VERSION "j1939-2025-03-v2.4-light"

NS_ :

BS_:

BU_:

BO_ 2566799614 LD: 8 Vector__XXX
 SG_ AlternateBeamHeadLightData : 2|2@1+ (1,0) [0|3] "" Vector__XXX
 SG_ BackUpLightAndAlarmHorn : 16|2@1+ (1,0) [0|3] "" Vector__XXX
 SG_ CenterStopLight : 18|2@1+ (1,0) [0|3] "" Vector__XXX
 SG_ HighBeamHeadLightData : 6|2@1+ (1,0) [0|3] "" Vector__XXX
 SG_ ImplementClearanceLight : 24|2@1+ (1,0) [0|3] "" Vector__XXX
 SG_ ImplementLeftFacingWorkLight : 60|2@1+ (1,0) [0|3] "" Vector__XXX
 SG_ ImplementLeftForwardWorkLight : 54|2@1+ (1,0) [0|3] "" Vector__XXX
 SG_ ImplementMarkerLight : 28|2@1+ (1,0) [0|3] "" Vector__XXX
 SG_ ImplementOemOption1Light : 50|2@1+ (1,0) [0|3] "" Vector__XXX
 SG_ ImplementOemOption2Light : 48|2@1+ (1,0) [0|3] "" Vector__XXX
 SG_ ImplementRearWorkLight : 62|2@1+ (1,0) [0|3] "" Vector__XXX
 SG_ ImplementRightFacingWorkLight : 52|2@1+ (1,0) [0|3] "" Vector__XXX
 SG_ ImplementRightForwardWorkLight : 58|2@1+ (1,0) [0|3] "" Vector__XXX
 SG_ LeftStopLight : 22|2@1+ (1,0) [0|3] "" Vector__XXX
 SG_ LeftTurnSignalLights : 14|2@1+ (1,0) [0|3] "" Vector__XXX
 SG_ LowBeamHeadLightData : 4|2@1+ (1,0) [0|3] "" Vector__XXX
 SG_ RearFogLights : 32|2@1+ (1,0) [0|3] "" Vector__XXX
 SG_ RightStopLight : 20|2@1+ (1,0) [0|3] "" Vector__XXX
 SG_ RightTurnSignalLights : 12|2@1+ (1,0) [0|3] "" Vector__XXX
 SG_ RotatingBeaconLight : 10|2@1+ (1,0) [0|3] "" Vector__XXX
 SG_ RunningLight : 0|2@1+ (1,0) [0|3] "" Vector__XXX
 SG_ TractorClearanceLight : 26|2@1+ (1,0) [0|3] "" Vector__XXX
 SG_ TractorFrontFogLights : 8|2@1+ (1,0) [0|3] "" Vector__XXX
 SG_ TractorMarkerLight : 30|2@1+ (1,0) [0|3] "" Vector__XXX
 SG_ TractorRearLowMountedWorkLights : 36|2@1+ (1,0) [0|3] "" Vector__XXX
 SG_ TractorSideLowMountedWorkLights : 40|2@1+ (1,0) [0|3] "" Vector__XXX
 SG_ TrtrFrntHghMntdWrkLghts : 46|2@1+ (1,0) [0|3] "" Vector__XXX
 SG_ TrtrFrntLwMntdWrkLghts : 44|2@1+ (1,0) [0|3] "" Vector__XXX
 SG_ TrtrRrHghMntdWrkLghts : 38|2@1+ (1,0) [0|3] "" Vector__XXX
 SG_ TrtrSdHghMntdWrkLghts : 42|2@1+ (1,0) [0|3] "" Vector__XXX
 SG_ TrtrUndrsdMntdWrkLghts : 34|2@1+ (1,0) [0|3] "" Vector__XXX

BO_ 2566802174 ETC7: 8 Vector__XXX
 SG_ ActiveShiftConsoleIndicator : 10|2@1+ (1,0) [0|3] "" Vector__XXX
 SG_ TransmissionEngineCrankEnable : 12|2@1+ (1,0) [0|3] "" Vector__XXX
 SG_ TransmissionManualModeIndicator : 54|2@1+ (1,0) [0|3] "" Vector__XXX
 SG_ TransmissionMode10Indicator : 46|2@1+ (1,0) [0|3] "" Vector__XXX
 SG_ TransmissionMode1Indicator : 22|2@1+ (1,0) [0|3] "" Vector__XXX
 SG_ TransmissionMode2Indicator : 20|2@1+ (1,0) [0|3] "" Vector__XXX
 SG_ TransmissionMode3Indicator : 18|2@1+ (1,0) [0|3] "" Vector__XXX
 SG_ TransmissionMode4Indicator : 16|2@1+ (1,0) [0|3] "" Vector__XXX
 SG_ TransmissionMode5Indicator : 32|2@1+ (1,0) [0|3] "" Vector__XXX
 SG_ TransmissionMode6Indicator : 34|2@1+ (1,0) [0|3] "" Vector__XXX
 SG_ TransmissionMode7Indicator : 36|2@1+ (1,0) [0|3] "" Vector__XXX
 SG_ TransmissionMode8Indicator : 38|2@1+ (1,0) [0|3] "" Vector__XXX
 SG_ TransmissionMode9Indicator : 44|2@1+ (1,0) [0|3] "" Vector__XXX
 SG_ TransmissionServiceIndicator : 2|2@1+ (1,0) [0|3] "" Vector__XXX
 SG_ TransmissionWarningIndicator : 42|2@1+ (1,0) [0|3] "" Vector__XXX
 SG_ TrnsmssnArSpplPrssrIndtr : 48|3@1+ (1,0) [0|7] "" Vector__XXX
 SG_ TrnsmssnAtNtrlMnlRtrnStt : 51|3@1+ (1,0) [0|7] "" Vector__XXX
 SG_ TrnsmssnCrrntRngDsplBlnkStt : 0|2@1+ (1,0) [0|3] "" Vector__XXX
 SG_ TrnsmssnRdFrBrkRls : 8|2@1+ (1,0) [0|3] "" Vector__XXX
 SG_ TrnsmssnRqstdGrFdk : 24|8@1+ (1,-125) [-125|125] "gear value" Vector__XXX
 SG_ TrnsmssnRqstdRngDsplBlnkStt : 4|2@1+ (1,0) [0|3] "" Vector__XXX
 SG_ TrnsmssnRqstdRngDsplFlshStt : 6|2@1+ (1,0) [0|3] "" Vector__XXX
 SG_ TrnsmssnRvrsGrShftInhtStts : 40|2@1+ (1,0) [0|3] "" Vector__XXX
 SG_ TrnsmssnShftInhtIndtr : 14|2@1+ (1,0) [0|3] "" Vector__XXX
 SG_ TrnsmssnLdRdtnIndtr : 56|2@1+ (1,0) [0|3] "" Vector__XXX
 SG_ TrnsmssnPrDfndRngLmtIndtr : 58|2@1+ (1,0) [0|3] "" Vector__XXX
 SG_ TransmissionCoastModeIndicator : 60|2@1+ (1,0) [0|3] "" Vector__XXX
 SG_ TrnsmssnOtptShftBrkIndtr : 62|2@1+ (1,0) [0|3] "" Vector__XXX

BO_ 2566802430 TCFG2: 8 Vector__XXX
 SG_ TransmissionReferenceTorque : 16|16@1+ (1,0) [0|64255] "Nm" Vector__XXX
 SG_ TransmissionTorqueLimit : 0|16@1+ (1,0) [0|64255] "Nm" Vector__XXX
 SG_ TrnsmssnCmmntnsFlrIdlTrqLmt : 32|8@1+ (1,-125) [0|125] "%" Vector__XXX
 SG_ TransmissionShiftSelectorType : 40|3@1+ (1,0) [0|7] "" Vector__XXX
 SG_ TransmissionSpeedLimit : 48|16@1+ (0.125,0) [0|8031.875] "rpm" Vector__XXX

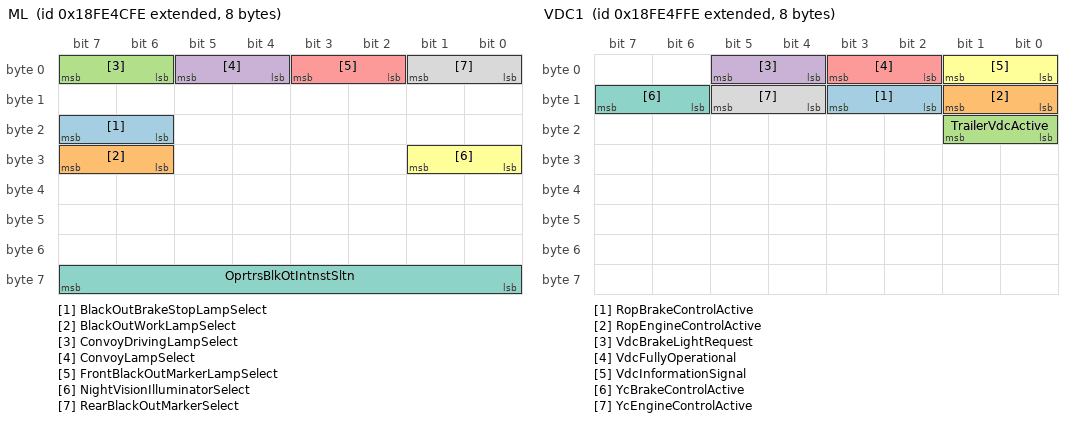
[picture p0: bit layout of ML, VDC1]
BO_ 2566802686 ML: 8 Vector__XXX
 SG_ BlackOutBrakeStopLampSelect : 22|2@1+ (1,0) [0|3] "" Vector__XXX
 SG_ BlackOutWorkLampSelect : 30|2@1+ (1,0) [0|3] "" Vector__XXX
 SG_ ConvoyDrivingLampSelect : 6|2@1+ (1,0) [0|3] "" Vector__XXX
 SG_ ConvoyLampSelect : 4|2@1+ (1,0) [0|3] "" Vector__XXX
 SG_ FrontBlackOutMarkerLampSelect : 2|2@1+ (1,0) [0|3] "" Vector__XXX
 SG_ NightVisionIlluminatorSelect : 24|2@1+ (1,0) [0|3] "" Vector__XXX
 SG_ OprtrsBlkOtIntnstSltn : 56|8@1+ (0.4,0) [0|100] "%" Vector__XXX
 SG_ RearBlackOutMarkerSelect : 0|2@1+ (1,0) [0|3] "" Vector__XXX

BO_ 2566803198 DC1: 8 Vector__XXX
 SG_ PositionOfDoors : 0|4@1+ (1,0) [0|15] "" Vector__XXX
 SG_ RampWheelChairLiftPosition : 4|2@1+ (1,0) [0|3] "" Vector__XXX
 SG_ Status2OfDoors : 6|2@1+ (1,0) [0|3] "" Vector__XXX

BO_ 2566803454 VDC1: 8 Vector__XXX
 SG_ RopBrakeControlActive : 10|2@1+ (1,0) [0|3] "" Vector__XXX
 SG_ RopEngineControlActive : 8|2@1+ (1,0) [0|3] "" Vector__XXX
 SG_ TrailerVdcActive : 16|2@1+ (1,0) [0|3] "" Vector__XXX
 SG_ VdcBrakeLightRequest : 4|2@1+ (1,0) [0|3] "" Vector__XXX
 SG_ VdcFullyOperational : 2|2@1+ (1,0) [0|3] "" Vector__XXX
 SG_ VdcInformationSignal : 0|2@1+ (1,0) [0|3] "" Vector__XXX
 SG_ YcBrakeControlActive : 14|2@1+ (1,0) [0|3] "" Vector__XXX
 SG_ YcEngineControlActive : 12|2@1+ (1,0) [0|3] "" Vector__XXX

BO_ 2566803710 BT1: 8 Vector__XXX
 SG_ SliBattery1Temperature : 0|8@1+ (1,-40) [-40|210] "degC" Vector__XXX
 SG_ SliBattery2Temperature : 8|8@1+ (1,-40) [-40|210] "degC" Vector__XXX
 SG_ SliBattery3Temperature : 16|8@1+ (1,-40) [-40|210] "degC" Vector__XXX
 SG_ SliBattery4Temperature : 24|8@1+ (1,-40) [-40|210] "degC" Vector__XXX

BO_ 2566803966 ACC2: 8 Vector__XXX
 SG_ AccUsageDemand : 0|2@1+ (1,0) [0|3] "" Vector__XXX
 SG_ RequestedAccDistanceMode : 5|3@1+ (1,0) [0|7] "" Vector__XXX

BO_ 2566804222 VEP3: 8 Vector__XXX
 SG_ AltrntrCrrntHghRngRsltn : 0|16@1+ (0.05,-1600) [-1600|1612.75] "A" Vector__XXX
 SG_ SliBattery2NetCurrent : 32|16@1+ (0.05,-1600) [-1600|1612.75] "A" Vector__XXX
 SG_ SlBttr1NtCrrntHghRngRsltn : 16|16@1+ (0.05,-1600) [-1600|1612.75] "A" Vector__XXX
 SG_ EcuKeySwitchState : 48|2@1+ (1,0) [0|3] "" Vector__XXX

BO_ 2566804478 RTC1: 8 Vector__XXX
 SG_ LwLmtThrshldFrMxmmRpmFrmRtrdr : 0|8@1+ (32,0) [0|8000] "rpm" Vector__XXX
 SG_ LwLmtThrshldFrMxmmTrqFrmRtrdr : 16|8@1+ (1,-125) [-125|125] "%" Vector__XXX
 SG_ MaximumContinuousRetarderSpeed : 32|8@1+ (32,0) [0|8000] "rpm" Vector__XXX
 SG_ MaximumContinuousRetarderTorque : 48|8@1+ (1,-125) [-125|125] "%" Vector__XXX
 SG_ MinimumContinuousRetarderSpeed : 40|8@1+ (32,0) [0|8000] "rpm" Vector__XXX
 SG_ MinimumContinuousRetarderTorque : 56|8@1+ (1,-125) [-125|125] "%" Vector__XXX
 SG_ HLtTsdFMCtsRpFRtd : 8|8@1+ (32,0) [0|8000] "rpm" Vector__XXX
 SG_ HLtTsdFMCtsTqFRtd : 24|8@1+ (1,-125) [-125|125] "%" Vector__XXX

BO_ 2566804734 ECT1: 8 Vector__XXX
 SG_ EngineMaximumContinuousRpm : 32|8@1+ (32,0) [0|8000] "rpm" Vector__XXX
 SG_ EngineMaximumContinuousTorque : 48|8@1+ (1,-125) [-125|125] "%" Vector__XXX
 SG_ EngineMinimumContinuousRpm : 40|8@1+ (32,0) [0|8000] "rpm" Vector__XXX
 SG_ EngineMinimumContinuousTorque : 56|8@1+ (1,-125) [-125|125] "%" Vector__XXX
 SG_ ELwLtTsdFMxRpFE : 0|8@1+ (32,0) [0|8000] "rpm" Vector__XXX
 SG_ EHLtTsdFMCtsERp : 8|8@1+ (32,0) [0|8000] "rpm" Vector__XXX
 SG_ ELwLtTsdFMxTqFE : 16|8@1+ (1,-125) [-125|125] "%" Vector__XXX
 SG_ EHLtTsdFMCtsTqFE : 24|8@1+ (1,-125) [-125|125] "%" Vector__XXX

BO_ 2566804990 GFD: 8 Vector__XXX
 SG_ FuelEnergyContent : 32|16@1+ (0.00390625,0) [0|250.99609375] "MJ/(Nm*Nm*Nm)" Vector__XXX
 SG_ ReferenceEngineGasMassFlowRate : 16|16@1+ (0.05,0) [0|3212.75] "kg/h" Vector__XXX
 SG_ SpecificHeatRatio : 0|16@1+ (0.001,0) [0|2] "" Vector__XXX

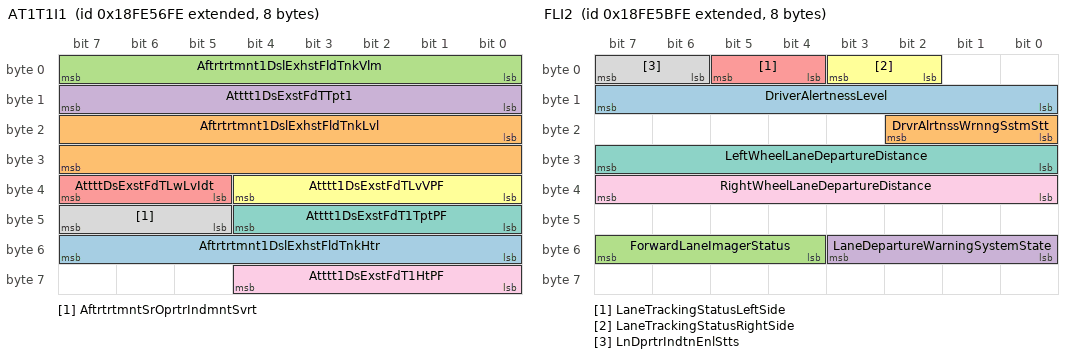
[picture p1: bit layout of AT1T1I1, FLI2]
BO_ 2566805246 AT1T1I1: 8 Vector__XXX
 SG_ Aftrtrtmnt1DslExhstFldTnkHtr : 48|8@1+ (0.4,0) [0|100] "%" Vector__XXX
 SG_ Aftrtrtmnt1DslExhstFldTnkLvl : 16|16@1+ (0.1,0) [0|6425.5] "mm" Vector__XXX
 SG_ Aftrtrtmnt1DslExhstFldTnkVlm : 0|8@1+ (0.4,0) [0|100] "%" Vector__XXX
 SG_ Atttt1DsExstFdTTpt1 : 8|8@1+ (1,-40) [-40|210] "degC" Vector__XXX
 SG_ AttttDsExstFdTLwLvIdt : 37|3@1+ (1,0) [0|7] "" Vector__XXX
 SG_ Atttt1DsExstFdTLvVPF : 32|5@1+ (1,0) [0|31] "" Vector__XXX
 SG_ Atttt1DsExstFdT1TptPF : 40|5@1+ (1,0) [0|31] "" Vector__XXX
 SG_ AftrtrtmntSrOprtrIndmntSvrt : 45|3@1+ (1,0) [0|7] "" Vector__XXX
 SG_ Atttt1DsExstFdT1HtPF : 56|5@1+ (1,0) [0|31] "" Vector__XXX

BO_ 2566805758 ASC4: 8 Vector__XXX
 SG_ BellowPressureFrontAxleLeft : 0|16@1+ (0.1,0) [0|6425.5] "kPa" Vector__XXX
 SG_ BellowPressureFrontAxleRight : 16|16@1+ (0.1,0) [0|6425.5] "kPa" Vector__XXX
 SG_ BellowPressureRearAxleLeft : 32|16@1+ (0.1,0) [0|6425.5] "kPa" Vector__XXX
 SG_ BellowPressureRearAxleRight : 48|16@1+ (0.1,0) [0|6425.5] "kPa" Vector__XXX

BO_ 2566806014 ASC3: 8 Vector__XXX
 SG_ RelativeLevelFrontAxleLeft : 0|16@1+ (0.1,-3200) [-3200|3225.5] "mm" Vector__XXX
 SG_ RelativeLevelFrontAxleRight : 16|16@1+ (0.1,-3200) [-3200|3225.5] "mm" Vector__XXX
 SG_ RelativeLevelRearAxleLeft : 32|16@1+ (0.1,-3200) [-3200|3225.5] "mm" Vector__XXX
 SG_ RelativeLevelRearAxleRight : 48|16@1+ (0.1,-3200) [-3200|3225.5] "mm" Vector__XXX

BO_ 2566806526 FLI2: 8 Vector__XXX
 SG_ DriverAlertnessLevel : 8|8@1+ (0.4,0) [0|100] "%" Vector__XXX
 SG_ DrvrAlrtnssWrnngSstmStt : 16|3@1+ (1,0) [0|7] "" Vector__XXX
 SG_ ForwardLaneImagerStatus : 52|4@1+ (1,0) [0|15] "" Vector__XXX
 SG_ LaneDepartureWarningSystemState : 48|4@1+ (1,0) [0|15] "" Vector__XXX
 SG_ LaneTrackingStatusLeftSide : 4|2@1+ (1,0) [0|3] "" Vector__XXX
 SG_ LaneTrackingStatusRightSide : 2|2@1+ (1,0) [0|3] "" Vector__XXX
 SG_ LeftWheelLaneDepartureDistance : 24|8@1+ (1,-125) [-125|125] "cm" Vector__XXX
 SG_ LnDprtrIndtnEnlStts : 6|2@1+ (1,0) [0|3] "" Vector__XXX
 SG_ RightWheelLaneDepartureDistance : 32|8@1+ (1,-125) [-125|125] "cm" Vector__XXX

BO_ 2566809342 BM: 8 Vector__XXX
 SG_ BatteryMainSwitchHoldState : 0|2@1+ (1,0) [0|3] "" Vector__XXX

BO_ 2566809598 CCC: 8 Vector__XXX
 SG_ AxlrHtrMxmmOtptPwr : 0|16@1+ (2,0) [0|128510] "W" Vector__XXX

BO_ 2566809854 VF: 8 Vector__XXX
 SG_ HdrlOlFltrRstrtnSwth : 8|2@1+ (1,0) [0|3] "" Vector__XXX
 SG_ HydraulicOilLevel : 16|8@1+ (0.4,0) [0|100] "%" Vector__XXX
 SG_ HydraulicTemperature : 0|8@1+ (1,-40) [-40|210] "degC" Vector__XXX
 SG_ WinchOilPressureSwitch : 10|2@1+ (1,0) [0|3] "" Vector__XXX

BO_ 2566810110 ET3: 8 Vector__XXX
 SG_ EngnChrgArClr1OtltTmprtr : 48|16@1+ (0.03125,-273) [-273|1734.96875] "degC" Vector__XXX
 SG_ EngnClntTmprtrHghRsltn : 16|16@1+ (0.03125,-273) [-273|1734.96875] "degC" Vector__XXX
 SG_ EngnIntkMnfld1TmprtrHghRsltn : 0|16@1+ (0.03125,-273) [-273|1734.96875] "degC" Vector__XXX
 SG_ EngnIntkVlvAttnSstmOlTmprtr : 32|16@1+ (0.03125,-273) [-273|1734.96875] "degC" Vector__XXX

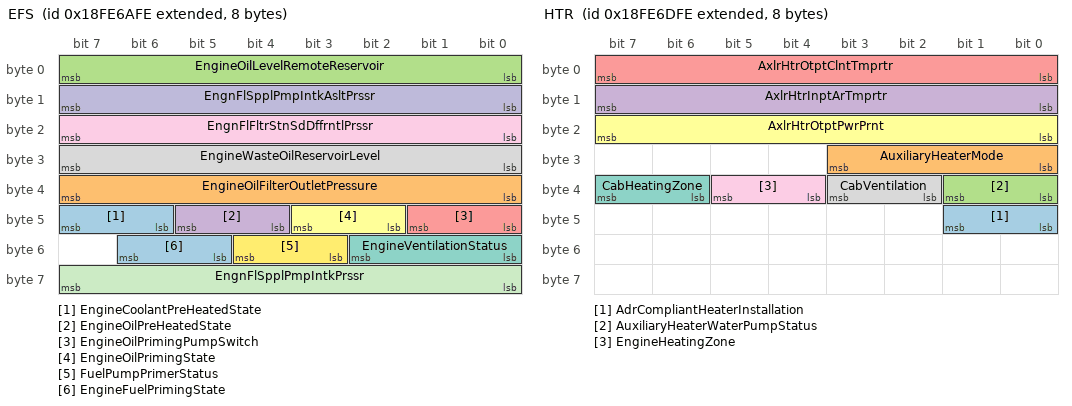
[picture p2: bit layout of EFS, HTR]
BO_ 2566810366 EFS: 8 Vector__XXX
 SG_ EngineCoolantPreHeatedState : 46|2@1+ (1,0) [0|3] "" Vector__XXX
 SG_ EngineOilFilterOutletPressure : 32|8@1+ (4,0) [0|1000] "kPa" Vector__XXX
 SG_ EngineOilLevelRemoteReservoir : 0|8@1+ (0.4,0) [0|100] "%" Vector__XXX
 SG_ EngineOilPreHeatedState : 44|2@1+ (1,0) [0|3] "" Vector__XXX
 SG_ EngineOilPrimingPumpSwitch : 40|2@1+ (1,0) [0|3] "" Vector__XXX
 SG_ EngineOilPrimingState : 42|2@1+ (1,0) [0|3] "" Vector__XXX
 SG_ EngineVentilationStatus : 48|3@1+ (1,0) [0|7] "" Vector__XXX
 SG_ EngineWasteOilReservoirLevel : 24|8@1+ (0.4,0) [0|100] "%" Vector__XXX
 SG_ EngnFlFltrStnSdDffrntlPrssr : 16|8@1+ (2,0) [0|500] "kPa" Vector__XXX
 SG_ EngnFlSpplPmpIntkAsltPrssr : 8|8@1+ (2,0) [0|500] "kPa" Vector__XXX
 SG_ EngnFlSpplPmpIntkPrssr : 56|8@1+ (2,0) [0|500] "kPa" Vector__XXX
 SG_ FuelPumpPrimerStatus : 51|2@1+ (1,0) [0|3] "" Vector__XXX
 SG_ EngineFuelPrimingState : 53|2@1+ (1,0) [0|3] "" Vector__XXX

BO_ 2566811134 HTR: 8 Vector__XXX
 SG_ AdrCompliantHeaterInstallation : 40|2@1+ (1,0) [0|3] "" Vector__XXX
 SG_ AuxiliaryHeaterMode : 24|4@1+ (1,0) [0|15] "" Vector__XXX
 SG_ AuxiliaryHeaterWaterPumpStatus : 32|2@1+ (1,0) [0|3] "" Vector__XXX
 SG_ AxlrHtrInptArTmprtr : 8|8@1+ (1,-40) [-40|210] "degC" Vector__XXX
 SG_ AxlrHtrOtptClntTmprtr : 0|8@1+ (1,-40) [-40|210] "degC" Vector__XXX
 SG_ AxlrHtrOtptPwrPrnt : 16|8@1+ (0.4,0) [0|100] "%" Vector__XXX
 SG_ CabHeatingZone : 38|2@1+ (1,0) [0|3] "" Vector__XXX
 SG_ CabVentilation : 34|2@1+ (1,0) [0|3] "" Vector__XXX
 SG_ EngineHeatingZone : 36|2@1+ (1,0) [0|3] "" Vector__XXX

BO_ 2566811902 CVW: 8 Vector__XXX
 SG_ GrossCombinationVehicleWeight : 16|16@1+ (10,0) [0|642550] "kg" Vector__XXX
 SG_ PoweredVehicleWeight : 0|16@1+ (10,0) [0|642550] "kg" Vector__XXX
 SG_ GrssCmntnVhlWghtCnfdn : 32|8@1+ (0.5,0) [0|100] "%" Vector__XXX

BO_ 2566819326 VEP2: 8 Vector__XXX
 SG_ BatteryPotentialPowerInput2 : 0|16@1+ (0.05,0) [0|3212.75] "V" Vector__XXX
 SG_ EcuPowerOutputSupplyVoltage1 : 16|16@1+ (0.05,0) [0|3212.75] "V" Vector__XXX
 SG_ EcuPowerOutputSupplyVoltage2 : 32|16@1+ (0.05,0) [0|3212.75] "V" Vector__XXX
 SG_ EcuPowerOutputSupplyVoltage3 : 48|16@1+ (0.05,0) [0|3212.75] "V" Vector__XXX

BO_ 2566819838 SP2: 8 Vector__XXX
 SG_ EngnExtrnlShtdwnArSpplPrssr : 0|16@1+ (0.5,0) [0|32127.5] "kPa" Vector__XXX

BO_ 2566820094 ETH: 33 Vector__XXX
 SG_ CalibrationRecordDurationTime : 80|32@1+ (0.05,0) [0|210554060.75] "h" Vector__XXX
 SG_ CalibrationRecordStartDay : 64|8@1+ (0.25,0) [0.25|31.75] "days" Vector__XXX
 SG_ CalibrationRecordStartMonth : 56|8@1+ (1,0) [1|12] "month" Vector__XXX
 SG_ CalibrationRecordStartYear : 72|8@1+ (1,1985) [1985|2235] "year" Vector__XXX
 SG_ EnginePeakTorque1 : 24|16@1+ (1,0) [0|64255] "Nm" Vector__XXX
 SG_ EnginePeakTorque2 : 40|16@1+ (1,0) [0|64255] "Nm" Vector__XXX
 SG_ EnginePower : 8|16@1+ (0.5,0) [0|32127.5] "kW" Vector__XXX
 SG_ EngineTorqueLimit1Transmission : 136|16@1+ (1,0) [0|64255] "Nm" Vector__XXX
 SG_ EngineTorqueLimit2Transmission : 168|16@1+ (1,0) [0|64255] "Nm" Vector__XXX
 SG_ EngineTorqueLimit3Transmission : 200|16@1+ (1,0) [0|64255] "Nm" Vector__XXX
 SG_ EngineTorqueLimit4Transmission : 216|16@1+ (1,0) [0|64255] "Nm" Vector__XXX
 SG_ EngineTorqueLimit5Switch : 232|16@1+ (1,0) [0|64255] "Nm" Vector__XXX
 SG_ EngineTorqueLimit6AxleInput : 248|16@1+ (2,0) [0|128510] "Nm" Vector__XXX
 SG_ EngineTorqueLimitFeature : 114|3@1+ (1,0) [0|7] "" Vector__XXX
 SG_ TorqueLimitingFeatureStatus : 112|2@1+ (1,0) [0|3] "" Vector__XXX
 SG_ TransmissionGearRatio1 : 120|16@1+ (0.01,0) [0|642.55] "" Vector__XXX
 SG_ TransmissionGearRatio2 : 152|16@1+ (0.01,0) [0|642.55] "" Vector__XXX
 SG_ TransmissionGearRatio3 : 184|16@1+ (0.01,0) [0|642.55] "" Vector__XXX
 SG_ NmrOfEngnTrqHstrRrds : 0|8@1+ (1,0) [0|250] "Record" Vector__XXX

BO_ 2566821118 EAC: 8 Vector__XXX
 SG_ EngineAuxiliaryCoolantPressure : 0|8@1+ (4,0) [0|1000] "kPa" Vector__XXX
 SG_ EngnAxlrClntTmprtr : 8|8@1+ (1,-40) [-40|210] "degC" Vector__XXX
 SG_ EngnClntPmpClntOtltPrssr : 40|8@1+ (2,0) [0|500] "kPa" Vector__XXX
 SG_ EngnClntPrssr1ExtnddRng : 24|8@1+ (4,0) [0|1000] "kPa" Vector__XXX
 SG_ EngnClntPrssr2ExtnddRng : 32|8@1+ (4,0) [0|1000] "kPa" Vector__XXX
 SG_ SeaWaterPumpOutletPressure : 16|8@1+ (2,0) [0|500] "kPa" Vector__XXX
 SG_ SeaWaterPumpOutletPressure2 : 48|8@1+ (2,0) [0|500] "kPa" Vector__XXX
 SG_ EngnAftrlrClntOtltPrssr : 56|8@1+ (4,0) [0|1000] "kPa" Vector__XXX

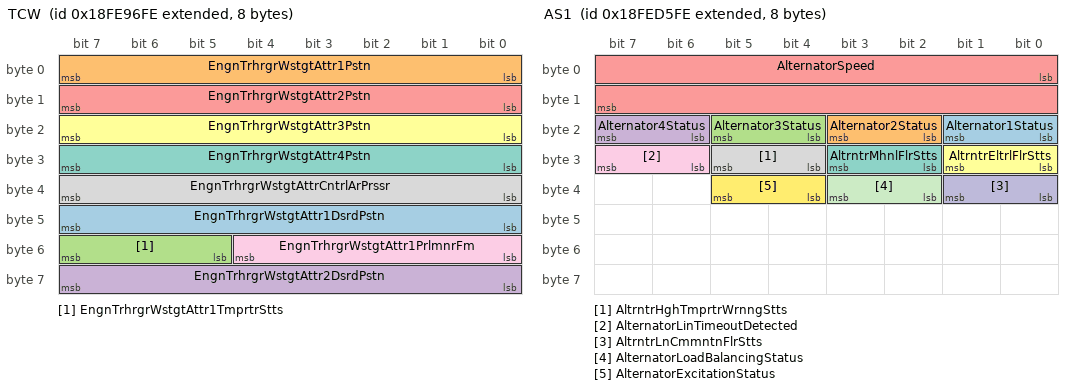
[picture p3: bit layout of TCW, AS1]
BO_ 2566821630 TCW: 8 Vector__XXX
 SG_ EngnTrhrgrWstgtAttr1DsrdPstn : 40|8@1+ (0.4,0) [0|100] "%" Vector__XXX
 SG_ EngnTrhrgrWstgtAttr1Pstn : 0|8@1+ (0.4,0) [0|100] "%" Vector__XXX
 SG_ EngnTrhrgrWstgtAttr1TmprtrStts : 53|3@1+ (1,0) [0|7] "" Vector__XXX
 SG_ EngnTrhrgrWstgtAttr2DsrdPstn : 56|8@1+ (0.4,0) [0|100] "%" Vector__XXX
 SG_ EngnTrhrgrWstgtAttr2Pstn : 8|8@1+ (0.4,0) [0|100] "%" Vector__XXX
 SG_ EngnTrhrgrWstgtAttr3Pstn : 16|8@1+ (0.4,0) [0|100] "%" Vector__XXX
 SG_ EngnTrhrgrWstgtAttr4Pstn : 24|8@1+ (0.4,0) [0|100] "%" Vector__XXX
 SG_ EngnTrhrgrWstgtAttrCntrlArPrssr : 32|8@1+ (4,0) [0|1000] "kPa" Vector__XXX
 SG_ EngnTrhrgrWstgtAttr1PrlmnrFm : 48|5@1+ (1,0) [0|31] "" Vector__XXX

BO_ 2566821886 TCI5: 8 Vector__XXX
 SG_ EngnTrhrgr1TrnOtltTmprtr : 0|16@1+ (0.03125,-273) [-273|1734.96875] "degC" Vector__XXX
 SG_ EngnTrhrgr2TrnOtltTmprtr : 16|16@1+ (0.03125,-273) [-273|1734.96875] "degC" Vector__XXX
 SG_ EngnTrhrgr3TrnOtltTmprtr : 32|16@1+ (0.03125,-273) [-273|1734.96875] "degC" Vector__XXX
 SG_ EngnTrhrgr4TrnOtltTmprtr : 48|16@1+ (0.03125,-273) [-273|1734.96875] "degC" Vector__XXX

BO_ 2566822142 TCI4: 8 Vector__XXX
 SG_ EngnTrhrgr1TrnIntkTmprtr : 0|16@1+ (0.03125,-273) [-273|1734.96875] "degC" Vector__XXX
 SG_ EngnTrhrgr2TrnIntkTmprtr : 16|16@1+ (0.03125,-273) [-273|1734.96875] "degC" Vector__XXX
 SG_ EngnTrhrgr3TrnIntkTmprtr : 32|16@1+ (0.03125,-273) [-273|1734.96875] "degC" Vector__XXX
 SG_ EngnTrhrgr4TrnIntkTmprtr : 48|16@1+ (0.03125,-273) [-273|1734.96875] "degC" Vector__XXX

BO_ 2566822398 TCI3: 8 Vector__XXX
 SG_ EngnTrhrgr1CmprssrIntkPrssr : 0|16@1+ (0.0078125,-250) [-250|251.9921875] "kPa" Vector__XXX
 SG_ EngnTrhrgr2CmprssrIntkPrssr : 16|16@1+ (0.0078125,-250) [-250|251.9921875] "kPa" Vector__XXX
 SG_ EngnTrhrgr3CmprssrIntkPrssr : 32|16@1+ (0.0078125,-250) [-250|251.9921875] "kPa" Vector__XXX
 SG_ EngnTrhrgr4CmprssrIntkPrssr : 48|16@1+ (0.0078125,-250) [-250|251.9921875] "kPa" Vector__XXX

BO_ 2566822654 TCI2: 8 Vector__XXX
 SG_ EngnTrhrgr1CmprssrIntkTmprtr : 0|16@1+ (0.03125,-273) [-273|1734.96875] "degC" Vector__XXX
 SG_ EngnTrhrgr2CmprssrIntkTmprtr : 16|16@1+ (0.03125,-273) [-273|1734.96875] "degC" Vector__XXX
 SG_ EngnTrhrgr3CmprssrIntkTmprtr : 32|16@1+ (0.03125,-273) [-273|1734.96875] "degC" Vector__XXX
 SG_ EngnTrhrgr4CmprssrIntkTmprtr : 48|16@1+ (0.03125,-273) [-273|1734.96875] "degC" Vector__XXX

BO_ 2566823166 MBT3: 8 Vector__XXX
 SG_ EngineMainBearing10Temperature : 16|16@1+ (0.03125,-273) [-273|1734.96875] "degC" Vector__XXX
 SG_ EngineMainBearing11Temperature : 32|16@1+ (0.03125,-273) [-273|1734.96875] "degC" Vector__XXX
 SG_ EngineMainBearing12Temperature : 48|16@1+ (0.03125,-273) [-273|1734.96875] "degC" Vector__XXX
 SG_ EngineMainBearing9Temperature : 0|16@1+ (0.03125,-273) [-273|1734.96875] "degC" Vector__XXX

BO_ 2566823422 MBT2: 8 Vector__XXX
 SG_ EngineMainBearing5Temperature : 0|16@1+ (0.03125,-273) [-273|1734.96875] "degC" Vector__XXX
 SG_ EngineMainBearing6Temperature : 16|16@1+ (0.03125,-273) [-273|1734.96875] "degC" Vector__XXX
 SG_ EngineMainBearing7Temperature : 32|16@1+ (0.03125,-273) [-273|1734.96875] "degC" Vector__XXX
 SG_ EngineMainBearing8Temperature : 48|16@1+ (0.03125,-273) [-273|1734.96875] "degC" Vector__XXX

BO_ 2566823678 MBT1: 8 Vector__XXX
 SG_ EngineMainBearing1Temperature : 0|16@1+ (0.03125,-273) [-273|1734.96875] "degC" Vector__XXX
 SG_ EngineMainBearing2Temperature : 16|16@1+ (0.03125,-273) [-273|1734.96875] "degC" Vector__XXX
 SG_ EngineMainBearing3Temperature : 32|16@1+ (0.03125,-273) [-273|1734.96875] "degC" Vector__XXX
 SG_ EngineMainBearing4Temperature : 48|16@1+ (0.03125,-273) [-273|1734.96875] "degC" Vector__XXX

BO_ 2566824190 EPT4: 8 Vector__XXX
 SG_ EngnExhstGsPrt13Tmprtr : 0|16@1+ (0.03125,-273) [-273|1734.96875] "degC" Vector__XXX
 SG_ EngnExhstGsPrt14Tmprtr : 16|16@1+ (0.03125,-273) [-273|1734.96875] "degC" Vector__XXX
 SG_ EngnExhstGsPrt15Tmprtr : 32|16@1+ (0.03125,-273) [-273|1734.96875] "degC" Vector__XXX
 SG_ EngnExhstGsPrt16Tmprtr : 48|16@1+ (0.03125,-273) [-273|1734.96875] "degC" Vector__XXX

BO_ 2566825214 ET2: 8 Vector__XXX
 SG_ EngineEcuTemperature : 16|16@1+ (0.03125,-273) [-273|1734.96875] "degC" Vector__XXX
 SG_ EngineOilTemperature2 : 0|16@1+ (0.03125,-273) [-273|1734.96875] "degC" Vector__XXX
 SG_ EngnExhstGsRrltn1DffrntlPrssr : 32|16@1+ (0.0078125,-250) [-250|251.9921875] "kPa" Vector__XXX
 SG_ EngnExhstGsRrltn1Tmprtr : 48|16@1+ (0.03125,-273) [-273|1734.96875] "degC" Vector__XXX

BO_ 2566825726 IMT1: 8 Vector__XXX
 SG_ EngnTrhrgr1BstPrssr : 0|16@1+ (0.125,0) [0|8031.875] "kPa" Vector__XXX
 SG_ EngnTrhrgr2BstPrssr : 16|16@1+ (0.125,0) [0|8031.875] "kPa" Vector__XXX
 SG_ EngnTrhrgr3BstPrssr : 32|16@1+ (0.125,0) [0|8031.875] "kPa" Vector__XXX
 SG_ EngnTrhrgr4BstPrssr : 48|16@1+ (0.125,0) [0|8031.875] "kPa" Vector__XXX

BO_ 2566827518 EBC3: 8 Vector__XXX
 SG_ BApptPssHRFtAxLtW : 0|8@1+ (5,0) [0|1250] "kPa" Vector__XXX
 SG_ BApptPssHRFtAxRtW : 8|8@1+ (5,0) [0|1250] "kPa" Vector__XXX
 SG_ BApptPssHRRAx1LtW : 16|8@1+ (5,0) [0|1250] "kPa" Vector__XXX
 SG_ BApptPssHRRAx1RtW : 24|8@1+ (5,0) [0|1250] "kPa" Vector__XXX
 SG_ BApptPssHRRAx2LtW : 32|8@1+ (5,0) [0|1250] "kPa" Vector__XXX
 SG_ BApptPssHRRAx2RtW : 40|8@1+ (5,0) [0|1250] "kPa" Vector__XXX
 SG_ BApptPssHRRAx3LtW : 48|8@1+ (5,0) [0|1250] "kPa" Vector__XXX
 SG_ BApptPssHRRAx3RtW : 56|8@1+ (5,0) [0|1250] "kPa" Vector__XXX

BO_ 2566827774 AIR1: 8 Vector__XXX
 SG_ AirCompressorStatus : 48|2@1+ (1,0) [0|3] "" Vector__XXX
 SG_ AxlrEqpmntSpplPrssr : 32|8@1+ (8,0) [0|2000] "kPa" Vector__XXX
 SG_ ParkingAndOrTrailerAirPressure : 8|8@1+ (8,0) [0|2000] "kPa" Vector__XXX
 SG_ PneumaticSupplyPressure : 0|8@1+ (8,0) [0|2000] "kPa" Vector__XXX
 SG_ PwrtrnCrtArSpplPrssr : 56|8@1+ (8,0) [0|2000] "kPa" Vector__XXX
 SG_ ServiceBrakeCircuit1AirPressure : 16|8@1+ (8,0) [0|2000] "kPa" Vector__XXX
 SG_ ServiceBrakeCircuit2AirPressure : 24|8@1+ (8,0) [0|2000] "kPa" Vector__XXX
 SG_ AirSuspensionSupplyPressure1 : 40|8@1+ (8,0) [0|2000] "kPa" Vector__XXX

BO_ 2566831614 FD1: 8 Vector__XXX
 SG_ EngineFan1EstimatedPercentSpeed : 0|8@1+ (0.4,0) [0|100] "%" Vector__XXX
 SG_ FanDriveBypassCommandStatus : 48|8@1+ (0.4,0) [0|100] "%" Vector__XXX
 SG_ FanDriveState : 8|4@1+ (1,0) [0|15] "" Vector__XXX
 SG_ FanSpeed : 16|16@1+ (0.125,0) [0|8031.875] "rpm" Vector__XXX
 SG_ HydraulicFanMotorPressure : 32|16@1+ (0.5,0) [0|32127.5] "kPa" Vector__XXX
 SG_ EngineFanReverseSwitch : 12|2@1+ (1,0) [0|3] "" Vector__XXX
 SG_ EngineFanBypassSwitch : 14|2@1+ (1,0) [0|3] "" Vector__XXX

BO_ 2566832126 EBC2: 8 Vector__XXX
 SG_ FrontAxleSpeed : 0|16@1+ (0.00390625,0) [0|250.99609375] "km/h" Vector__XXX
 SG_ RelativeSpeedFrontAxleLeftWheel : 16|8@1+ (0.0625,-7.8125) [-7.8125|7.8125] "km/h" Vector__XXX
 SG_ RltvSpdFrntAxlRghtWhl : 24|8@1+ (0.0625,-7.8125) [-7.8125|7.8125] "km/h" Vector__XXX
 SG_ RelativeSpeedRearAxle1LeftWheel : 32|8@1+ (0.0625,-7.8125) [-7.8125|7.8125] "km/h" Vector__XXX
 SG_ RltvSpdRrAxl1RghtWhl : 40|8@1+ (0.0625,-7.8125) [-7.8125|7.8125] "km/h" Vector__XXX
 SG_ RelativeSpeedRearAxle2LeftWheel : 48|8@1+ (0.0625,-7.8125) [-7.8125|7.8125] "km/h" Vector__XXX
 SG_ RltvSpdRrAxl2RghtWhl : 56|8@1+ (0.0625,-7.8125) [-7.8125|7.8125] "km/h" Vector__XXX

BO_ 2566832382 SERV: 8 Vector__XXX
 SG_ ServiceDelayCalendarTimeBased : 32|8@1+ (1,-125) [-125|125] "week" Vector__XXX
 SG_ ServiceDistance : 8|16@1+ (5,-160635) [-160635|160640] "km" Vector__XXX
 SG_ SrvDlOprtnlTmBsd : 48|16@1+ (1,-32127) [-32127|32128] "h" Vector__XXX
 SG_ ServiceComponentIdentificationA : 0|8@1+ (1,0) [0|250] "ID" Vector__XXX
 SG_ ServiceComponentIdentificationB : 24|8@1+ (1,0) [0|250] "ID" Vector__XXX
 SG_ ServiceComponentIdentificationC : 40|8@1+ (1,0) [0|250] "ID" Vector__XXX

BO_ 2566832638 VDHR: 8 Vector__XXX
 SG_ TripDistanceHighResolution : 32|32@1+ (5,0) [0|21055406075] "m" Vector__XXX
 SG_ TtlVhlDstnHghRsltn : 0|32@1+ (5,0) [0|21055406075] "m" Vector__XXX

BO_ 2566837758 AS1: 8 Vector__XXX
 SG_ Alternator1Status : 16|2@1+ (1,0) [0|3] "" Vector__XXX
 SG_ Alternator2Status : 18|2@1+ (1,0) [0|3] "" Vector__XXX
 SG_ Alternator3Status : 20|2@1+ (1,0) [0|3] "" Vector__XXX
 SG_ Alternator4Status : 22|2@1+ (1,0) [0|3] "" Vector__XXX
 SG_ AlternatorSpeed : 0|16@1+ (0.5,0) [0|32127.5] "rpm" Vector__XXX
 SG_ AltrntrEltrlFlrStts : 24|2@1+ (1,0) [0|3] "" Vector__XXX
 SG_ AltrntrMhnlFlrStts : 26|2@1+ (1,0) [0|3] "" Vector__XXX
 SG_ AltrntrHghTmprtrWrnngStts : 28|2@1+ (1,0) [0|3] "" Vector__XXX
 SG_ AlternatorLinTimeoutDetected : 30|2@1+ (1,0) [0|3] "" Vector__XXX
 SG_ AltrntrLnCmmntnFlrStts : 32|2@1+ (1,0) [0|3] "" Vector__XXX
 SG_ AlternatorLoadBalancingStatus : 34|2@1+ (1,0) [0|3] "" Vector__XXX
 SG_ AlternatorExcitationStatus : 36|2@1+ (1,0) [0|3] "" Vector__XXX

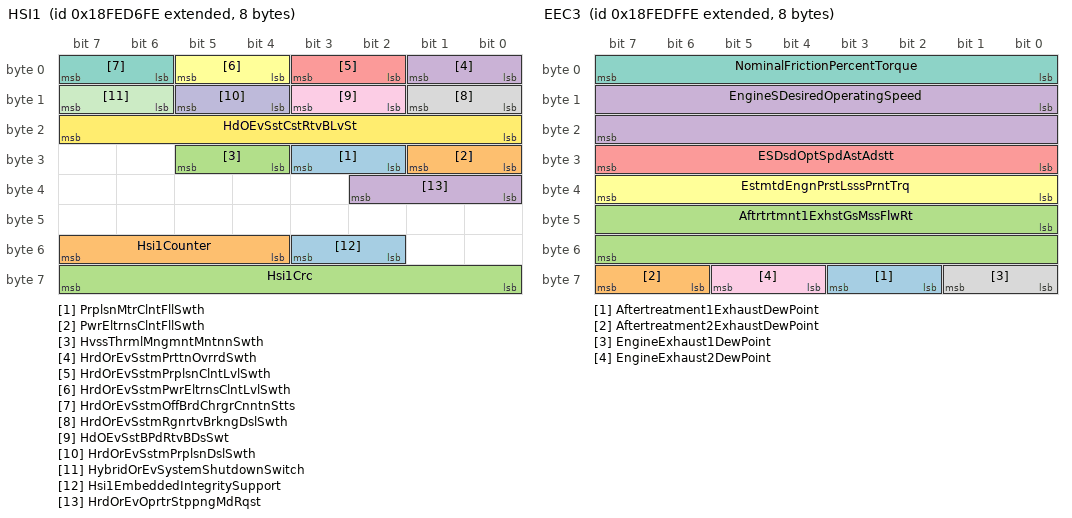
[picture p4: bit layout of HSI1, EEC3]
BO_ 2566838014 HSI1: 8 Vector__XXX
 SG_ PrplsnMtrClntFllSwth : 26|2@1+ (1,0) [0|3] "" Vector__XXX
 SG_ PwrEltrnsClntFllSwth : 24|2@1+ (1,0) [0|3] "" Vector__XXX
 SG_ HvssThrmlMngmntMntnnSwth : 28|2@1+ (1,0) [0|3] "" Vector__XXX
 SG_ HrdOrEvSstmPrttnOvrrdSwth : 0|2@1+ (1,0) [0|3] "" Vector__XXX
 SG_ HrdOrEvSstmPrplsnClntLvlSwth : 2|2@1+ (1,0) [0|3] "" Vector__XXX
 SG_ HrdOrEvSstmPwrEltrnsClntLvlSwth : 4|2@1+ (1,0) [0|3] "" Vector__XXX
 SG_ HrdOrEvSstmOffBrdChrgrCnntnStts : 6|2@1+ (1,0) [0|3] "" Vector__XXX
 SG_ HrdOrEvSstmRgnrtvBrkngDslSwth : 8|2@1+ (1,0) [0|3] "" Vector__XXX
 SG_ HdOEvSstBPdRtvBDsSwt : 10|2@1+ (1,0) [0|3] "" Vector__XXX
 SG_ HrdOrEvSstmPrplsnDslSwth : 12|2@1+ (1,0) [0|3] "" Vector__XXX
 SG_ HybridOrEvSystemShutdownSwitch : 14|2@1+ (1,0) [0|3] "" Vector__XXX
 SG_ HdOEvSstCstRtvBLvSt : 16|8@1+ (0.4,0) [0|100] "%" Vector__XXX
 SG_ Hsi1EmbeddedIntegritySupport : 50|2@1+ (1,0) [0|3] "" Vector__XXX
 SG_ Hsi1Counter : 52|4@1+ (1,0) [0|15] "" Vector__XXX
 SG_ Hsi1Crc : 56|8@1+ (1,0) [0|250] "count" Vector__XXX
 SG_ HrdOrEvOprtrStppngMdRqst : 32|3@1+ (1,0) [0|7] "" Vector__XXX

BO_ 2566838782 AUXIO1: 8 Vector__XXX
 SG_ AuxiliaryIO01 : 6|2@1+ (1,0) [0|3] "" Vector__XXX
 SG_ AuxiliaryIO02 : 4|2@1+ (1,0) [0|3] "" Vector__XXX
 SG_ AuxiliaryIO03 : 2|2@1+ (1,0) [0|3] "" Vector__XXX
 SG_ AuxiliaryIO04 : 0|2@1+ (1,0) [0|3] "" Vector__XXX
 SG_ AuxiliaryIO05 : 14|2@1+ (1,0) [0|3] "" Vector__XXX
 SG_ AuxiliaryIO06 : 12|2@1+ (1,0) [0|3] "" Vector__XXX
 SG_ AuxiliaryIO07 : 10|2@1+ (1,0) [0|3] "" Vector__XXX
 SG_ AuxiliaryIO08 : 8|2@1+ (1,0) [0|3] "" Vector__XXX
 SG_ AuxiliaryIO09 : 22|2@1+ (1,0) [0|3] "" Vector__XXX
 SG_ AuxiliaryIO10 : 20|2@1+ (1,0) [0|3] "" Vector__XXX
 SG_ AuxiliaryIO11 : 18|2@1+ (1,0) [0|3] "" Vector__XXX
 SG_ AuxiliaryIO12 : 16|2@1+ (1,0) [0|3] "" Vector__XXX
 SG_ AuxiliaryIO13 : 30|2@1+ (1,0) [0|3] "" Vector__XXX
 SG_ AuxiliaryIO14 : 28|2@1+ (1,0) [0|3] "" Vector__XXX
 SG_ AuxiliaryIO15 : 26|2@1+ (1,0) [0|3] "" Vector__XXX
 SG_ AuxiliaryIO16 : 24|2@1+ (1,0) [0|3] "" Vector__XXX
 SG_ AuxiliaryIOChannel1 : 32|16@1+ (1,0) [0|64255] "count" Vector__XXX
 SG_ AuxiliaryIOChannel2 : 48|16@1+ (1,0) [0|64255] "count" Vector__XXX

BO_ 2566839038 SOFT: 8 Vector__XXX
 SG_ NmrOfSftwrIdntftnFlds : 0|8@1+ (1,0) [0|125] "step" Vector__XXX

BO_ 2566839294 EFLP2: 8 Vector__XXX
 SG_ EngnFl1InjtrMtrngRl1Prssr : 16|16@1+ (0.00390625,0) [0|250.99609375] "MPa" Vector__XXX
 SG_ EngnFl1InjtrMtrngRl2Prssr : 48|16@1+ (0.00390625,0) [0|250.99609375] "MPa" Vector__XXX
 SG_ EngnFl1InjtrTmngRl1Prssr : 32|16@1+ (0.00390625,0) [0|250.99609375] "MPa" Vector__XXX
 SG_ EngnFlInjtnCntrlPrssr : 0|16@1+ (0.00390625,0) [0|250.99609375] "MPa" Vector__XXX

BO_ 2566839550 IO: 8 Vector__XXX
 SG_ EngineTotalIdleFuelUsed : 0|32@1+ (0.5,0) [0|2105540607.5] "l" Vector__XXX
 SG_ EngineTotalIdleHours : 32|32@1+ (0.05,0) [0|210554060.75] "h" Vector__XXX

BO_ 2566839806 TC: 8 Vector__XXX
 SG_ EngineTurbocharger1Speed : 8|16@1+ (4,0) [0|257020] "rpm" Vector__XXX
 SG_ EngnTrhrgrDffrntlSpd : 32|16@1+ (4,0) [0|257020] "rpm" Vector__XXX
 SG_ EngnTrhrgrLOlPrssr1 : 0|8@1+ (4,0) [0|1000] "kPa" Vector__XXX
 SG_ EngnTrhrgrOlLvlSwth : 30|2@1+ (1,0) [0|3] "" Vector__XXX

BO_ 2566840062 AIR2: 8 Vector__XXX
 SG_ EngineAirStartPressure : 0|8@1+ (4,0) [0|1000] "kPa" Vector__XXX
 SG_ EngineAirStopPressure : 16|8@1+ (4,0) [0|1000] "kPa" Vector__XXX
 SG_ EngnArStrtPrssrExtnddRng : 8|8@1+ (16,0) [0|4000] "kPa" Vector__XXX

BO_ 2566840318 EEC3: 8 Vector__XXX
 SG_ Aftertreatment1ExhaustDewPoint : 58|2@1+ (1,0) [0|3] "" Vector__XXX
 SG_ Aftertreatment2ExhaustDewPoint : 62|2@1+ (1,0) [0|3] "" Vector__XXX
 SG_ Aftrtrtmnt1ExhstGsMssFlwRt : 40|16@1+ (0.2,0) [0|12851] "kg/h" Vector__XXX
 SG_ EngineSDesiredOperatingSpeed : 8|16@1+ (0.125,0) [0|8031.875] "rpm" Vector__XXX
 SG_ ESDsdOptSpdAstAdstt : 24|8@1+ (1,0) [0|250] "" Vector__XXX
 SG_ EstmtdEngnPrstLsssPrntTrq : 32|8@1+ (1,-125) [0|125] "%" Vector__XXX
 SG_ NominalFrictionPercentTorque : 0|8@1+ (1,-125) [-125|125] "%" Vector__XXX
 SG_ EngineExhaust1DewPoint : 56|2@1+ (1,0) [0|3] "" Vector__XXX
 SG_ EngineExhaust2DewPoint : 60|2@1+ (1,0) [0|3] "" Vector__XXX

BO_ 2566840574 VD: 8 Vector__XXX
 SG_ TotalVehicleDistance : 32|32@1+ (0.125,0) [0|526385151.875] "km" Vector__XXX
 SG_ TripDistance : 0|32@1+ (0.125,0) [0|526385151.875] "km" Vector__XXX

BO_ 2566840830 RC: 19 Vector__XXX
 SG_ MaximumRetarderSpeedPoint2 : 40|16@1+ (0.125,0) [0|8031.875] "rpm" Vector__XXX
 SG_ RetarderControlMethod : 8|8@1+ (1,0) [0|250] "step" Vector__XXX
 SG_ RetarderLocation : 4|4@1+ (1,0) [0|15] "" Vector__XXX
 SG_ RetarderPercentTorqueAtPoint3 : 80|8@1+ (1,-125) [-125|0] "%" Vector__XXX
 SG_ RetarderPercentTorqueAtPoint4 : 104|8@1+ (1,-125) [-125|0] "%" Vector__XXX
 SG_ RetarderReferenceTorque : 128|16@1+ (1,0) [0|64255] "Nm" Vector__XXX
 SG_ RetarderSpeedAtIdlePoint1 : 16|16@1+ (0.125,0) [0|8031.875] "rpm" Vector__XXX
 SG_ RetarderSpeedAtPeakTorquePoint5 : 112|16@1+ (0.125,0) [0|8031.875] "rpm" Vector__XXX
 SG_ RetarderSpeedAtPoint3 : 64|16@1+ (0.125,0) [0|8031.875] "rpm" Vector__XXX
 SG_ RetarderSpeedAtPoint4 : 88|16@1+ (0.125,0) [0|8031.875] "rpm" Vector__XXX
 SG_ RetarderType : 0|4@1+ (1,0) [0|15] "" Vector__XXX
 SG_ RtrdrPrntTrqAtIdlPnt1 : 32|8@1+ (1,-125) [-125|0] "%" Vector__XXX
 SG_ RtrdrPrntTrqAtMxmmSpdPnt2 : 56|8@1+ (1,-125) [-125|0] "%" Vector__XXX
 SG_ RtrdrPrntTrqAtPkTrqPnt5 : 144|8@1+ (1,-125) [-125|0] "%" Vector__XXX

BO_ 2566841086 TCFG: 8 Vector__XXX
 SG_ NumberOfForwardGearRatios : 8|8@1+ (1,0) [0|125] "gear value" Vector__XXX
 SG_ NumberOfReverseGearRatios : 0|8@1+ (1,0) [0|125] "gear value" Vector__XXX
 SG_ TransmissionGearRatio : 16|16@1+ (0.001,0) [0|64.255] "" Vector__XXX

BO_ 2566841342 EC1: 40 Vector__XXX
 SG_ EngineDefaultIdleTorqueLimit : 312|8@1+ (1,-125) [0|125] "%" Vector__XXX
 SG_ EngineDefaultTorqueLimit : 256|16@1+ (1,0) [0|64255] "Nm" Vector__XXX
 SG_ EngineMomentOfInertia : 240|16@1+ (0.004,0) [0|257.02] "kg*(m*m)" Vector__XXX
 SG_ EnginePercentTorqueAtIdlePoint1 : 16|8@1+ (1,-125) [0|125] "%" Vector__XXX
 SG_ EnginePercentTorqueAtPoint2 : 40|8@1+ (1,-125) [0|125] "%" Vector__XXX
 SG_ EnginePercentTorqueAtPoint3 : 64|8@1+ (1,-125) [0|125] "%" Vector__XXX
 SG_ EnginePercentTorqueAtPoint4 : 88|8@1+ (1,-125) [0|125] "%" Vector__XXX
 SG_ EnginePercentTorqueAtPoint5 : 112|8@1+ (1,-125) [0|125] "%" Vector__XXX
 SG_ EngineReferenceTorque : 152|16@1+ (1,0) [0|64255] "Nm" Vector__XXX
 SG_ EngineSpeedAtHighIdlePoint6 : 120|16@1+ (0.125,0) [0|8031.875] "rpm" Vector__XXX
 SG_ EngineSpeedAtIdlePoint1 : 0|16@1+ (0.125,0) [0|8031.875] "rpm" Vector__XXX
 SG_ EngineSpeedAtPoint2 : 24|16@1+ (0.125,0) [0|8031.875] "rpm" Vector__XXX
 SG_ EngineSpeedAtPoint3 : 48|16@1+ (0.125,0) [0|8031.875] "rpm" Vector__XXX
 SG_ EngineSpeedAtPoint4 : 72|16@1+ (0.125,0) [0|8031.875] "rpm" Vector__XXX
 SG_ EngineSpeedAtPoint5 : 96|16@1+ (0.125,0) [0|8031.875] "rpm" Vector__XXX
 SG_ EngnGnKpOfThEndspdGvrnr : 136|16@1+ (0.00078125,0) [0|50.19921875] "%/rpm" Vector__XXX
 SG_ EngnMxmmMmntrOvrrdSpdPnt7 : 168|16@1+ (0.125,0) [0|8031.875] "rpm" Vector__XXX
 SG_ EngnMxmmMmntrOvrrdTmLmt : 184|8@1+ (0.1,0) [0|25] "s" Vector__XXX
 SG_ EngnRqstdSpdCntrlRngLwrLmt : 192|8@1+ (10,0) [0|2500] "rpm" Vector__XXX
 SG_ EngnRqstdSpdCntrlRngUpprLmt : 200|8@1+ (10,0) [0|2500] "rpm" Vector__XXX
 SG_ EngnRqstdTrqCntrlRngLwrLmt : 208|8@1+ (1,-125) [0|125] "%" Vector__XXX
 SG_ EngnRqstdTrqCntrlRngUpprLmt : 216|8@1+ (1,-125) [0|125] "%" Vector__XXX
 SG_ ERqstdSpdCtRUppLtExtddR : 224|16@1+ (0.125,0) [0|8031.875] "rpm" Vector__XXX
 SG_ SupportTsc1ControlPurposeGroup1 : 280|8@1+ (1,0) [0|250] "" Vector__XXX
 SG_ SupportTsc1ControlPurposeGroup2 : 288|8@1+ (1,0) [0|250] "" Vector__XXX
 SG_ SupportTsc1ControlPurposeGroup3 : 296|8@1+ (1,0) [0|250] "" Vector__XXX
 SG_ SupportTsc1ControlPurposeGroup4 : 304|8@1+ (1,0) [0|250] "" Vector__XXX
 SG_ SupportVariableRateTsc1Message : 272|8@1+ (1,0) [0|250] "" Vector__XXX

BO_ 2566841598 SHUTDN: 8 Vector__XXX
 SG_ ACHighPressureFanSwitch : 16|2@1+ (1,0) [0|3] "" Vector__XXX
 SG_ ClntLvlEngnPrttnShtdwnStts : 60|2@1+ (1,0) [0|3] "" Vector__XXX
 SG_ EngineAirShutoffCommandStatus : 52|2@1+ (1,0) [0|3] "" Vector__XXX
 SG_ EngineAirShutoffStatus : 56|2@1+ (1,0) [0|3] "" Vector__XXX
 SG_ EngineAlarmAcknowledge : 48|2@1+ (1,0) [0|3] "" Vector__XXX
 SG_ EngineAlarmOutputCommandStatus : 50|2@1+ (1,0) [0|3] "" Vector__XXX
 SG_ EngineIdleShutdownTimerFunction : 14|2@1+ (1,0) [0|3] "" Vector__XXX
 SG_ EngineIdleShutdownTimerOverride : 4|2@1+ (1,0) [0|3] "" Vector__XXX
 SG_ EngineIdleShutdownTimerState : 6|2@1+ (1,0) [0|3] "" Vector__XXX
 SG_ EngineOilPressureSwitch : 62|2@1+ (1,0) [0|3] "" Vector__XXX
 SG_ EngineOverspeedTest : 54|2@1+ (1,0) [0|3] "" Vector__XXX
 SG_ EngineWaitToStartLamp : 24|2@1+ (1,0) [0|3] "" Vector__XXX
 SG_ EngnIdlShtdwnDrvrAlrtMd : 2|2@1+ (1,0) [0|3] "" Vector__XXX
 SG_ EngnIdlShtdwnHsShtdwnEngn : 0|2@1+ (1,0) [0|3] "" Vector__XXX
 SG_ EngnPrttnSstmApprhngShtdwn : 34|2@1+ (1,0) [0|3] "" Vector__XXX
 SG_ EngnPrttnSstmCnfgrtn : 46|2@1+ (1,0) [0|3] "" Vector__XXX
 SG_ EngnPrttnSstmHsShtdwnEngn : 32|2@1+ (1,0) [0|3] "" Vector__XXX
 SG_ EngnPrttnSstmTmrOvrrd : 36|2@1+ (1,0) [0|3] "" Vector__XXX
 SG_ EngnPrttnSstmTmrStt : 38|2@1+ (1,0) [0|3] "" Vector__XXX
 SG_ PtoShutdownHasShutdownEngine : 58|2@1+ (1,0) [0|3] "" Vector__XXX
 SG_ RefrigerantHighPressureSwitch : 20|2@1+ (1,0) [0|3] "" Vector__XXX
 SG_ RefrigerantLowPressureSwitch : 18|2@1+ (1,0) [0|3] "" Vector__XXX
 SG_ MhnIntvtShtdwnHsShtdwnEngn : 26|2@1+ (1,0) [0|3] "" Vector__XXX

BO_ 2566841854 HOURS: 8 Vector__XXX
 SG_ EngineTotalHoursOfOperation : 0|32@1+ (0.05,0) [0|210554060.75] "h" Vector__XXX
 SG_ EngineTotalRevolutions : 32|32@1+ (1000,0) [0|4211081215000] "r" Vector__XXX

BO_ 2566842110 TD: 8 Vector__XXX
 SG_ Day : 32|8@1+ (0.25,0) [0.25|31.75] "days" Vector__XXX
 SG_ Hours : 16|8@1+ (1,0) [0|23] "h" Vector__XXX
 SG_ LocalHourOffset : 56|8@1+ (1,-125) [-23|23] "h" Vector__XXX
 SG_ LocalMinuteOffset : 48|8@1+ (1,-125) [-59|59] "min" Vector__XXX
 SG_ Minutes : 8|8@1+ (1,0) [0|59] "min" Vector__XXX
 SG_ Month : 24|8@1+ (1,0) [1|12] "month" Vector__XXX
 SG_ Seconds : 0|8@1+ (0.25,0) [0|59.75] "s" Vector__XXX
 SG_ Year : 40|8@1+ (1,1985) [1985|2235] "year" Vector__XXX

BO_ 2566842366 VH: 8 Vector__XXX
 SG_ TotalPowerTakeoffHours : 32|32@1+ (0.05,0) [0|210554060.75] "h" Vector__XXX
 SG_ TotalVehicleHours : 0|32@1+ (0.05,0) [0|210554060.75] "h" Vector__XXX

BO_ 2566842622 VDS: 8 Vector__XXX
 SG_ Altitude : 48|16@1+ (0.125,-2500) [-2500|5531.875] "m" Vector__XXX
 SG_ CompassBearing : 0|16@1+ (0.0078125,0) [0|501.9921875] "deg" Vector__XXX
 SG_ NavigationBasedVehicleSpeed : 16|16@1+ (0.00390625,0) [0|250.99609375] "km/h" Vector__XXX
 SG_ Pitch : 32|16@1+ (0.0078125,-200) [-200|301.9921875] "deg" Vector__XXX

BO_ 2566842878 LFC1: 8 Vector__XXX
 SG_ EngineTotalFuelUsed : 32|32@1+ (0.5,0) [0|2105540607.5] "l" Vector__XXX
 SG_ EngineTripFuel : 0|32@1+ (0.5,0) [0|2105540607.5] "l" Vector__XXX

BO_ 2566843134 VW: 8 Vector__XXX
 SG_ AxleLocation : 0|8@1+ (1,0) [0|250] "" Vector__XXX
 SG_ AxleWeight : 8|16@1+ (0.5,0) [0|32127.5] "kg" Vector__XXX
 SG_ CargoWeight : 40|16@1+ (2,0) [0|128510] "kg" Vector__XXX
 SG_ TrailerWeight : 24|16@1+ (2,0) [0|128510] "kg" Vector__XXX

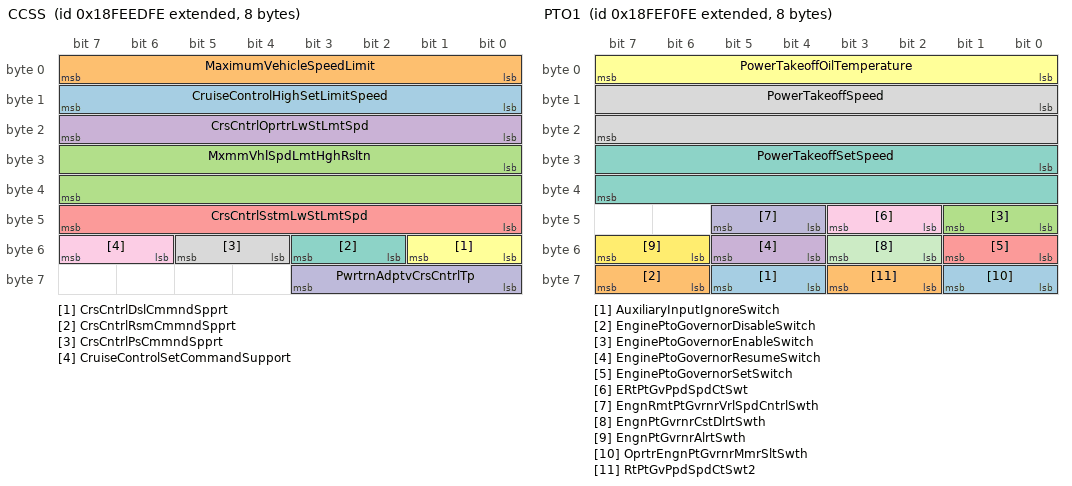
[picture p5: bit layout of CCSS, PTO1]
BO_ 2566843902 CCSS: 8 Vector__XXX
 SG_ CruiseControlHighSetLimitSpeed : 8|8@1+ (1,0) [0|250] "km/h" Vector__XXX
 SG_ MaximumVehicleSpeedLimit : 0|8@1+ (1,0) [0|250] "km/h" Vector__XXX
 SG_ MxmmVhlSpdLmtHghRsltn : 24|16@1+ (0.00390625,0) [0|250.99609375] "km/h" Vector__XXX
 SG_ CrsCntrlOprtrLwStLmtSpd : 16|8@1+ (1,0) [0|250] "km/h" Vector__XXX
 SG_ CrsCntrlSstmLwStLmtSpd : 40|8@1+ (1,0) [0|250] "km/h" Vector__XXX
 SG_ CrsCntrlDslCmmndSpprt : 48|2@1+ (1,0) [0|3] "" Vector__XXX
 SG_ CrsCntrlRsmCmmndSpprt : 50|2@1+ (1,0) [0|3] "" Vector__XXX
 SG_ CrsCntrlPsCmmndSpprt : 52|2@1+ (1,0) [0|3] "" Vector__XXX
 SG_ CruiseControlSetCommandSupport : 54|2@1+ (1,0) [0|3] "" Vector__XXX
 SG_ PwrtrnAdptvCrsCntrlTp : 56|4@1+ (1,0) [0|15] "" Vector__XXX

BO_ 2566844158 ET1: 8 Vector__XXX
 SG_ EngineCoolantTemperature : 0|8@1+ (1,-40) [-40|210] "degC" Vector__XXX
 SG_ EngineFuel1Temperature1 : 8|8@1+ (1,-40) [-40|210] "degC" Vector__XXX
 SG_ EngineIntercoolerTemperature : 48|8@1+ (1,-40) [-40|210] "degC" Vector__XXX
 SG_ EngineOilTemperature1 : 16|16@1+ (0.03125,-273) [-273|1734.96875] "degC" Vector__XXX
 SG_ EngnChrgArClrThrmsttOpnng : 56|8@1+ (0.4,0) [0|100] "%" Vector__XXX
 SG_ EngnTrhrgr1OlTmprtr : 32|16@1+ (0.03125,-273) [-273|1734.96875] "degC" Vector__XXX

BO_ 2566844414 EFLP1: 8 Vector__XXX
 SG_ EngineCoolantLevel1 : 56|8@1+ (0.4,0) [0|100] "%" Vector__XXX
 SG_ EngineCoolantPressure1 : 48|8@1+ (2,0) [0|500] "kPa" Vector__XXX
 SG_ EngineCrankcasePressure1 : 32|16@1+ (0.0078125,-250) [-250|251.9921875] "kPa" Vector__XXX
 SG_ EngineFuelDeliveryPressure : 0|8@1+ (4,0) [0|1000] "kPa" Vector__XXX
 SG_ EngineOilLevel : 16|8@1+ (0.4,0) [0|100] "%" Vector__XXX
 SG_ EngineOilPressure1 : 24|8@1+ (4,0) [0|1000] "kPa" Vector__XXX
 SG_ EngnExtnddCrnksBlwBPrssr : 8|8@1+ (0.05,0) [0|12.5] "kPa" Vector__XXX

BO_ 2566844670 PTO1: 8 Vector__XXX
 SG_ AuxiliaryInputIgnoreSwitch : 60|2@1+ (1,0) [0|3] "" Vector__XXX
 SG_ EnginePtoGovernorDisableSwitch : 62|2@1+ (1,0) [0|3] "" Vector__XXX
 SG_ EnginePtoGovernorEnableSwitch : 40|2@1+ (1,0) [0|3] "" Vector__XXX
 SG_ EnginePtoGovernorResumeSwitch : 52|2@1+ (1,0) [0|3] "" Vector__XXX
 SG_ EnginePtoGovernorSetSwitch : 48|2@1+ (1,0) [0|3] "" Vector__XXX
 SG_ PowerTakeoffOilTemperature : 0|8@1+ (1,-40) [-40|210] "degC" Vector__XXX
 SG_ PowerTakeoffSetSpeed : 24|16@1+ (0.125,0) [0|8031.875] "rpm" Vector__XXX
 SG_ PowerTakeoffSpeed : 8|16@1+ (0.125,0) [0|8031.875] "rpm" Vector__XXX
 SG_ ERtPtGvPpdSpdCtSwt : 42|2@1+ (1,0) [0|3] "" Vector__XXX
 SG_ EngnRmtPtGvrnrVrlSpdCntrlSwth : 44|2@1+ (1,0) [0|3] "" Vector__XXX
 SG_ EngnPtGvrnrCstDlrtSwth : 50|2@1+ (1,0) [0|3] "" Vector__XXX
 SG_ EngnPtGvrnrAlrtSwth : 54|2@1+ (1,0) [0|3] "" Vector__XXX
 SG_ OprtrEngnPtGvrnrMmrSltSwth : 56|2@1+ (1,0) [0|3] "" Vector__XXX
 SG_ RtPtGvPpdSpdCtSwt2 : 58|2@1+ (1,0) [0|3] "" Vector__XXX

BO_ 2566844926 CCVS1: 8 Vector__XXX
 SG_ BrakeSwitch : 28|2@1+ (1,0) [0|3] "" Vector__XXX
 SG_ ClutchSwitch : 30|2@1+ (1,0) [0|3] "" Vector__XXX
 SG_ CrsCntrlCstDlrtSwth : 34|2@1+ (1,0) [0|3] "" Vector__XXX
 SG_ CruiseControlAccelerateSwitch : 38|2@1+ (1,0) [0|3] "" Vector__XXX
 SG_ CruiseControlActive : 24|2@1+ (1,0) [0|3] "" Vector__XXX
 SG_ CruiseControlEnableSwitch : 26|2@1+ (1,0) [0|3] "" Vector__XXX
 SG_ CruiseControlPauseSwitch : 4|2@1+ (1,0) [0|3] "" Vector__XXX
 SG_ CruiseControlResumeSwitch : 36|2@1+ (1,0) [0|3] "" Vector__XXX
 SG_ CruiseControlSetSpeed : 40|8@1+ (1,0) [0|250] "km/h" Vector__XXX
 SG_ CruiseControlSetSwitch : 32|2@1+ (1,0) [0|3] "" Vector__XXX
 SG_ CruiseControlStates : 53|3@1+ (1,0) [0|7] "" Vector__XXX
 SG_ EngineDiagnosticTestModeSwitch : 60|2@1+ (1,0) [0|3] "" Vector__XXX
 SG_ EngineIdleDecrementSwitch : 58|2@1+ (1,0) [0|3] "" Vector__XXX
 SG_ EngineIdleIncrementSwitch : 56|2@1+ (1,0) [0|3] "" Vector__XXX
 SG_ EngineShutdownOverrideSwitch : 62|2@1+ (1,0) [0|3] "" Vector__XXX
 SG_ ParkBrakeReleaseInhibitRequest : 6|2@1+ (1,0) [0|3] "" Vector__XXX
 SG_ ParkingBrakeSwitch : 2|2@1+ (1,0) [0|3] "" Vector__XXX
 SG_ PtoGovernorState : 48|5@1+ (1,0) [0|31] "" Vector__XXX
 SG_ TwoSpeedAxleSwitch : 0|2@1+ (1,0) [0|3] "" Vector__XXX
 SG_ WheelBasedVehicleSpeed : 8|16@1+ (0.00390625,0) [0|250.99609375] "km/h" Vector__XXX

BO_ 2566845182 LFE1: 8 Vector__XXX
 SG_ EngineAverageFuelEconomy : 32|16@1+ (0.001953125,0) [0|125.498046875] "km/L" Vector__XXX
 SG_ EngineFuelRate : 0|16@1+ (0.05,0) [0|3212.75] "l/h" Vector__XXX
 SG_ EngineInstantaneousFuelEconomy : 16|16@1+ (0.001953125,0) [0|125.498046875] "km/L" Vector__XXX
 SG_ EngineThrottleValve1Position1 : 48|8@1+ (0.4,0) [0|100] "%" Vector__XXX
 SG_ EngineThrottleValve2Position : 56|8@1+ (0.4,0) [0|100] "%" Vector__XXX

BO_ 2566845438 VP1: 8 Vector__XXX
 SG_ Latitude : 0|32@1+ (0.0000001,-210) [-210|211.1081215] "deg" Vector__XXX
 SG_ Longitude : 32|32@1+ (0.0000001,-210) [-210|211.1081215] "deg" Vector__XXX

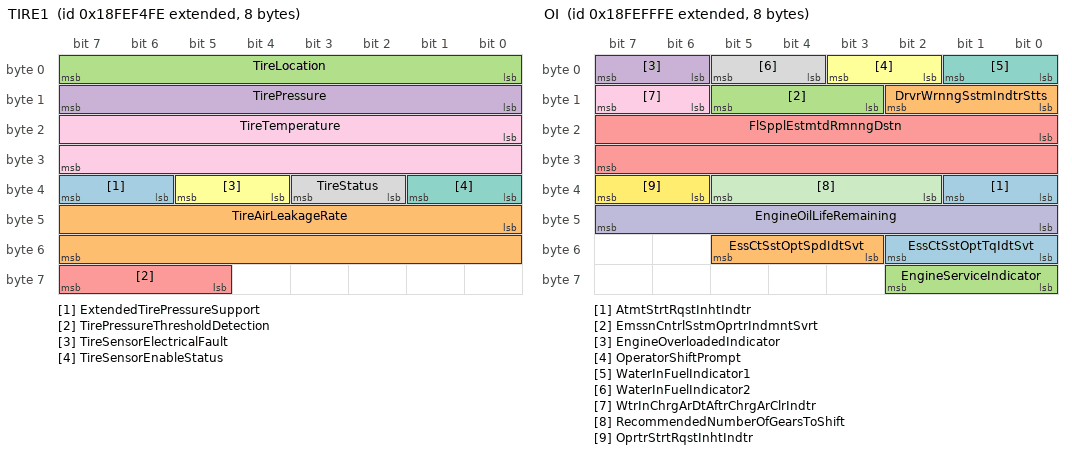
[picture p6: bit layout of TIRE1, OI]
BO_ 2566845694 TIRE1: 8 Vector__XXX
 SG_ ExtendedTirePressureSupport : 38|2@1+ (1,0) [0|3] "" Vector__XXX
 SG_ TireAirLeakageRate : 40|16@1+ (0.1,0) [0|6425.5] "Pa/s" Vector__XXX
 SG_ TireLocation : 0|8@1+ (1,0) [0|250] "" Vector__XXX
 SG_ TirePressure : 8|8@1+ (4,0) [0|1000] "kPa" Vector__XXX
 SG_ TirePressureThresholdDetection : 61|3@1+ (1,0) [0|7] "" Vector__XXX
 SG_ TireSensorElectricalFault : 36|2@1+ (1,0) [0|3] "" Vector__XXX
 SG_ TireSensorEnableStatus : 32|2@1+ (1,0) [0|3] "" Vector__XXX
 SG_ TireStatus : 34|2@1+ (1,0) [0|3] "" Vector__XXX
 SG_ TireTemperature : 16|16@1+ (0.03125,-273) [-273|1734.96875] "degC" Vector__XXX

BO_ 2566845950 AMB: 8 Vector__XXX
 SG_ AmbientAirTemperature : 24|16@1+ (0.03125,-273) [-273|1734.96875] "degC" Vector__XXX
 SG_ BarometricPressure : 0|8@1+ (0.5,0) [0|125] "kPa" Vector__XXX
 SG_ CabInteriorTemperature : 8|16@1+ (0.03125,-273) [-273|1734.96875] "degC" Vector__XXX
 SG_ EngineIntake1AirTemperature : 40|8@1+ (1,-40) [-40|210] "degC" Vector__XXX
 SG_ RoadSurfaceTemperature : 48|16@1+ (0.03125,-273) [-273|1734.96875] "degC" Vector__XXX

BO_ 2566846206 IC1: 8 Vector__XXX
 SG_ EngineExhaustTemperature : 40|16@1+ (0.03125,-273) [-273|1734.96875] "degC" Vector__XXX
 SG_ EngineIntakeAirPressure : 24|8@1+ (2,0) [0|500] "kPa" Vector__XXX
 SG_ EngineIntakeManifold1Pressure : 8|8@1+ (2,0) [0|500] "kPa" Vector__XXX
 SG_ EngnArFltr1DffrntlPrssr : 32|8@1+ (0.05,0) [0|12.5] "kPa" Vector__XXX
 SG_ EngnClntFltrDffrntlPrssr : 56|8@1+ (0.5,0) [0|125] "kPa" Vector__XXX
 SG_ EngnIntkMnfld1Tmprtr : 16|8@1+ (1,-40) [-40|210] "degC" Vector__XXX
 SG_ Atttt1DsPttFtItPssUsSp3609 : 0|8@1+ (0.5,0) [0|125] "kPa" Vector__XXX

BO_ 2566846462 VEP1: 8 Vector__XXX
 SG_ AlternatorCurrent : 8|8@1+ (1,0) [0|250] "A" Vector__XXX
 SG_ BatteryPotentialPowerInput1 : 32|16@1+ (0.05,0) [0|3212.75] "V" Vector__XXX
 SG_ ChargingSystemPotentialVoltage : 16|16@1+ (0.05,0) [0|3212.75] "V" Vector__XXX
 SG_ KeySwitchBatteryPotential : 48|16@1+ (0.05,0) [0|3212.75] "V" Vector__XXX
 SG_ SliBattery1NetCurrent : 0|8@1+ (1,-125) [-125|125] "A" Vector__XXX

BO_ 2566846718 TRF1: 8 Vector__XXX
 SG_ Transmission1OilPressure : 24|8@1+ (16,0) [0|4000] "kPa" Vector__XXX
 SG_ TransmissionClutch1Pressure : 0|8@1+ (16,0) [0|4000] "kPa" Vector__XXX
 SG_ TransmissionOilLevel1 : 8|8@1+ (0.4,0) [0|100] "%" Vector__XXX
 SG_ TransmissionOilLevel1HighLow : 48|8@1+ (0.5,-62.5) [-62.5|62.5] "l" Vector__XXX
 SG_ TrnsmssnFltrDffrntlPrssr : 16|8@1+ (2,0) [0|500] "kPa" Vector__XXX
 SG_ TrnsmssnOlLvl1CntdwnTmr : 56|4@1+ (1,0) [0|13] "" Vector__XXX
 SG_ TrnsmssnOlLvl1MsrmntStts : 60|4@1+ (1,0) [0|15] "" Vector__XXX
 SG_ Transmission1OilTemperature1 : 32|16@1+ (0.03125,-273) [-273|1734.96875] "degC" Vector__XXX

BO_ 2566846974 AI: 8 Vector__XXX
 SG_ DriveAxleLiftAirPressure : 16|8@1+ (4,0) [0|1000] "kPa" Vector__XXX
 SG_ DriveAxleLocation : 8|8@1+ (1,0) [0|250] "" Vector__XXX
 SG_ DriveAxleLubePressure : 32|8@1+ (4,0) [0|1000] "kPa" Vector__XXX
 SG_ DriveAxleTemperature : 24|8@1+ (1,-40) [-40|210] "degC" Vector__XXX
 SG_ SteeringAxleLubePressure : 56|8@1+ (4,0) [0|1000] "kPa" Vector__XXX
 SG_ SteeringAxleTemperature : 0|8@1+ (1,-40) [-40|210] "degC" Vector__XXX

BO_ 2566847230 B1: 8 Vector__XXX
 SG_ BrakeApplicationPressure : 0|8@1+ (4,0) [0|1000] "kPa" Vector__XXX
 SG_ BrakePrimaryPressure : 8|8@1+ (4,0) [0|1000] "kPa" Vector__XXX
 SG_ BrakeSecondaryPressure : 16|8@1+ (4,0) [0|1000] "kPa" Vector__XXX
 SG_ ParkBrakeReleaseInhibitStatus : 28|2@1+ (1,0) [0|3] "" Vector__XXX
 SG_ ParkingBrakeActuator : 24|2@1+ (1,0) [0|3] "" Vector__XXX
 SG_ ParkingBrakeRedWarningSignal : 26|2@1+ (1,0) [0|3] "" Vector__XXX
 SG_ TotalBrakeAxleTorque : 32|16@1+ (2,0) [0|128510] "Nm" Vector__XXX

BO_ 2566847486 RF: 8 Vector__XXX
 SG_ DrvlnRtrdrOvrhtIndtr : 16|2@1+ (1,0) [0|3] "" Vector__XXX
 SG_ HydraulicRetarderOilTemperature : 8|8@1+ (1,-40) [-40|210] "degC" Vector__XXX
 SG_ HydraulicRetarderPressure : 0|8@1+ (16,0) [0|4000] "kPa" Vector__XXX
 SG_ RtrdrClntOtltTmprtr : 24|8@1+ (1,-40) [-40|210] "degC" Vector__XXX

BO_ 2566847742 DD1: 8 Vector__XXX
 SG_ CargoAmbientTemperature : 32|16@1+ (0.03125,-273) [-273|1734.96875] "degC" Vector__XXX
 SG_ EngnFlFltrDffrntlPrssr : 16|8@1+ (2,0) [0|500] "kPa" Vector__XXX
 SG_ EngnOlFltrDffrntlPrssr : 24|8@1+ (0.5,0) [0|125] "kPa" Vector__XXX
 SG_ EngnOlFltrDffrntlPrssrExtnddRng : 56|8@1+ (5,0) [0|1250] "kPa" Vector__XXX
 SG_ FuelLevel1 : 8|8@1+ (0.4,0) [0|100] "%" Vector__XXX
 SG_ FuelLevel2 : 48|8@1+ (0.4,0) [0|100] "%" Vector__XXX
 SG_ WasherFluidLevel : 0|8@1+ (0.4,0) [0|100] "%" Vector__XXX

BO_ 2566847998 AF1: 8 Vector__XXX
 SG_ EngineBlowerBypassValvePosition : 0|8@1+ (0.4,0) [0|100] "%" Vector__XXX
 SG_ EngineGaseousFuelVentPressure : 24|16@1+ (0.5,0) [0|32127.5] "kPa" Vector__XXX
 SG_ EngnGssFlPrssrRgltrIntkPrssr : 48|16@1+ (1,0) [0|64255] "kPa" Vector__XXX
 SG_ EngnGssFlSpplPrssr1 : 8|16@1+ (0.5,0) [0|32127.5] "kPa" Vector__XXX
 SG_ LngVprzrClntOtltTmprtr : 40|8@1+ (1,-40) [-40|210] "degC" Vector__XXX

BO_ 2566848254 AWPP: 8 Vector__XXX
 SG_ AuxiliaryPumpPressure : 0|8@1+ (16,0) [0|4000] "kPa" Vector__XXX

BO_ 2566848510 OI: 8 Vector__XXX
 SG_ AtmtStrtRqstInhtIndtr : 32|2@1+ (1,0) [0|3] "" Vector__XXX
 SG_ DrvrWrnngSstmIndtrStts : 8|3@1+ (1,0) [0|7] "" Vector__XXX
 SG_ EmssnCntrlSstmOprtrIndmntSvrt : 11|3@1+ (1,0) [0|7] "" Vector__XXX
 SG_ EngineOverloadedIndicator : 6|2@1+ (1,0) [0|3] "" Vector__XXX
 SG_ FlSpplEstmtdRmnngDstn : 16|16@1+ (1,0) [0|64255] "km" Vector__XXX
 SG_ OperatorShiftPrompt : 2|2@1+ (1,0) [0|3] "" Vector__XXX
 SG_ WaterInFuelIndicator1 : 0|2@1+ (1,0) [0|3] "" Vector__XXX
 SG_ WaterInFuelIndicator2 : 4|2@1+ (1,0) [0|3] "" Vector__XXX
 SG_ WtrInChrgArDtAftrChrgArClrIndtr : 14|2@1+ (1,0) [0|3] "" Vector__XXX
 SG_ EngineOilLifeRemaining : 40|8@1+ (0.4,0) [0|100] "%" Vector__XXX
 SG_ RecommendedNumberOfGearsToShift : 34|4@1+ (1,0) [0|13] "count" Vector__XXX
 SG_ OprtrStrtRqstInhtIndtr : 38|2@1+ (1,0) [0|3] "" Vector__XXX
 SG_ EssCtSstOptTqIdtSvt : 48|3@1+ (1,0) [0|7] "" Vector__XXX
 SG_ EssCtSstOptSpdIdtSvt : 51|3@1+ (1,0) [0|7] "" Vector__XXX
 SG_ EngineServiceIndicator : 56|3@1+ (1,0) [0|7] "" Vector__XXX

BO_ 2624716542 CTPC: 8 Vector__XXX
 SG_ CmmnddTrnsmtPgnRqstdStt : 40|2@1+ (1,0) [0|3] "" Vector__XXX
 SG_ CommandedTransmitPgn : 16|24@1+ (1,0) [0|16449535] "" Vector__XXX
 SG_ TransmitPgnsCommandedPort : 0|4@1+ (1,0) [0|15] "" Vector__XXX
 SG_ TransmitPgnsTransactionMode : 4|4@1+ (1,0) [0|15] "" Vector__XXX

BO_ 2631728894 ATS: 8 Vector__XXX
 SG_ AntiTheftComponentStatusStates : 4|2@1+ (1,0) [0|3] "" Vector__XXX
 SG_ AntiTheftModifyPasswordStates : 6|2@1+ (1,0) [0|3] "" Vector__XXX
 SG_ AntiTheftPasswordValidIndicator : 2|2@1+ (1,0) [0|3] "" Vector__XXX
 SG_ AntiTheftRandomNumber : 8|56@1+ (1,0) [0|255] "" Vector__XXX
 SG_ AntThftEnrptnSdPrsntIndtr : 0|2@1+ (1,0) [0|3] "" Vector__XXX

BO_ 2631794430 ATR: 8 Vector__XXX
 SG_ AntiTheftCommandStates : 5|3@1+ (1,0) [0|7] "" Vector__XXX
 SG_ AntiTheftDesiredExitModeStates : 3|2@1+ (1,0) [0|3] "" Vector__XXX
 SG_ AntiTheftPasswordRepresentation : 8|56@1+ (1,0) [0|255] "" Vector__XXX
 SG_ AntThftEnrptnIndtrStts : 1|2@1+ (1,0) [0|3] "" Vector__XXX

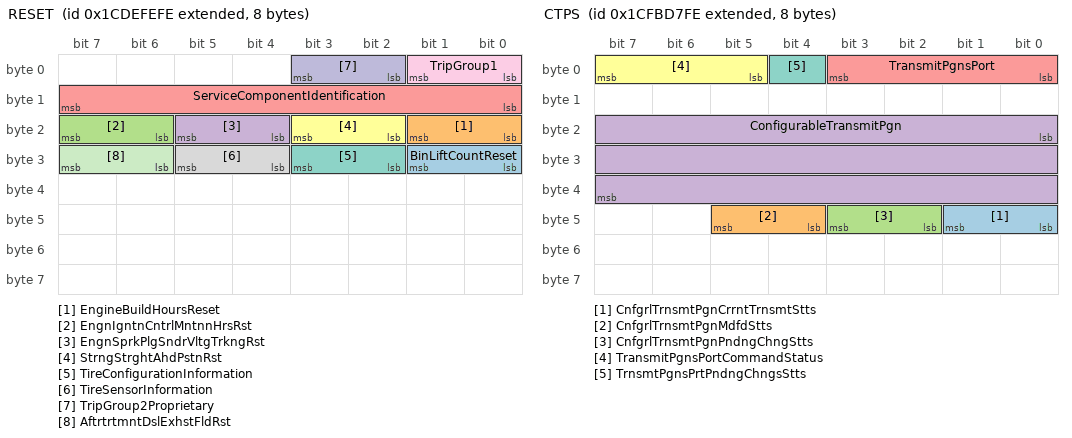
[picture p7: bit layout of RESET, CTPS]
BO_ 2631859966 RESET: 8 Vector__XXX
 SG_ BinLiftCountReset : 24|2@1+ (1,0) [0|3] "" Vector__XXX
 SG_ EngineBuildHoursReset : 16|2@1+ (1,0) [0|3] "" Vector__XXX
 SG_ EngnIgntnCntrlMntnnHrsRst : 22|2@1+ (1,0) [0|3] "" Vector__XXX
 SG_ EngnSprkPlgSndrVltgTrkngRst : 20|2@1+ (1,0) [0|3] "" Vector__XXX
 SG_ ServiceComponentIdentification : 8|8@1+ (1,0) [0|250] "ID" Vector__XXX
 SG_ StrngStrghtAhdPstnRst : 18|2@1+ (1,0) [0|3] "" Vector__XXX
 SG_ TireConfigurationInformation : 26|2@1+ (1,0) [0|3] "" Vector__XXX
 SG_ TireSensorInformation : 28|2@1+ (1,0) [0|3] "" Vector__XXX
 SG_ TripGroup1 : 0|2@1+ (1,0) [0|3] "" Vector__XXX
 SG_ TripGroup2Proprietary : 2|2@1+ (1,0) [0|3] "" Vector__XXX
 SG_ AftrtrtmntDslExhstFldRst : 30|2@1+ (1,0) [0|3] "" Vector__XXX

BO_ 2633734398 EO2: 8 Vector__XXX
 SG_ EngineActualExhaust2Oxygen : 0|16@1+ (0.0025,0) [0|160.6375] "%" Vector__XXX

BO_ 2633749502 WSPT: 16 Vector__XXX
 SG_ WellStimulationPumpCycleCount : 96|32@1+ (1,0) [0|4211081215] "count" Vector__XXX
 SG_ WellStimulationPumpWorkingHours : 64|32@1+ (1,0) [0|4211081215] "s" Vector__XXX
 SG_ WllStmltnPmpFldEndWrkngHrs : 0|32@1+ (1,0) [0|4211081215] "s" Vector__XXX
 SG_ WllStmltnPmpPwrEndWrkngHrs : 32|32@1+ (1,0) [0|4211081215] "s" Vector__XXX

BO_ 2633749758 WSPC: 8 Vector__XXX
 SG_ WellStimulationPumpGearRatio : 32|16@1+ (0.001,0) [0|64.255] "" Vector__XXX
 SG_ WellStimulationPumpRatedSpeed : 48|16@1+ (0.125,0) [0|8031.875] "rpm" Vector__XXX
 SG_ WellStimulationPumpStrokeLength : 16|16@1+ (1,0) [0|64255] "mm" Vector__XXX
 SG_ WllStmltnPmpPlngrDmtr : 0|16@1+ (1,0) [0|64255] "mm" Vector__XXX

BO_ 2633750526 CTPS: 8 Vector__XXX
 SG_ CnfgrlTrnsmtPgnCrrntTrnsmtStts : 40|2@1+ (1,0) [0|3] "" Vector__XXX
 SG_ CnfgrlTrnsmtPgnMdfdStts : 44|2@1+ (1,0) [0|3] "" Vector__XXX
 SG_ CnfgrlTrnsmtPgnPndngChngStts : 42|2@1+ (1,0) [0|3] "" Vector__XXX
 SG_ ConfigurableTransmitPgn : 16|24@1+ (1,0) [0|16449535] "" Vector__XXX
 SG_ TransmitPgnsPort : 0|4@1+ (1,0) [0|15] "" Vector__XXX
 SG_ TransmitPgnsPortCommandStatus : 5|3@1+ (1,0) [0|7] "" Vector__XXX
 SG_ TrnsmtPgnsPrtPndngChngsStts : 4|1@1+ (1,0) [0|1] "" Vector__XXX

BO_ 2633752830 ACOCF1: 8 Vector__XXX
 SG_ AltrntrAftrlrClntOtltTmprtr : 48|8@1+ (1,-40) [-40|210] "degC" Vector__XXX
 SG_ AltrntrAftrlrClntPmpOtltPrssr : 56|8@1+ (2,0) [0|500] "kPa" Vector__XXX
 SG_ AltrntrAftrlrClntPmpOtltTmprtr : 40|8@1+ (1,-40) [-40|210] "degC" Vector__XXX
 SG_ AltrntrOlClrClntIntkTmprtr : 16|8@1+ (1,-40) [-40|210] "degC" Vector__XXX
 SG_ AltrntrOlClrClntOtltTmprtr : 24|8@1+ (1,-40) [-40|210] "degC" Vector__XXX
 SG_ AltrntrOlClrOlIntkTmprtr : 0|8@1+ (1,-40) [-40|210] "degC" Vector__XXX
 SG_ AltrntrOlClrOlOtltTmprtr : 8|8@1+ (1,-40) [-40|210] "degC" Vector__XXX
 SG_ EngnOlClrClntOtltTmprtr : 32|8@1+ (1,-40) [-40|210] "degC" Vector__XXX

BO_ 2633753086 DT2: 8 Vector__XXX
 SG_ PowerRectifierDiode9Temperature : 0|8@1+ (1,-40) [-40|210] "degC" Vector__XXX
 SG_ PwrRtfrDd10Tmprtr : 8|8@1+ (1,-40) [-40|210] "degC" Vector__XXX
 SG_ PwrRtfrDd11Tmprtr : 16|8@1+ (1,-40) [-40|210] "degC" Vector__XXX
 SG_ PwrRtfrDd12Tmprtr : 24|8@1+ (1,-40) [-40|210] "degC" Vector__XXX

BO_ 2633753342 DT1: 8 Vector__XXX
 SG_ PowerRectifierDiode1Temperature : 0|8@1+ (1,-40) [-40|210] "degC" Vector__XXX
 SG_ PowerRectifierDiode2Temperature : 8|8@1+ (1,-40) [-40|210] "degC" Vector__XXX
 SG_ PowerRectifierDiode3Temperature : 16|8@1+ (1,-40) [-40|210] "degC" Vector__XXX
 SG_ PowerRectifierDiode4Temperature : 24|8@1+ (1,-40) [-40|210] "degC" Vector__XXX
 SG_ PowerRectifierDiode5Temperature : 32|8@1+ (1,-40) [-40|210] "degC" Vector__XXX
 SG_ PowerRectifierDiode6Temperature : 40|8@1+ (1,-40) [-40|210] "degC" Vector__XXX
 SG_ PowerRectifierDiode7Temperature : 48|8@1+ (1,-40) [-40|210] "degC" Vector__XXX
 SG_ PowerRectifierDiode8Temperature : 56|8@1+ (1,-40) [-40|210] "degC" Vector__XXX

BO_ 2633753598 AT2: 8 Vector__XXX
 SG_ AltrntrArClrArIntkTmprtr : 48|8@1+ (1,-40) [-40|210] "degC" Vector__XXX
 SG_ AltrntrArClrArOtltTmprtr : 56|8@1+ (1,-40) [-40|210] "degC" Vector__XXX
 SG_ EngnAltrntrWndng10Tmprtr : 24|8@1+ (1,-40) [-40|210] "degC" Vector__XXX
 SG_ EngnAltrntrWndng11Tmprtr : 32|8@1+ (1,-40) [-40|210] "degC" Vector__XXX
 SG_ EngnAltrntrWndng12Tmprtr : 40|8@1+ (1,-40) [-40|210] "degC" Vector__XXX
 SG_ EngnAltrntrWndng7Tmprtr : 0|8@1+ (1,-40) [-40|210] "degC" Vector__XXX
 SG_ EngnAltrntrWndng8Tmprtr : 8|8@1+ (1,-40) [-40|210] "degC" Vector__XXX
 SG_ EngnAltrntrWndng9Tmprtr : 16|8@1+ (1,-40) [-40|210] "degC" Vector__XXX

BO_ 2633754622 SCROII5: 8 Vector__XXX
 SG_ Aftrtrtmnt1SrIntkHghTmprtrTm : 0|32@1+ (1,0) [0|4211081215] "s" Vector__XXX
 SG_ SOptIdtEOvdTtAtvtT : 32|32@1+ (1,0) [0|4211081215] "s" Vector__XXX

BO_ 2633754878 ASI2: 8 Vector__XXX
 SG_ AftrtrtmntTtlDslExhstFldUsd : 0|32@1+ (0.5,0) [0|2105540607.5] "l" Vector__XXX
 SG_ AttttDsExstFdUsdTsOptC : 32|16@1+ (0.1,0) [0|6425.5] "l" Vector__XXX
 SG_ HydrocarbonDoserDutyCycle : 56|8@1+ (0.4,0) [0|100] "%" Vector__XXX
 SG_ Aftertreatment1DefDosingMode : 48|8@1+ (1,0) [0|250] "count" Vector__XXX

BO_ 2633755390 E1NET1: 20 Vector__XXX
 SG_ DefaultGatewayOctet1 : 72|8@1+ (1,0) [0|250] "count" Vector__XXX
 SG_ DefaultGatewayOctet2 : 80|8@1+ (1,0) [0|250] "count" Vector__XXX
 SG_ DefaultGatewayOctet3 : 88|8@1+ (1,0) [0|250] "count" Vector__XXX
 SG_ DefaultGatewayOctet4 : 96|8@1+ (1,0) [0|250] "count" Vector__XXX
 SG_ DhcpStatus : 0|4@1+ (1,0) [0|15] "" Vector__XXX
 SG_ EthernetLinkStatus : 4|2@1+ (1,0) [0|3] "" Vector__XXX
 SG_ Ipv4AddressOctet1 : 8|8@1+ (1,0) [0|250] "count" Vector__XXX
 SG_ Ipv4AddressOctet2 : 16|8@1+ (1,0) [0|250] "count" Vector__XXX
 SG_ Ipv4AddressOctet3 : 24|8@1+ (1,0) [0|250] "count" Vector__XXX
 SG_ Ipv4AddressOctet4 : 32|8@1+ (1,0) [0|250] "count" Vector__XXX
 SG_ MacAddressOctet1 : 104|8@1+ (1,0) [0|250] "count" Vector__XXX
 SG_ MacAddressOctet2 : 112|8@1+ (1,0) [0|250] "count" Vector__XXX
 SG_ MacAddressOctet3 : 120|8@1+ (1,0) [0|250] "count" Vector__XXX
 SG_ MacAddressOctet4 : 128|8@1+ (1,0) [0|250] "count" Vector__XXX
 SG_ MacAddressOctet5 : 136|8@1+ (1,0) [0|250] "count" Vector__XXX
 SG_ MacAddressOctet6 : 144|8@1+ (1,0) [0|250] "count" Vector__XXX
 SG_ SubnetMaskOctet1 : 40|8@1+ (1,0) [0|250] "count" Vector__XXX
 SG_ SubnetMaskOctet2 : 48|8@1+ (1,0) [0|250] "count" Vector__XXX
 SG_ SubnetMaskOctet3 : 56|8@1+ (1,0) [0|250] "count" Vector__XXX
 SG_ SubnetMaskOctet4 : 64|8@1+ (1,0) [0|250] "count" Vector__XXX

BO_ 2633764094 EVAP2: 4 Vector__XXX
 SG_ CanisterPurgeValveCommand : 8|8@1+ (0.4,0) [0|100] "%" Vector__XXX
 SG_ CanisterVentValve : 0|2@1+ (1,0) [0|3] "" Vector__XXX
 SG_ GasolineFuelTankPressure : 16|16@1+ (0.1,-3212.7) [-3212.7|3212.8] "kPa" Vector__XXX

BO_ 2633764350 FPS1: 8 Vector__XXX
 SG_ FirePumpEngagementCycles : 32|16@1+ (1,0) [0|64255] "count" Vector__XXX
 SG_ FirePumpOperationTime : 0|32@1+ (1,0) [0|4211081215] "s" Vector__XXX

BO_ 2633769726 EEC19: 8 Vector__XXX
 SG_ EngnExhstFlwRtExtnddRng : 32|32@1+ (0.001,0) [0|4211081.215] "kg/h" Vector__XXX
 SG_ TotalEngineEnergy : 0|32@1+ (1,0) [0|4211081215] "kWh" Vector__XXX

BO_ 2633773054 FSAS: 8 Vector__XXX
 SG_ FireSuppressionWaterTankLevel : 0|8@1+ (0.4,0) [0|100] "%" Vector__XXX
 SG_ FrSpprssnClssAFmTnkLvl : 8|8@1+ (0.4,0) [0|100] "%" Vector__XXX
 SG_ FrSpprssnClssBFmTnkLvl : 16|8@1+ (0.4,0) [0|100] "%" Vector__XXX
 SG_ FrSpprssnCmprssdArFmSstmArPrssr : 24|8@1+ (8,0) [0|2000] "kPa" Vector__XXX

BO_ 2633773310 SCROII4: 8 Vector__XXX
 SG_ SOptIdtEOvdTtRstOs : 0|16@1+ (1,0) [0|64255] "count" Vector__XXX
 SG_ SrOprtrIndmntOvrrdMd : 16|3@1+ (1,0) [0|7] "" Vector__XXX
 SG_ SrOprtrIndmntOvrrdRnwlRqrd : 19|2@1+ (1,0) [0|3] "" Vector__XXX
 SG_ SOptIdtOvdTRExtddR : 24|16@1+ (1,0) [0|64255] "min" Vector__XXX

BO_ 2633782014 BWLN: 8 Vector__XXX
 SG_ BinInstance : 0|4@1+ (1,0) [0|15] "count" Vector__XXX
 SG_ BinLiftCount : 8|16@1+ (1,0) [0|64255] "count" Vector__XXX
 SG_ BinWeighingErrorStatus : 4|4@1+ (1,0) [0|15] "" Vector__XXX
 SG_ NetBinWeight : 24|16@1+ (2,0) [0|128510] "kg" Vector__XXX

BO_ 2633785086 HVESSHIST: 20 Vector__XXX
 SG_ HvessStateOfHealth : 0|8@1+ (0.4,0) [0|100] "%" Vector__XXX
 SG_ HvessTotalEnergyThroughput : 24|32@1+ (100,0) [0|421108121500] "Watt-hour" Vector__XXX
 SG_ HvessTotalAccumulatedCharge : 56|32@1+ (100,0) [0|421108121500] "Ah" Vector__XXX
 SG_ HvessTotalLifetimeEnergyInput : 88|32@1+ (1,0) [0|4211081215] "kWh" Vector__XXX
 SG_ HvessTotalLifetimeEnergyOutput : 120|32@1+ (1,0) [0|4211081215] "kWh" Vector__XXX
 SG_ HvssCnttrOpnUndrLdCnt : 8|16@1+ (1,0) [0|64255] "count" Vector__XXX

BO_ 2633801982 MFEH: 8 Vector__XXX
 SG_ EngnTtlHrsOfGssFlOprtn : 0|32@1+ (0.05,0) [0|210554060.75] "h" Vector__XXX
 SG_ EngnTtlHrsOfDslFlOprtn : 32|32@1+ (0.05,0) [0|210554060.75] "h" Vector__XXX

BO_ 2633802238 ESMR3: 8 Vector__XXX
 SG_ EngineSparkPlug17MisfireRate : 0|8@1+ (0.4,0) [0|100] "%" Vector__XXX
 SG_ EngineSparkPlug18MisfireRate : 8|8@1+ (0.4,0) [0|100] "%" Vector__XXX
 SG_ EngineSparkPlug19MisfireRate : 16|8@1+ (0.4,0) [0|100] "%" Vector__XXX
 SG_ EngineSparkPlug20MisfireRate : 24|8@1+ (0.4,0) [0|100] "%" Vector__XXX
 SG_ EngineSparkPlug21MisfireRate : 32|8@1+ (0.4,0) [0|100] "%" Vector__XXX
 SG_ EngineSparkPlug22MisfireRate : 40|8@1+ (0.4,0) [0|100] "%" Vector__XXX
 SG_ EngineSparkPlug23MisfireRate : 48|8@1+ (0.4,0) [0|100] "%" Vector__XXX
 SG_ EngineSparkPlug24MisfireRate : 56|8@1+ (0.4,0) [0|100] "%" Vector__XXX

BO_ 2633802494 ESMR2: 8 Vector__XXX
 SG_ EngineSparkPlug10MisfireRate : 8|8@1+ (0.4,0) [0|100] "%" Vector__XXX
 SG_ EngineSparkPlug11MisfireRate : 16|8@1+ (0.4,0) [0|100] "%" Vector__XXX
 SG_ EngineSparkPlug12MisfireRate : 24|8@1+ (0.4,0) [0|100] "%" Vector__XXX
 SG_ EngineSparkPlug13MisfireRate : 32|8@1+ (0.4,0) [0|100] "%" Vector__XXX
 SG_ EngineSparkPlug14MisfireRate : 40|8@1+ (0.4,0) [0|100] "%" Vector__XXX
 SG_ EngineSparkPlug15MisfireRate : 48|8@1+ (0.4,0) [0|100] "%" Vector__XXX
 SG_ EngineSparkPlug16MisfireRate : 56|8@1+ (0.4,0) [0|100] "%" Vector__XXX
 SG_ EngineSparkPlug9MisfireRate : 0|8@1+ (0.4,0) [0|100] "%" Vector__XXX

BO_ 2633802750 ESMR1: 8 Vector__XXX
 SG_ EngineSparkPlug1MisfireRate : 0|8@1+ (0.4,0) [0|100] "%" Vector__XXX
 SG_ EngineSparkPlug2MisfireRate : 8|8@1+ (0.4,0) [0|100] "%" Vector__XXX
 SG_ EngineSparkPlug3MisfireRate : 16|8@1+ (0.4,0) [0|100] "%" Vector__XXX
 SG_ EngineSparkPlug4MisfireRate : 24|8@1+ (0.4,0) [0|100] "%" Vector__XXX
 SG_ EngineSparkPlug5MisfireRate : 32|8@1+ (0.4,0) [0|100] "%" Vector__XXX
 SG_ EngineSparkPlug6MisfireRate : 40|8@1+ (0.4,0) [0|100] "%" Vector__XXX
 SG_ EngineSparkPlug7MisfireRate : 48|8@1+ (0.4,0) [0|100] "%" Vector__XXX
 SG_ EngineSparkPlug8MisfireRate : 56|8@1+ (0.4,0) [0|100] "%" Vector__XXX

BO_ 2633803006 ESVMAX6: 8 Vector__XXX
 SG_ EngineSparkPlug21MaximumVoltage : 0|16@1+ (1,0) [0|64255] "V" Vector__XXX
 SG_ EngineSparkPlug22MaximumVoltage : 16|16@1+ (1,0) [0|64255] "V" Vector__XXX
 SG_ EngineSparkPlug23MaximumVoltage : 32|16@1+ (1,0) [0|64255] "V" Vector__XXX
 SG_ EngineSparkPlug24MaximumVoltage : 48|16@1+ (1,0) [0|64255] "V" Vector__XXX

BO_ 2633803262 ESVMAX5: 8 Vector__XXX
 SG_ EngineSparkPlug17MaximumVoltage : 0|16@1+ (1,0) [0|64255] "V" Vector__XXX
 SG_ EngineSparkPlug18MaximumVoltage : 16|16@1+ (1,0) [0|64255] "V" Vector__XXX
 SG_ EngineSparkPlug19MaximumVoltage : 32|16@1+ (1,0) [0|64255] "V" Vector__XXX
 SG_ EngineSparkPlug20MaximumVoltage : 48|16@1+ (1,0) [0|64255] "V" Vector__XXX

BO_ 2633803518 ESVMAX4: 8 Vector__XXX
 SG_ EngineSparkPlug13MaximumVoltage : 0|16@1+ (1,0) [0|64255] "V" Vector__XXX
 SG_ EngineSparkPlug14MaximumVoltage : 16|16@1+ (1,0) [0|64255] "V" Vector__XXX
 SG_ EngineSparkPlug15MaximumVoltage : 32|16@1+ (1,0) [0|64255] "V" Vector__XXX
 SG_ EngineSparkPlug16MaximumVoltage : 48|16@1+ (1,0) [0|64255] "V" Vector__XXX

BO_ 2633803774 ESVMAX3: 8 Vector__XXX
 SG_ EngineSparkPlug10MaximumVoltage : 16|16@1+ (1,0) [0|64255] "V" Vector__XXX
 SG_ EngineSparkPlug11MaximumVoltage : 32|16@1+ (1,0) [0|64255] "V" Vector__XXX
 SG_ EngineSparkPlug12MaximumVoltage : 48|16@1+ (1,0) [0|64255] "V" Vector__XXX
 SG_ EngineSparkPlug9MaximumVoltage : 0|16@1+ (1,0) [0|64255] "V" Vector__XXX

BO_ 2633804030 ESVMAX2: 8 Vector__XXX
 SG_ EngineSparkPlug5MaximumVoltage : 0|16@1+ (1,0) [0|64255] "V" Vector__XXX
 SG_ EngineSparkPlug6MaximumVoltage : 16|16@1+ (1,0) [0|64255] "V" Vector__XXX
 SG_ EngineSparkPlug7MaximumVoltage : 32|16@1+ (1,0) [0|64255] "V" Vector__XXX
 SG_ EngineSparkPlug8MaximumVoltage : 48|16@1+ (1,0) [0|64255] "V" Vector__XXX

BO_ 2633804286 ESVMAX1: 8 Vector__XXX
 SG_ EngineSparkPlug1MaximumVoltage : 0|16@1+ (1,0) [0|64255] "V" Vector__XXX
 SG_ EngineSparkPlug2MaximumVoltage : 16|16@1+ (1,0) [0|64255] "V" Vector__XXX
 SG_ EngineSparkPlug3MaximumVoltage : 32|16@1+ (1,0) [0|64255] "V" Vector__XXX
 SG_ EngineSparkPlug4MaximumVoltage : 48|16@1+ (1,0) [0|64255] "V" Vector__XXX

BO_ 2633804542 ESVMIN6: 8 Vector__XXX
 SG_ EngineSparkPlug21MinimumVoltage : 0|16@1+ (1,0) [0|64255] "V" Vector__XXX
 SG_ EngineSparkPlug22MinimumVoltage : 16|16@1+ (1,0) [0|64255] "V" Vector__XXX
 SG_ EngineSparkPlug23MinimumVoltage : 32|16@1+ (1,0) [0|64255] "V" Vector__XXX
 SG_ EngineSparkPlug24MinimumVoltage : 48|16@1+ (1,0) [0|64255] "V" Vector__XXX

BO_ 2633804798 ESVMIN5: 8 Vector__XXX
 SG_ EngineSparkPlug17MinimumVoltage : 0|16@1+ (1,0) [0|64255] "V" Vector__XXX
 SG_ EngineSparkPlug18MinimumVoltage : 16|16@1+ (1,0) [0|64255] "V" Vector__XXX
 SG_ EngineSparkPlug19MinimumVoltage : 32|16@1+ (1,0) [0|64255] "V" Vector__XXX
 SG_ EngineSparkPlug20MinimumVoltage : 48|16@1+ (1,0) [0|64255] "V" Vector__XXX

BO_ 2633805054 ESVMIN4: 8 Vector__XXX
 SG_ EngineSparkPlug13MinimumVoltage : 0|16@1+ (1,0) [0|64255] "V" Vector__XXX
 SG_ EngineSparkPlug14MinimumVoltage : 16|16@1+ (1,0) [0|64255] "V" Vector__XXX
 SG_ EngineSparkPlug15MinimumVoltage : 32|16@1+ (1,0) [0|64255] "V" Vector__XXX
 SG_ EngineSparkPlug16MinimumVoltage : 48|16@1+ (1,0) [0|64255] "V" Vector__XXX

BO_ 2633805310 ESVMIN3: 8 Vector__XXX
 SG_ EngineSparkPlug10MinimumVoltage : 16|16@1+ (1,0) [0|64255] "V" Vector__XXX
 SG_ EngineSparkPlug11MinimumVoltage : 32|16@1+ (1,0) [0|64255] "V" Vector__XXX
 SG_ EngineSparkPlug12MinimumVoltage : 48|16@1+ (1,0) [0|64255] "V" Vector__XXX
 SG_ EngineSparkPlug9MinimumVoltage : 0|16@1+ (1,0) [0|64255] "V" Vector__XXX

BO_ 2633805566 ESVMIN2: 8 Vector__XXX
 SG_ EngineSparkPlug5MinimumVoltage : 0|16@1+ (1,0) [0|64255] "V" Vector__XXX
 SG_ EngineSparkPlug6MinimumVoltage : 16|16@1+ (1,0) [0|64255] "V" Vector__XXX
 SG_ EngineSparkPlug7MinimumVoltage : 32|16@1+ (1,0) [0|64255] "V" Vector__XXX
 SG_ EngineSparkPlug8MinimumVoltage : 48|16@1+ (1,0) [0|64255] "V" Vector__XXX

BO_ 2633805822 ESVMIN1: 8 Vector__XXX
 SG_ EngineSparkPlug1MinimumVoltage : 0|16@1+ (1,0) [0|64255] "V" Vector__XXX
 SG_ EngineSparkPlug2MinimumVoltage : 16|16@1+ (1,0) [0|64255] "V" Vector__XXX
 SG_ EngineSparkPlug3MinimumVoltage : 32|16@1+ (1,0) [0|64255] "V" Vector__XXX
 SG_ EngineSparkPlug4MinimumVoltage : 48|16@1+ (1,0) [0|64255] "V" Vector__XXX

BO_ 2633806078 EICMH: 8 Vector__XXX
 SG_ EngnIgntnCntrlMdl1TmRmnng : 0|32@1+ (0.05,0) [0|210554060.75] "h" Vector__XXX
 SG_ EngnIgntnCntrlMdl2TmRmnng : 32|32@1+ (0.05,0) [0|210554060.75] "h" Vector__XXX

BO_ 2633825022 EEC11: 8 Vector__XXX
 SG_ EngnExhstGsRrltn2Vlv1Cntrl : 0|16@1+ (0.0025,0) [0|160.6375] "%" Vector__XXX
 SG_ EngnExhstGsRrltn2Vlv1PstnErrr : 32|16@1+ (0.004,-125) [-125|132.02] "%" Vector__XXX
 SG_ EngnExhstGsRrltn2Vlv2Cntrl : 16|16@1+ (0.0025,0) [0|160.6375] "%" Vector__XXX
 SG_ EngnExhstGsRrltn2Vlv2PstnErrr : 48|16@1+ (0.004,-125) [-125|132.02] "%" Vector__XXX

BO_ 2633825534 EMAC: 8 Vector__XXX
 SG_ EExstMdB1FwBVvAttCt : 0|16@1+ (0.0025,0) [0|160.6375] "%" Vector__XXX
 SG_ EExstMdB2FwBVvAttCt : 16|16@1+ (0.0025,0) [0|160.6375] "%" Vector__XXX

BO_ 2633826046 EEC10: 8 Vector__XXX
 SG_ EExstGsRt2CBpssAttPst : 40|8@1+ (0.4,0) [0|100] "%" Vector__XXX
 SG_ EngnExhstGsRrltn2ClrEffn : 32|8@1+ (0.4,0) [0|100] "%" Vector__XXX
 SG_ EngnExhstGsRrltn2ClrIntkPrssr : 48|16@1+ (5,0) [0|321275] "kPa" Vector__XXX
 SG_ EngnExhstGsRrltn2ClrIntkTmprtr : 0|16@1+ (0.03125,-273) [-273|1734.96875] "degC" Vector__XXX
 SG_ EExstGsRt2CItAstPss : 16|16@1+ (0.5,0) [0|32127.5] "kPa" Vector__XXX

BO_ 2633828606 EOM: 8 Vector__XXX
 SG_ EngineOilDensity : 16|16@1+ (0.00003052,0) [0|1.9610626] "g/cc" Vector__XXX
 SG_ EngineOilTemperature3 : 48|16@1+ (0.03125,-273) [-273|1734.96875] "degC" Vector__XXX
 SG_ EngineOilViscosity : 0|16@1+ (0.015625,0) [0|1003.984375] "Cp" Vector__XXX
 SG_ EngnOlRltvDltrtHghRsltn : 32|16@1+ (0.0001220703125,0) [0|7.8436279296875] "" Vector__XXX

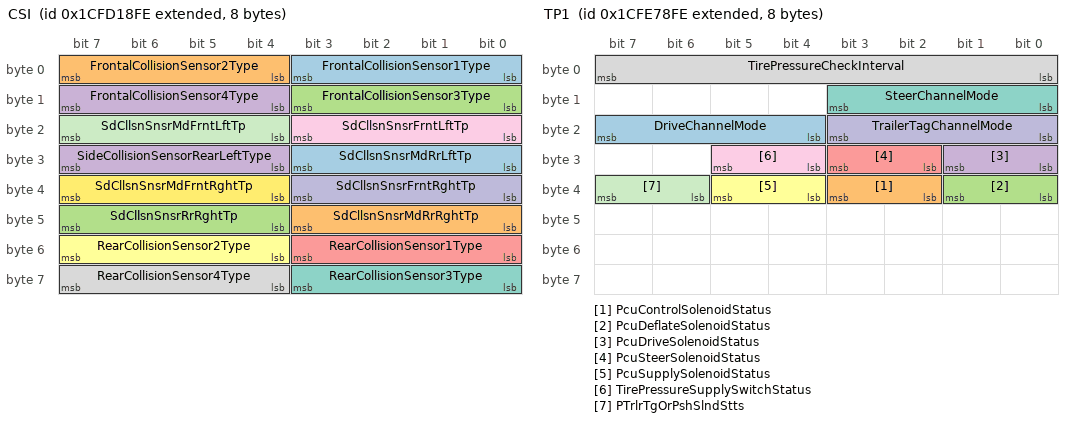
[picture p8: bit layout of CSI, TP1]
BO_ 2633832702 CSI: 8 Vector__XXX
 SG_ FrontalCollisionSensor1Type : 0|4@1+ (1,0) [0|15] "" Vector__XXX
 SG_ FrontalCollisionSensor2Type : 4|4@1+ (1,0) [0|15] "" Vector__XXX
 SG_ FrontalCollisionSensor3Type : 8|4@1+ (1,0) [0|15] "" Vector__XXX
 SG_ FrontalCollisionSensor4Type : 12|4@1+ (1,0) [0|15] "" Vector__XXX
 SG_ RearCollisionSensor1Type : 48|4@1+ (1,0) [0|15] "" Vector__XXX
 SG_ RearCollisionSensor2Type : 52|4@1+ (1,0) [0|15] "" Vector__XXX
 SG_ RearCollisionSensor3Type : 56|4@1+ (1,0) [0|15] "" Vector__XXX
 SG_ RearCollisionSensor4Type : 60|4@1+ (1,0) [0|15] "" Vector__XXX
 SG_ SdCllsnSnsrFrntLftTp : 16|4@1+ (1,0) [0|15] "" Vector__XXX
 SG_ SdCllsnSnsrFrntRghtTp : 32|4@1+ (1,0) [0|15] "" Vector__XXX
 SG_ SdCllsnSnsrMdFrntLftTp : 20|4@1+ (1,0) [0|15] "" Vector__XXX
 SG_ SdCllsnSnsrMdFrntRghtTp : 36|4@1+ (1,0) [0|15] "" Vector__XXX
 SG_ SdCllsnSnsrMdRrLftTp : 24|4@1+ (1,0) [0|15] "" Vector__XXX
 SG_ SdCllsnSnsrMdRrRghtTp : 40|4@1+ (1,0) [0|15] "" Vector__XXX
 SG_ SdCllsnSnsrRrRghtTp : 44|4@1+ (1,0) [0|15] "" Vector__XXX
 SG_ SideCollisionSensorRearLeftType : 28|4@1+ (1,0) [0|15] "" Vector__XXX

BO_ 2633832958 ILI: 200 Vector__XXX
 SG_ DrvrArgIgntrLp1StStgRsstn : 0|16@1+ (0.1,0) [0|6425.5] "ohm" Vector__XXX
 SG_ DrvrArgIgntrLp2NdStgRsstn : 32|16@1+ (0.1,0) [0|6425.5] "ohm" Vector__XXX
 SG_ DrvrBltTnsnrIgntrLpRsstn : 64|16@1+ (0.1,0) [0|6425.5] "ohm" Vector__XXX
 SG_ PssngrArgIgntrLp1StStgRsstn : 16|16@1+ (0.1,0) [0|6425.5] "ohm" Vector__XXX
 SG_ PssngrArgIgntrLp2NdStgRsstn : 48|16@1+ (0.1,0) [0|6425.5] "ohm" Vector__XXX
 SG_ PssngrBltTnsnrIgntrLpRsstn : 80|16@1+ (0.1,0) [0|6425.5] "ohm" Vector__XXX
 SG_ SdBgIgntrLp1LftRsstn : 96|16@1+ (0.1,0) [0|6425.5] "ohm" Vector__XXX
 SG_ SdBgIgntrLp1RghtRsstn : 128|16@1+ (0.1,0) [0|6425.5] "ohm" Vector__XXX
 SG_ SdBgIgntrLp2LftRsstn : 112|16@1+ (0.1,0) [0|6425.5] "ohm" Vector__XXX
 SG_ SdBgIgntrLp2RghtRsstn : 144|16@1+ (0.1,0) [0|6425.5] "ohm" Vector__XXX
 SG_ SpecialIgnitorLoop10Resistance : 304|16@1+ (0.1,0) [0|6425.5] "ohm" Vector__XXX
 SG_ SpecialIgnitorLoop11Resistance : 320|16@1+ (0.1,0) [0|6425.5] "ohm" Vector__XXX
 SG_ SpecialIgnitorLoop12Resistance : 336|16@1+ (0.1,0) [0|6425.5] "ohm" Vector__XXX
 SG_ SpecialIgnitorLoop13Resistance : 352|16@1+ (0.1,0) [0|6425.5] "ohm" Vector__XXX
 SG_ SpecialIgnitorLoop14Resistance : 368|16@1+ (0.1,0) [0|6425.5] "ohm" Vector__XXX
 SG_ SpecialIgnitorLoop15Resistance : 384|16@1+ (0.1,0) [0|6425.5] "ohm" Vector__XXX
 SG_ SpecialIgnitorLoop16Resistance : 400|16@1+ (0.1,0) [0|6425.5] "ohm" Vector__XXX
 SG_ SpecialIgnitorLoop17Resistance : 416|16@1+ (0.1,0) [0|6425.5] "ohm" Vector__XXX
 SG_ SpecialIgnitorLoop18Resistance : 432|16@1+ (0.1,0) [0|6425.5] "ohm" Vector__XXX
 SG_ SpecialIgnitorLoop19Resistance : 448|16@1+ (0.1,0) [0|6425.5] "ohm" Vector__XXX
 SG_ SpecialIgnitorLoop1Resistance : 160|16@1+ (0.1,0) [0|6425.5] "ohm" Vector__XXX
 SG_ SpecialIgnitorLoop20Resistance : 464|16@1+ (0.1,0) [0|6425.5] "ohm" Vector__XXX
 SG_ SpecialIgnitorLoop21Resistance : 480|16@1+ (0.1,0) [0|6425.5] "ohm" Vector__XXX
 SG_ SpecialIgnitorLoop22Resistance : 496|16@1+ (0.1,0) [0|6425.5] "ohm" Vector__XXX
 SG_ SpecialIgnitorLoop23Resistance : 512|16@1+ (0.1,0) [0|6425.5] "ohm" Vector__XXX
 SG_ SpecialIgnitorLoop24Resistance : 528|16@1+ (0.1,0) [0|6425.5] "ohm" Vector__XXX
 SG_ SpecialIgnitorLoop25Resistance : 544|16@1+ (0.1,0) [0|6425.5] "ohm" Vector__XXX
 SG_ SpecialIgnitorLoop26Resistance : 560|16@1+ (0.1,0) [0|6425.5] "ohm" Vector__XXX
 SG_ SpecialIgnitorLoop27Resistance : 576|16@1+ (0.1,0) [0|6425.5] "ohm" Vector__XXX
 SG_ SpecialIgnitorLoop28Resistance : 592|16@1+ (0.1,0) [0|6425.5] "ohm" Vector__XXX
 SG_ SpecialIgnitorLoop29Resistance : 608|16@1+ (0.1,0) [0|6425.5] "ohm" Vector__XXX
 SG_ SpecialIgnitorLoop2Resistance : 176|16@1+ (0.1,0) [0|6425.5] "ohm" Vector__XXX
 SG_ SpecialIgnitorLoop30Resistance : 624|16@1+ (0.1,0) [0|6425.5] "ohm" Vector__XXX
 SG_ SpecialIgnitorLoop31Resistance : 640|16@1+ (0.1,0) [0|6425.5] "ohm" Vector__XXX
 SG_ SpecialIgnitorLoop32Resistance : 656|16@1+ (0.1,0) [0|6425.5] "ohm" Vector__XXX
 SG_ SpecialIgnitorLoop33Resistance : 672|16@1+ (0.1,0) [0|6425.5] "ohm" Vector__XXX
 SG_ SpecialIgnitorLoop34Resistance : 688|16@1+ (0.1,0) [0|6425.5] "ohm" Vector__XXX
 SG_ SpecialIgnitorLoop35Resistance : 704|16@1+ (0.1,0) [0|6425.5] "ohm" Vector__XXX
 SG_ SpecialIgnitorLoop36Resistance : 720|16@1+ (0.1,0) [0|6425.5] "ohm" Vector__XXX
 SG_ SpecialIgnitorLoop37Resistance : 736|16@1+ (0.1,0) [0|6425.5] "ohm" Vector__XXX
 SG_ SpecialIgnitorLoop38Resistance : 752|16@1+ (0.1,0) [0|6425.5] "ohm" Vector__XXX
 SG_ SpecialIgnitorLoop39Resistance : 768|16@1+ (0.1,0) [0|6425.5] "ohm" Vector__XXX
 SG_ SpecialIgnitorLoop3Resistance : 192|16@1+ (0.1,0) [0|6425.5] "ohm" Vector__XXX
 SG_ SpecialIgnitorLoop40Resistance : 784|16@1+ (0.1,0) [0|6425.5] "ohm" Vector__XXX
 SG_ SpecialIgnitorLoop41Resistance : 800|16@1+ (0.1,0) [0|6425.5] "ohm" Vector__XXX
 SG_ SpecialIgnitorLoop42Resistance : 816|16@1+ (0.1,0) [0|6425.5] "ohm" Vector__XXX
 SG_ SpecialIgnitorLoop43Resistance : 832|16@1+ (0.1,0) [0|6425.5] "ohm" Vector__XXX
 SG_ SpecialIgnitorLoop44Resistance : 848|16@1+ (0.1,0) [0|6425.5] "ohm" Vector__XXX
 SG_ SpecialIgnitorLoop45Resistance : 864|16@1+ (0.1,0) [0|6425.5] "ohm" Vector__XXX
 SG_ SpecialIgnitorLoop46Resistance : 880|16@1+ (0.1,0) [0|6425.5] "ohm" Vector__XXX
 SG_ SpecialIgnitorLoop47Resistance : 896|16@1+ (0.1,0) [0|6425.5] "ohm" Vector__XXX
 SG_ SpecialIgnitorLoop48Resistance : 912|16@1+ (0.1,0) [0|6425.5] "ohm" Vector__XXX
 SG_ SpecialIgnitorLoop49Resistance : 928|16@1+ (0.1,0) [0|6425.5] "ohm" Vector__XXX
 SG_ SpecialIgnitorLoop4Resistance : 208|16@1+ (0.1,0) [0|6425.5] "ohm" Vector__XXX
 SG_ SpecialIgnitorLoop50Resistance : 944|16@1+ (0.1,0) [0|6425.5] "ohm" Vector__XXX
 SG_ SpecialIgnitorLoop51Resistance : 960|16@1+ (0.1,0) [0|6425.5] "ohm" Vector__XXX
 SG_ SpecialIgnitorLoop52Resistance : 976|16@1+ (0.1,0) [0|6425.5] "ohm" Vector__XXX
 SG_ SpecialIgnitorLoop53Resistance : 992|16@1+ (0.1,0) [0|6425.5] "ohm" Vector__XXX
 SG_ SpecialIgnitorLoop54Resistance : 1008|16@1+ (0.1,0) [0|6425.5] "ohm" Vector__XXX
 SG_ SpecialIgnitorLoop55Resistance : 1024|16@1+ (0.1,0) [0|6425.5] "ohm" Vector__XXX
 SG_ SpecialIgnitorLoop56Resistance : 1040|16@1+ (0.1,0) [0|6425.5] "ohm" Vector__XXX
 SG_ SpecialIgnitorLoop57Resistance : 1056|16@1+ (0.1,0) [0|6425.5] "ohm" Vector__XXX
 SG_ SpecialIgnitorLoop58Resistance : 1072|16@1+ (0.1,0) [0|6425.5] "ohm" Vector__XXX
 SG_ SpecialIgnitorLoop59Resistance : 1088|16@1+ (0.1,0) [0|6425.5] "ohm" Vector__XXX
 SG_ SpecialIgnitorLoop5Resistance : 224|16@1+ (0.1,0) [0|6425.5] "ohm" Vector__XXX
 SG_ SpecialIgnitorLoop60Resistance : 1104|16@1+ (0.1,0) [0|6425.5] "ohm" Vector__XXX
 SG_ SpecialIgnitorLoop61Resistance : 1120|16@1+ (0.1,0) [0|6425.5] "ohm" Vector__XXX
 SG_ SpecialIgnitorLoop62Resistance : 1136|16@1+ (0.1,0) [0|6425.5] "ohm" Vector__XXX
 SG_ SpecialIgnitorLoop63Resistance : 1152|16@1+ (0.1,0) [0|6425.5] "ohm" Vector__XXX
 SG_ SpecialIgnitorLoop64Resistance : 1168|16@1+ (0.1,0) [0|6425.5] "ohm" Vector__XXX
 SG_ SpecialIgnitorLoop65Resistance : 1184|16@1+ (0.1,0) [0|6425.5] "ohm" Vector__XXX
 SG_ SpecialIgnitorLoop66Resistance : 1200|16@1+ (0.1,0) [0|6425.5] "ohm" Vector__XXX
 SG_ SpecialIgnitorLoop67Resistance : 1216|16@1+ (0.1,0) [0|6425.5] "ohm" Vector__XXX
 SG_ SpecialIgnitorLoop68Resistance : 1232|16@1+ (0.1,0) [0|6425.5] "ohm" Vector__XXX
 SG_ SpecialIgnitorLoop69Resistance : 1248|16@1+ (0.1,0) [0|6425.5] "ohm" Vector__XXX
 SG_ SpecialIgnitorLoop6Resistance : 240|16@1+ (0.1,0) [0|6425.5] "ohm" Vector__XXX
 SG_ SpecialIgnitorLoop70Resistance : 1264|16@1+ (0.1,0) [0|6425.5] "ohm" Vector__XXX
 SG_ SpecialIgnitorLoop71Resistance : 1280|16@1+ (0.1,0) [0|6425.5] "ohm" Vector__XXX
 SG_ SpecialIgnitorLoop72Resistance : 1296|16@1+ (0.1,0) [0|6425.5] "ohm" Vector__XXX
 SG_ SpecialIgnitorLoop73Resistance : 1312|16@1+ (0.1,0) [0|6425.5] "ohm" Vector__XXX
 SG_ SpecialIgnitorLoop74Resistance : 1328|16@1+ (0.1,0) [0|6425.5] "ohm" Vector__XXX
 SG_ SpecialIgnitorLoop75Resistance : 1344|16@1+ (0.1,0) [0|6425.5] "ohm" Vector__XXX
 SG_ SpecialIgnitorLoop76Resistance : 1360|16@1+ (0.1,0) [0|6425.5] "ohm" Vector__XXX
 SG_ SpecialIgnitorLoop77Resistance : 1376|16@1+ (0.1,0) [0|6425.5] "ohm" Vector__XXX
 SG_ SpecialIgnitorLoop78Resistance : 1392|16@1+ (0.1,0) [0|6425.5] "ohm" Vector__XXX
 SG_ SpecialIgnitorLoop79Resistance : 1408|16@1+ (0.1,0) [0|6425.5] "ohm" Vector__XXX
 SG_ SpecialIgnitorLoop7Resistance : 256|16@1+ (0.1,0) [0|6425.5] "ohm" Vector__XXX
 SG_ SpecialIgnitorLoop80Resistance : 1424|16@1+ (0.1,0) [0|6425.5] "ohm" Vector__XXX
 SG_ SpecialIgnitorLoop81Resistance : 1440|16@1+ (0.1,0) [0|6425.5] "ohm" Vector__XXX
 SG_ SpecialIgnitorLoop82Resistance : 1456|16@1+ (0.1,0) [0|6425.5] "ohm" Vector__XXX
 SG_ SpecialIgnitorLoop83Resistance : 1472|16@1+ (0.1,0) [0|6425.5] "ohm" Vector__XXX
 SG_ SpecialIgnitorLoop84Resistance : 1488|16@1+ (0.1,0) [0|6425.5] "ohm" Vector__XXX
 SG_ SpecialIgnitorLoop85Resistance : 1504|16@1+ (0.1,0) [0|6425.5] "ohm" Vector__XXX
 SG_ SpecialIgnitorLoop86Resistance : 1520|16@1+ (0.1,0) [0|6425.5] "ohm" Vector__XXX
 SG_ SpecialIgnitorLoop87Resistance : 1536|16@1+ (0.1,0) [0|6425.5] "ohm" Vector__XXX
 SG_ SpecialIgnitorLoop88Resistance : 1552|16@1+ (0.1,0) [0|6425.5] "ohm" Vector__XXX
 SG_ SpecialIgnitorLoop89Resistance : 1568|16@1+ (0.1,0) [0|6425.5] "ohm" Vector__XXX
 SG_ SpecialIgnitorLoop8Resistance : 272|16@1+ (0.1,0) [0|6425.5] "ohm" Vector__XXX
 SG_ SpecialIgnitorLoop90Resistance : 1584|16@1+ (0.1,0) [0|6425.5] "ohm" Vector__XXX
 SG_ SpecialIgnitorLoop9Resistance : 288|16@1+ (0.1,0) [0|6425.5] "ohm" Vector__XXX

BO_ 2633853438 AGCW: 8 Vector__XXX
 SG_ AdditionalAxleGroupLocation : 4|4@1+ (1,0) [0|15] "" Vector__XXX
 SG_ AxleGroupEmptyWeightCalibration : 8|16@1+ (2,0) [0|128510] "kg" Vector__XXX
 SG_ AxleGroupFullWeightCalibration : 24|16@1+ (2,0) [0|128510] "kg" Vector__XXX
 SG_ AxleGroupLocation : 0|4@1+ (1,0) [0|15] "" Vector__XXX

BO_ 2633861886 J20122B: 8 Vector__XXX
 SG_ NumberOfJ20122ByteDtcs : 0|8@1+ (1,0) [0|250] "count" Vector__XXX
 SG_ J20122ByteDtc : 8|40@1+ (1,0) [0|255] "" Vector__XXX
 SG_ J20122ByteDtcStatus : 48|1@1+ (1,0) [0|1] "" Vector__XXX
 SG_ J20122ByteDtcOccurrenceCount : 49|7@1+ (1,0) [0|126] "count" Vector__XXX

BO_ 2633869310 VROM: 8 Vector__XXX
 SG_ VltgRgltrLdCmpnstnMd : 0|3@1+ (1,0) [0|7] "" Vector__XXX
 SG_ VoltageRegulatorEnabled : 10|2@1+ (1,0) [0|3] "" Vector__XXX
 SG_ VoltageRegulatorSoftStartState : 8|2@1+ (1,0) [0|3] "" Vector__XXX
 SG_ VltgRgltrVrPwrFtrOprtngMd : 3|3@1+ (1,0) [0|7] "" Vector__XXX
 SG_ VltgRgltrUndrfrqnCmpnstnEnld : 6|2@1+ (1,0) [0|3] "" Vector__XXX

BO_ 2633878014 CMI: 8 Vector__XXX
 SG_ TtlCntOfCnfgrtnChngsMd : 0|16@1+ (1,0) [0|64255] "count" Vector__XXX

BO_ 2633880062 FMS: 8 Vector__XXX
 SG_ FmsStandardDiagnosticsSupported : 0|2@1+ (1,0) [0|3] "" Vector__XXX
 SG_ FmsStandardRequestsSupported : 2|2@1+ (1,0) [0|3] "" Vector__XXX
 SG_ FmsStandardSwVersionSupported : 8|32@1+ (1,0) [0|255] "" Vector__XXX

BO_ 2633883646 FWD: 8 Vector__XXX
 SG_ FrontWheelDriveActuatorStatus : 0|2@1+ (1,0) [0|3] "" Vector__XXX

BO_ 2633911806 TAVG: 8 Vector__XXX
 SG_ EngineTotalAverageFuelEconomy : 16|16@1+ (0.001953125,0) [0|125.498046875] "km/L" Vector__XXX
 SG_ EngineTotalAverageFuelRate : 0|16@1+ (0.05,0) [0|3212.75] "l/h" Vector__XXX

BO_ 2633922558 AP: 8 Vector__XXX
 SG_ AuxiliaryGagePressureReading1 : 16|16@1+ (0.5,0) [0|32127.5] "kPa" Vector__XXX
 SG_ AuxiliaryVacuumPressureReading : 0|16@1+ (0.5,0) [0|32127.5] "kPa" Vector__XXX
 SG_ AxlrAsltPrssrRdng : 32|16@1+ (0.5,0) [0|32127.5] "kPa" Vector__XXX

BO_ 2633922814 TP1: 8 Vector__XXX
 SG_ DriveChannelMode : 20|4@1+ (1,0) [0|15] "" Vector__XXX
 SG_ PcuControlSolenoidStatus : 34|2@1+ (1,0) [0|3] "" Vector__XXX
 SG_ PcuDeflateSolenoidStatus : 32|2@1+ (1,0) [0|3] "" Vector__XXX
 SG_ PcuDriveSolenoidStatus : 24|2@1+ (1,0) [0|3] "" Vector__XXX
 SG_ PcuSteerSolenoidStatus : 26|2@1+ (1,0) [0|3] "" Vector__XXX
 SG_ PcuSupplySolenoidStatus : 36|2@1+ (1,0) [0|3] "" Vector__XXX
 SG_ SteerChannelMode : 8|4@1+ (1,0) [0|15] "" Vector__XXX
 SG_ TirePressureCheckInterval : 0|8@1+ (1,0) [0|250] "min" Vector__XXX
 SG_ TirePressureSupplySwitchStatus : 28|2@1+ (1,0) [0|3] "" Vector__XXX
 SG_ TrailerTagChannelMode : 16|4@1+ (1,0) [0|15] "" Vector__XXX
 SG_ PTrlrTgOrPshSlndStts : 38|2@1+ (1,0) [0|3] "" Vector__XXX

BO_ 2633923070 TP2: 8 Vector__XXX
 SG_ DriveChannelTirePressureTarget : 16|16@1+ (0.5,0) [0|32127.5] "kPa" Vector__XXX
 SG_ SteerChannelTirePressureTarget : 32|16@1+ (0.5,0) [0|32127.5] "kPa" Vector__XXX
 SG_ TrlrTgOrPshChnnlTrPrssrTrgt : 0|16@1+ (0.5,0) [0|32127.5] "kPa" Vector__XXX

BO_ 2633923326 TP3: 8 Vector__XXX
 SG_ DriveChannelTirePressure : 16|16@1+ (0.5,0) [0|32127.5] "kPa" Vector__XXX
 SG_ SteerChannelTirePressure : 32|16@1+ (0.5,0) [0|32127.5] "kPa" Vector__XXX
 SG_ TrlrTgOrPshChnnlTrPrssr : 0|16@1+ (0.5,0) [0|32127.5] "kPa" Vector__XXX

BO_ 2633923582 CT1: 8 Vector__XXX
 SG_ EngineCylinder1CombustionTime : 0|16@1+ (0.01,0) [0|642.55] "ms" Vector__XXX
 SG_ EngineCylinder2CombustionTime : 16|16@1+ (0.01,0) [0|642.55] "ms" Vector__XXX
 SG_ EngineCylinder3CombustionTime : 32|16@1+ (0.01,0) [0|642.55] "ms" Vector__XXX
 SG_ EngineCylinder4CombustionTime : 48|16@1+ (0.01,0) [0|642.55] "ms" Vector__XXX

BO_ 2633923838 CT2: 8 Vector__XXX
 SG_ EngineCylinder5CombustionTime : 0|16@1+ (0.01,0) [0|642.55] "ms" Vector__XXX
 SG_ EngineCylinder6CombustionTime : 16|16@1+ (0.01,0) [0|642.55] "ms" Vector__XXX
 SG_ EngineCylinder7CombustionTime : 32|16@1+ (0.01,0) [0|642.55] "ms" Vector__XXX
 SG_ EngineCylinder8CombustionTime : 48|16@1+ (0.01,0) [0|642.55] "ms" Vector__XXX

BO_ 2633924094 CT3: 8 Vector__XXX
 SG_ EngineCylinder10CombustionTime : 16|16@1+ (0.01,0) [0|642.55] "ms" Vector__XXX
 SG_ EngineCylinder11CombustionTime : 32|16@1+ (0.01,0) [0|642.55] "ms" Vector__XXX
 SG_ EngineCylinder12CombustionTime : 48|16@1+ (0.01,0) [0|642.55] "ms" Vector__XXX
 SG_ EngineCylinder9CombustionTime : 0|16@1+ (0.01,0) [0|642.55] "ms" Vector__XXX

BO_ 2633924350 CT4: 8 Vector__XXX
 SG_ EngineCylinder13CombustionTime : 0|16@1+ (0.01,0) [0|642.55] "ms" Vector__XXX
 SG_ EngineCylinder14CombustionTime : 16|16@1+ (0.01,0) [0|642.55] "ms" Vector__XXX
 SG_ EngineCylinder15CombustionTime : 32|16@1+ (0.01,0) [0|642.55] "ms" Vector__XXX
 SG_ EngineCylinder16CombustionTime : 48|16@1+ (0.01,0) [0|642.55] "ms" Vector__XXX

BO_ 2633924606 CT5: 8 Vector__XXX
 SG_ EngineCylinder17CombustionTime : 0|16@1+ (0.01,0) [0|642.55] "ms" Vector__XXX
 SG_ EngineCylinder18CombustionTime : 16|16@1+ (0.01,0) [0|642.55] "ms" Vector__XXX
 SG_ EngineCylinder19CombustionTime : 32|16@1+ (0.01,0) [0|642.55] "ms" Vector__XXX
 SG_ EngineCylinder20CombustionTime : 48|16@1+ (0.01,0) [0|642.55] "ms" Vector__XXX

BO_ 2633924862 CT6: 8 Vector__XXX
 SG_ EngineAverageCombustionTime : 16|16@1+ (0.01,0) [0|642.55] "ms" Vector__XXX
 SG_ EngineDesiredCombustionTime : 0|16@1+ (0.01,0) [0|642.55] "ms" Vector__XXX

BO_ 2633925118 GFI2: 8 Vector__XXX
 SG_ EngineFuelFlowRate1 : 0|16@1+ (0.1,0) [0|6425.5] "(m*m*m)/h" Vector__XXX
 SG_ EngineFuelFlowRate2 : 16|16@1+ (0.1,0) [0|6425.5] "(m*m*m)/h" Vector__XXX
 SG_ EngineFuelValve1Position : 32|8@1+ (0.4,0) [0|100] "%" Vector__XXX
 SG_ EngineFuelValve2Position : 40|8@1+ (0.4,0) [0|100] "%" Vector__XXX
 SG_ EngnFlVlv1CmmnddPstn : 48|8@1+ (0.4,0) [0|100] "%" Vector__XXX
 SG_ EngnFlVlv2CmmnddPstn : 56|8@1+ (0.4,0) [0|100] "%" Vector__XXX

BO_ 2633925374 IT1: 8 Vector__XXX
 SG_ EngineCylinder1IgnitionTiming : 0|16@1+ (0.0078125,-200) [-200|301.9921875] "deg" Vector__XXX
 SG_ EngineCylinder2IgnitionTiming : 16|16@1+ (0.0078125,-200) [-200|301.9921875] "deg" Vector__XXX
 SG_ EngineCylinder3IgnitionTiming : 32|16@1+ (0.0078125,-200) [-200|301.9921875] "deg" Vector__XXX
 SG_ EngineCylinder4IgnitionTiming : 48|16@1+ (0.0078125,-200) [-200|301.9921875] "deg" Vector__XXX

BO_ 2633925630 IT2: 8 Vector__XXX
 SG_ EngineCylinder5IgnitionTiming : 0|16@1+ (0.0078125,-200) [-200|301.9921875] "deg" Vector__XXX
 SG_ EngineCylinder6IgnitionTiming : 16|16@1+ (0.0078125,-200) [-200|301.9921875] "deg" Vector__XXX
 SG_ EngineCylinder7IgnitionTiming : 32|16@1+ (0.0078125,-200) [-200|301.9921875] "deg" Vector__XXX
 SG_ EngineCylinder8IgnitionTiming : 48|16@1+ (0.0078125,-200) [-200|301.9921875] "deg" Vector__XXX

BO_ 2633925886 IT3: 8 Vector__XXX
 SG_ EngineCylinder10IgnitionTiming : 16|16@1+ (0.0078125,-200) [-200|301.9921875] "deg" Vector__XXX
 SG_ EngineCylinder11IgnitionTiming : 32|16@1+ (0.0078125,-200) [-200|301.9921875] "deg" Vector__XXX
 SG_ EngineCylinder12IgnitionTiming : 48|16@1+ (0.0078125,-200) [-200|301.9921875] "deg" Vector__XXX
 SG_ EngineCylinder9IgnitionTiming : 0|16@1+ (0.0078125,-200) [-200|301.9921875] "deg" Vector__XXX

BO_ 2633926142 IT4: 8 Vector__XXX
 SG_ EngineCylinder13IgnitionTiming : 0|16@1+ (0.0078125,-200) [-200|301.9921875] "deg" Vector__XXX
 SG_ EngineCylinder14IgnitionTiming : 16|16@1+ (0.0078125,-200) [-200|301.9921875] "deg" Vector__XXX
 SG_ EngineCylinder15IgnitionTiming : 32|16@1+ (0.0078125,-200) [-200|301.9921875] "deg" Vector__XXX
 SG_ EngineCylinder16IgnitionTiming : 48|16@1+ (0.0078125,-200) [-200|301.9921875] "deg" Vector__XXX

BO_ 2633926398 IT5: 8 Vector__XXX
 SG_ EngineCylinder17IgnitionTiming : 0|16@1+ (0.0078125,-200) [-200|301.9921875] "deg" Vector__XXX
 SG_ EngineCylinder18IgnitionTiming : 16|16@1+ (0.0078125,-200) [-200|301.9921875] "deg" Vector__XXX
 SG_ EngineCylinder19IgnitionTiming : 32|16@1+ (0.0078125,-200) [-200|301.9921875] "deg" Vector__XXX
 SG_ EngineCylinder20IgnitionTiming : 48|16@1+ (0.0078125,-200) [-200|301.9921875] "deg" Vector__XXX

BO_ 2633926654 IT6: 8 Vector__XXX
 SG_ EngineActualIgnitionTiming : 48|16@1+ (0.0078125,-200) [-200|301.9921875] "deg" Vector__XXX
 SG_ EngineDesiredIgnitionTiming1 : 0|16@1+ (0.0078125,-200) [-200|301.9921875] "deg" Vector__XXX
 SG_ EngineDesiredIgnitionTiming2 : 16|16@1+ (0.0078125,-200) [-200|301.9921875] "deg" Vector__XXX
 SG_ EngineDesiredIgnitionTiming3 : 32|16@1+ (0.0078125,-200) [-200|301.9921875] "deg" Vector__XXX

BO_ 2633926910 ISO1: 8 Vector__XXX
 SG_ EngnClndr1IgntnTrnsfrmrSndrOtpt : 0|8@1+ (1,-125) [-125|125] "%" Vector__XXX
 SG_ EngnClndr2IgntnTrnsfrmrSndrOtpt : 8|8@1+ (1,-125) [-125|125] "%" Vector__XXX
 SG_ EngnClndr3IgntnTrnsfrmrSndrOtpt : 16|8@1+ (1,-125) [-125|125] "%" Vector__XXX
 SG_ EngnClndr4IgntnTrnsfrmrSndrOtpt : 24|8@1+ (1,-125) [-125|125] "%" Vector__XXX
 SG_ EngnClndr5IgntnTrnsfrmrSndrOtpt : 32|8@1+ (1,-125) [-125|125] "%" Vector__XXX
 SG_ EngnClndr6IgntnTrnsfrmrSndrOtpt : 40|8@1+ (1,-125) [-125|125] "%" Vector__XXX
 SG_ EngnClndr7IgntnTrnsfrmrSndrOtpt : 48|8@1+ (1,-125) [-125|125] "%" Vector__XXX
 SG_ EngnClndr8IgntnTrnsfrmrSndrOtpt : 56|8@1+ (1,-125) [-125|125] "%" Vector__XXX

BO_ 2633927166 ISO2: 8 Vector__XXX
 SG_ ECd10ItTsSdOtpt : 8|8@1+ (1,-125) [-125|125] "%" Vector__XXX
 SG_ ECd11ItTsSdOtpt : 16|8@1+ (1,-125) [-125|125] "%" Vector__XXX
 SG_ ECd12ItTsSdOtpt : 24|8@1+ (1,-125) [-125|125] "%" Vector__XXX
 SG_ ECd13ItTsSdOtpt : 32|8@1+ (1,-125) [-125|125] "%" Vector__XXX
 SG_ ECd14ItTsSdOtpt : 40|8@1+ (1,-125) [-125|125] "%" Vector__XXX
 SG_ ECd15ItTsSdOtpt : 48|8@1+ (1,-125) [-125|125] "%" Vector__XXX
 SG_ ECd16ItTsSdOtpt : 56|8@1+ (1,-125) [-125|125] "%" Vector__XXX
 SG_ EngnClndr9IgntnTrnsfrmrSndrOtpt : 0|8@1+ (1,-125) [-125|125] "%" Vector__XXX

BO_ 2633927422 ISO3: 8 Vector__XXX
 SG_ ECd17ItTsSdOtpt : 0|8@1+ (1,-125) [-125|125] "%" Vector__XXX
 SG_ ECd18ItTsSdOtpt : 8|8@1+ (1,-125) [-125|125] "%" Vector__XXX
 SG_ ECd19ItTsSdOtpt : 16|8@1+ (1,-125) [-125|125] "%" Vector__XXX
 SG_ ECd20ItTsSdOtpt : 24|8@1+ (1,-125) [-125|125] "%" Vector__XXX

BO_ 2633927678 GFP1: 8 Vector__XXX
 SG_ EngnArTFlDffrntlPrssr : 32|16@1+ (0.1,0) [0|6425.5] "kPa" Vector__XXX
 SG_ EngnFlVlv1DffrntlPrssr : 16|16@1+ (0.1,0) [0|6425.5] "kPa" Vector__XXX
 SG_ EngnFlVlv1IntkAsltPrssr : 0|16@1+ (0.1,0) [0|6425.5] "kPa" Vector__XXX
 SG_ EngnFlVlv1OtltAsltPrssr : 48|16@1+ (0.1,0) [0|6425.5] "kPa" Vector__XXX

BO_ 2633927934 AAI: 8 Vector__XXX
 SG_ AuxiliaryLevel : 32|16@1+ (0.1,0) [0|6425.5] "mm" Vector__XXX
 SG_ AuxiliaryPressure1 : 16|8@1+ (16,0) [0|4000] "kPa" Vector__XXX
 SG_ AuxiliaryPressure2 : 24|8@1+ (16,0) [0|4000] "kPa" Vector__XXX
 SG_ AuxiliaryTemperature1 : 0|8@1+ (1,-40) [-40|210] "degC" Vector__XXX
 SG_ AuxiliaryTemperature2 : 8|8@1+ (1,-40) [-40|210] "degC" Vector__XXX
 SG_ RelativeHumidity : 48|8@1+ (0.4,0) [0|100] "%" Vector__XXX
 SG_ AuxiliaryTemperature3 : 56|8@1+ (1,-40) [-40|210] "degC" Vector__XXX

BO_ 2633928446 S2: 8 Vector__XXX
 SG_ ServiceComponentIdentification : 0|8@1+ (1,0) [0|250] "ID" Vector__XXX
 SG_ TimeSinceLastService : 8|16@1+ (1,-32127) [-32127|32128] "h" Vector__XXX

BO_ 2633929214 FL: 8 Vector__XXX
 SG_ EngineFluidBundLevel : 8|8@1+ (0.4,0) [0|100] "%" Vector__XXX
 SG_ EngineFuelLeakage1 : 0|2@1+ (1,0) [0|3] "" Vector__XXX
 SG_ EngineFuelLeakage2 : 2|2@1+ (1,0) [0|3] "" Vector__XXX

BO_ 2633929470 EI1: 8 Vector__XXX
 SG_ EngineFuelRackPosition : 24|8@1+ (0.4,0) [0|100] "%" Vector__XXX
 SG_ EngineOilFilterIntakePressure : 0|8@1+ (4,0) [0|1000] "kPa" Vector__XXX
 SG_ EngnFlSstm1GsMssFlwRt : 32|16@1+ (0.05,0) [0|3212.75] "kg/h" Vector__XXX
 SG_ InstntnsEstmtdBrkPwr : 48|16@1+ (0.5,0) [0|32127.5] "kW" Vector__XXX
 SG_ EngineExhaustBank1Pressure1 : 8|16@1+ (0.0078125,-250) [-250|251.9921875] "kPa" Vector__XXX

BO_ 2633929726 EES: 8 Vector__XXX
 SG_ ElectricalLoad : 0|16@1+ (0.5,0) [0|32127.5] "kW" Vector__XXX
 SG_ EngineTurningGearEngaged : 18|2@1+ (1,0) [0|3] "" Vector__XXX
 SG_ SafetyWireStatus : 16|2@1+ (1,0) [0|3] "" Vector__XXX

BO_ 2633930238 RBI: 8 Vector__XXX
 SG_ EngineOperationTimeSinceRebuild : 0|32@1+ (1,0) [0|4211081215] "s" Vector__XXX

BO_ 2633931774 TCI1: 8 Vector__XXX
 SG_ EngineTurbocharger2Speed : 8|16@1+ (4,0) [0|257020] "rpm" Vector__XXX
 SG_ EngineTurbocharger3Speed : 24|16@1+ (4,0) [0|257020] "rpm" Vector__XXX
 SG_ EngineTurbocharger4Speed : 40|16@1+ (4,0) [0|257020] "rpm" Vector__XXX
 SG_ EngnTrhrgrLOlPrssr2 : 0|8@1+ (4,0) [0|1000] "kPa" Vector__XXX

BO_ 2633932798 EPT5: 8 Vector__XXX
 SG_ EngnExhstGsPrt17Tmprtr : 0|16@1+ (0.03125,-273) [-273|1734.96875] "degC" Vector__XXX
 SG_ EngnExhstGsPrt18Tmprtr : 16|16@1+ (0.03125,-273) [-273|1734.96875] "degC" Vector__XXX
 SG_ EngnExhstGsPrt19Tmprtr : 32|16@1+ (0.03125,-273) [-273|1734.96875] "degC" Vector__XXX
 SG_ EngnExhstGsPrt20Tmprtr : 48|16@1+ (0.03125,-273) [-273|1734.96875] "degC" Vector__XXX

BO_ 2633933310 EPT3: 8 Vector__XXX
 SG_ EngnExhstGsPrt10Tmprtr : 16|16@1+ (0.03125,-273) [-273|1734.96875] "degC" Vector__XXX
 SG_ EngnExhstGsPrt11Tmprtr : 32|16@1+ (0.03125,-273) [-273|1734.96875] "degC" Vector__XXX
 SG_ EngnExhstGsPrt12Tmprtr : 48|16@1+ (0.03125,-273) [-273|1734.96875] "degC" Vector__XXX
 SG_ EngnExhstGsPrt9Tmprtr : 0|16@1+ (0.03125,-273) [-273|1734.96875] "degC" Vector__XXX

BO_ 2633933566 EPT2: 8 Vector__XXX
 SG_ EngnExhstGsPrt5Tmprtr : 0|16@1+ (0.03125,-273) [-273|1734.96875] "degC" Vector__XXX
 SG_ EngnExhstGsPrt6Tmprtr : 16|16@1+ (0.03125,-273) [-273|1734.96875] "degC" Vector__XXX
 SG_ EngnExhstGsPrt7Tmprtr : 32|16@1+ (0.03125,-273) [-273|1734.96875] "degC" Vector__XXX
 SG_ EngnExhstGsPrt8Tmprtr : 48|16@1+ (0.03125,-273) [-273|1734.96875] "degC" Vector__XXX

BO_ 2633933822 EPT1: 8 Vector__XXX
 SG_ EngnExhstGsPrt1Tmprtr : 0|16@1+ (0.03125,-273) [-273|1734.96875] "degC" Vector__XXX
 SG_ EngnExhstGsPrt2Tmprtr : 16|16@1+ (0.03125,-273) [-273|1734.96875] "degC" Vector__XXX
 SG_ EngnExhstGsPrt3Tmprtr : 32|16@1+ (0.03125,-273) [-273|1734.96875] "degC" Vector__XXX
 SG_ EngnExhstGsPrt4Tmprtr : 48|16@1+ (0.03125,-273) [-273|1734.96875] "degC" Vector__XXX

BO_ 2633934334 IMT2: 8 Vector__XXX
 SG_ EngnIntkMnfld2Tmprtr : 0|8@1+ (1,-40) [-40|210] "degC" Vector__XXX
 SG_ EngnIntkMnfld3Tmprtr : 8|8@1+ (1,-40) [-40|210] "degC" Vector__XXX
 SG_ EngnIntkMnfld4Tmprtr : 16|8@1+ (1,-40) [-40|210] "degC" Vector__XXX
 SG_ EngnIntkMnfld5Tmprtr : 24|8@1+ (1,-40) [-40|210] "degC" Vector__XXX
 SG_ EngnIntkMnfld6Tmprtr : 32|8@1+ (1,-40) [-40|210] "degC" Vector__XXX
 SG_ DsrdEngnIntkMnfldTmprtr : 40|8@1+ (1,-40) [-40|210] "degC" Vector__XXX
 SG_ DsrdEngnIntkMnfldTmprtrHghLmt : 48|8@1+ (1,-40) [-40|210] "degC" Vector__XXX

BO_ 2633934846 AT1: 8 Vector__XXX
 SG_ EngnAltrntrBrng1Tmprtr : 0|8@1+ (1,-40) [-40|210] "degC" Vector__XXX
 SG_ EngnAltrntrBrng2Tmprtr : 8|8@1+ (1,-40) [-40|210] "degC" Vector__XXX
 SG_ EngnAltrntrWndng1Tmprtr : 16|8@1+ (1,-40) [-40|210] "degC" Vector__XXX
 SG_ EngnAltrntrWndng2Tmprtr : 24|8@1+ (1,-40) [-40|210] "degC" Vector__XXX
 SG_ EngnAltrntrWndng3Tmprtr : 32|8@1+ (1,-40) [-40|210] "degC" Vector__XXX
 SG_ EngnAltrntrWndng4Tmprtr : 40|8@1+ (1,-40) [-40|210] "degC" Vector__XXX
 SG_ EngnAltrntrWndng5Tmprtr : 48|8@1+ (1,-40) [-40|210] "degC" Vector__XXX
 SG_ EngnAltrntrWndng6Tmprtr : 56|8@1+ (1,-40) [-40|210] "degC" Vector__XXX

BO_ 2633935102 ACTL: 8 Vector__XXX
 SG_ ArticulationAngle : 0|8@1+ (1,-125) [-125|125] "deg" Vector__XXX
 SG_ ArticulationAngularVelocity : 8|16@1+ (0.0078125,-250) [-250|251.9921875] "deg/s" Vector__XXX

BO_ 2633935358 EO1: 8 Vector__XXX
 SG_ EngineActualExhaust1Oxygen : 32|16@1+ (0.0025,0) [0|160.6375] "%" Vector__XXX
 SG_ EngineDesiredExhaustOxygen : 16|16@1+ (0.0025,0) [0|160.6375] "%" Vector__XXX
 SG_ EngineDesiredRatedExhaustOxygen : 0|16@1+ (0.0025,0) [0|160.6375] "%" Vector__XXX
 SG_ EngnExhstO2SnsrClsdLpOprtn : 62|2@1+ (1,0) [0|3] "" Vector__XXX
 SG_ EngnExhstO2SnsrFlngCrrtn : 48|8@1+ (1,-125) [-125|125] "%" Vector__XXX

BO_ 2633935614 AF2: 8 Vector__XXX
 SG_ EFSstGsMssFwRtSsFCt : 32|8@1+ (1,-125) [-125|125] "%" Vector__XXX
 SG_ EngnIntkMnfldDsrdAsltPrssr : 8|16@1+ (0.1,0) [0|6425.5] "kPa" Vector__XXX
 SG_ EngnTrhrgrWstgtVlvPstn : 24|8@1+ (0.4,0) [0|100] "%" Vector__XXX
 SG_ GaseousFuelCorrectionFactor : 0|8@1+ (1,0) [0|250] "%" Vector__XXX
 SG_ GssFlInjtnPlsCrrtnFtr : 40|16@1+ (0.0078125,-251) [0|150] "%" Vector__XXX

BO_ 2633935870 ETC6: 8 Vector__XXX
 SG_ ClutchLifeRemaining : 24|8@1+ (0.4,0) [0|100] "%" Vector__XXX
 SG_ HighestPossibleGear : 8|8@1+ (1,-125) [-125|125] "gear value" Vector__XXX
 SG_ LowestPossibleGear : 16|8@1+ (1,-125) [-125|125] "gear value" Vector__XXX
 SG_ RecommendedGear : 0|8@1+ (1,-125) [-125|125] "gear value" Vector__XXX

BO_ 2633936126 EBC4: 8 Vector__XXX
 SG_ BrkLnngRmnngFrntAxlLftWhl : 0|8@1+ (0.4,0) [0|100] "%" Vector__XXX
 SG_ BrkLnngRmnngFrntAxlRghtWhl : 8|8@1+ (0.4,0) [0|100] "%" Vector__XXX
 SG_ BrkLnngRmnngRrAxl1LftWhl : 16|8@1+ (0.4,0) [0|100] "%" Vector__XXX
 SG_ BrkLnngRmnngRrAxl1RghtWhl : 24|8@1+ (0.4,0) [0|100] "%" Vector__XXX
 SG_ BrkLnngRmnngRrAxl2LftWhl : 32|8@1+ (0.4,0) [0|100] "%" Vector__XXX
 SG_ BrkLnngRmnngRrAxl2RghtWhl : 40|8@1+ (0.4,0) [0|100] "%" Vector__XXX
 SG_ BrkLnngRmnngRrAxl3LftWhl : 48|8@1+ (0.4,0) [0|100] "%" Vector__XXX
 SG_ BrkLnngRmnngRrAxl3RghtWhl : 56|8@1+ (0.4,0) [0|100] "%" Vector__XXX

BO_ 2633936894 GFC: 8 Vector__XXX
 SG_ TotalFuelUsedGaseous : 32|32@1+ (0.5,0) [0|2105540607.5] "kg" Vector__XXX
 SG_ TripFuelGaseous : 0|32@1+ (0.5,0) [0|2105540607.5] "kg" Vector__XXX

BO_ 2633937150 TTI2: 20 Vector__XXX
 SG_ TripAirCompressorOnTime : 128|32@1+ (0.05,0) [0|210554060.75] "h" Vector__XXX
 SG_ TripCruiseTime : 0|32@1+ (0.05,0) [0|210554060.75] "h" Vector__XXX
 SG_ TripEngineRunningTime : 64|32@1+ (0.05,0) [0|210554060.75] "h" Vector__XXX
 SG_ TripIdleTime : 96|32@1+ (0.05,0) [0|210554060.75] "h" Vector__XXX
 SG_ TripPtoGovernorTime : 32|32@1+ (0.05,0) [0|210554060.75] "h" Vector__XXX

BO_ 2633937406 EH: 8 Vector__XXX
 SG_ TotalEcuDistance : 0|32@1+ (0.125,0) [0|526385151.875] "km" Vector__XXX
 SG_ TotalEcuRunTime : 32|32@1+ (0.05,0) [0|210554060.75] "h" Vector__XXX

BO_ 2633937662 GFI1: 8 Vector__XXX
 SG_ EngineFuelSpecificGravity : 48|16@1+ (0.0001,0) [0|2] "" Vector__XXX
 SG_ TripAverageFuelRateGaseous : 32|16@1+ (0.05,0) [0|3212.75] "kg/h" Vector__XXX
 SG_ TtlEngnPtGvrnrFlUsdGss : 0|32@1+ (0.5,0) [0|2105540607.5] "kg" Vector__XXX

BO_ 2633937918 LFI1: 8 Vector__XXX
 SG_ FlexibleFuelPercentage : 48|16@1+ (0.0025,0) [0|100] "%" Vector__XXX
 SG_ TotalEnginePtoGovernorFuelUsed : 0|32@1+ (0.5,0) [0|2105540607.5] "l" Vector__XXX
 SG_ TripAverageFuelRate : 32|16@1+ (0.05,0) [0|3212.75] "l/h" Vector__XXX

BO_ 2633938174 TTI1: 16 Vector__XXX
 SG_ TripTimeInDerateByEngine : 96|32@1+ (0.05,0) [0|210554060.75] "h" Vector__XXX
 SG_ TripTimeInGearDown : 64|32@1+ (0.05,0) [0|210554060.75] "h" Vector__XXX
 SG_ TripTimeInTopGear : 32|32@1+ (0.05,0) [0|210554060.75] "h" Vector__XXX
 SG_ TripTimeInVsl : 0|32@1+ (0.05,0) [0|210554060.75] "h" Vector__XXX

BO_ 2633938430 TSI: 8 Vector__XXX
 SG_ TripNumberOfHotShutdowns : 0|16@1+ (1,0) [0|64255] "count" Vector__XXX
 SG_ TripNumberOfIdleShutdowns : 16|16@1+ (1,0) [0|64255] "count" Vector__XXX
 SG_ TripSuddenDecelerations : 48|16@1+ (1,0) [0|64255] "count" Vector__XXX
 SG_ TrpNmrOfIdlShtdwnOvrrds : 32|16@1+ (1,0) [0|64255] "count" Vector__XXX

BO_ 2633938686 TVI: 8 Vector__XXX
 SG_ TripCruiseDistance : 16|32@1+ (0.125,0) [0|526385151.875] "km" Vector__XXX
 SG_ TripMaximumVehicleSpeed : 0|16@1+ (0.00390625,0) [0|250.99609375] "km/h" Vector__XXX

BO_ 2633938942 LF1: 10 Vector__XXX
 SG_ TotalEngineCruiseTime : 48|32@1+ (0.05,0) [0|210554060.75] "h" Vector__XXX
 SG_ TripAverageEngineSpeed : 16|16@1+ (0.125,0) [0|8031.875] "rpm" Vector__XXX
 SG_ TripMaximumEngineSpeed : 0|16@1+ (0.125,0) [0|8031.875] "rpm" Vector__XXX
 SG_ TripDriveAverageLoadFactor : 32|8@1+ (0.4,0) [0|100] "%" Vector__XXX
 SG_ TotalDriveAverageLoadFactor : 40|8@1+ (0.4,0) [0|100] "%" Vector__XXX

BO_ 2633939198 GTFI: 22 Vector__XXX
 SG_ TripCruiseFuelUsedGaseous : 128|32@1+ (0.5,0) [0|2105540607.5] "kg" Vector__XXX
 SG_ TripDriveFuelEconomyGaseous : 160|16@1+ (0.001953125,0) [0|125.498046875] "km/kg" Vector__XXX
 SG_ TripDriveFuelUsedGaseous : 0|32@1+ (0.5,0) [0|2105540607.5] "kg" Vector__XXX
 SG_ TripVehicleIdleFuelUsedGaseous : 96|32@1+ (0.5,0) [0|2105540607.5] "kg" Vector__XXX
 SG_ TrpPtGvrnrMvngFlUsdGss : 32|32@1+ (0.5,0) [0|2105540607.5] "kg" Vector__XXX
 SG_ TrpPtGvrnrNnMvngFlUsdGss : 64|32@1+ (0.5,0) [0|2105540607.5] "kg" Vector__XXX

BO_ 2633939454 LTFI: 22 Vector__XXX
 SG_ TripCruiseFuelUsed : 128|32@1+ (0.5,0) [0|2105540607.5] "l" Vector__XXX
 SG_ TripDriveFuelEconomy : 160|16@1+ (0.001953125,0) [0|125.498046875] "km/L" Vector__XXX
 SG_ TripDriveFuelUsed : 0|32@1+ (0.5,0) [0|2105540607.5] "l" Vector__XXX
 SG_ TripPtoGovernorMovingFuelUsed : 32|32@1+ (0.5,0) [0|2105540607.5] "l" Vector__XXX
 SG_ TripVehicleIdleFuelUsed : 96|32@1+ (0.5,0) [0|2105540607.5] "l" Vector__XXX
 SG_ TrpPtGvrnrNnMvngFlUsd : 64|32@1+ (0.5,0) [0|2105540607.5] "l" Vector__XXX

BO_ 2633939710 TDI: 12 Vector__XXX
 SG_ TripDistanceInTopGear : 64|32@1+ (0.125,0) [0|526385151.875] "km" Vector__XXX
 SG_ TripDistanceOnVsl : 0|32@1+ (0.125,0) [0|526385151.875] "km" Vector__XXX
 SG_ TripGearDownDistance : 32|32@1+ (0.125,0) [0|526385151.875] "km" Vector__XXX

BO_ 2633939966 TFI: 16 Vector__XXX
 SG_ TripFanOnTime : 0|32@1+ (0.05,0) [0|210554060.75] "h" Vector__XXX
 SG_ TripFanOnTimeDueToAManualSwitch : 64|32@1+ (0.05,0) [0|210554060.75] "h" Vector__XXX
 SG_ TripFanOnTimeDueToTheACSystem : 96|32@1+ (0.05,0) [0|210554060.75] "h" Vector__XXX
 SG_ TrpFnOnTmDTThEngnSstm : 32|32@1+ (0.05,0) [0|210554060.75] "h" Vector__XXX

BO_ 2633940222 CBI: 16 Vector__XXX
 SG_ TotalCompressionBrakeDistance : 0|32@1+ (0.125,0) [0|526385151.875] "km" Vector__XXX
 SG_ TripCompressionBrakeDistance : 32|32@1+ (0.125,0) [0|526385151.875] "km" Vector__XXX
 SG_ TripServiceBrakeApplications : 96|32@1+ (1,0) [0|4211081215] "brake appl" Vector__XXX
 SG_ TripServiceBrakeDistance : 64|32@1+ (0.125,0) [0|526385151.875] "km" Vector__XXX

BO_ 2633940734 EEC4: 8 Vector__XXX
 SG_ EngineRatedPower : 0|16@1+ (0.5,0) [0|32127.5] "kW" Vector__XXX
 SG_ EngineRatedSpeed : 16|16@1+ (0.125,0) [0|8031.875] "rpm" Vector__XXX
 SG_ EngineRotationDirection : 32|2@1+ (1,0) [0|3] "" Vector__XXX
 SG_ EngnIntkMnfldPrssrCntrlMd : 34|2@1+ (1,0) [0|3] "" Vector__XXX
 SG_ EngnPrlOlLwPrssrThrshld : 48|8@1+ (4,0) [0|1000] "kPa" Vector__XXX
 SG_ CrnkAttmptCntOnPrsntStrtAttmpt : 40|8@1+ (1,0) [0|250] "count" Vector__XXX

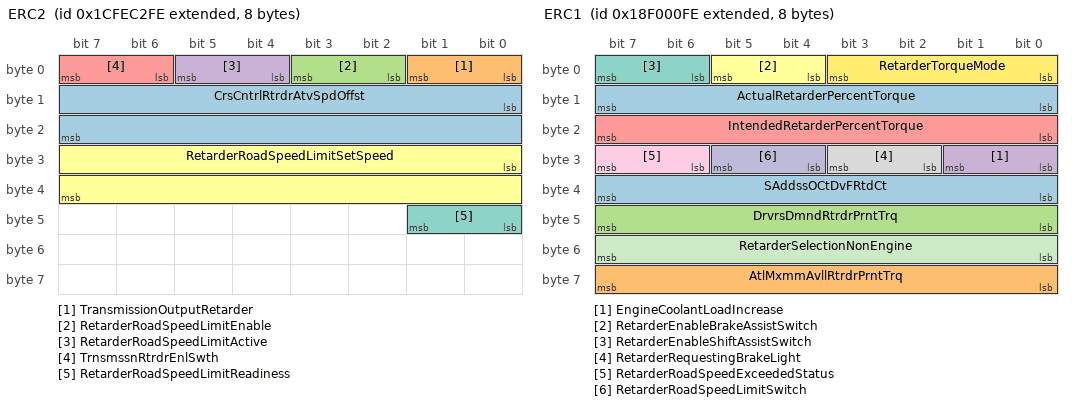
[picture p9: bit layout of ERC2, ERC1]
BO_ 2633941758 ERC2: 8 Vector__XXX
 SG_ CrsCntrlRtrdrAtvSpdOffst : 8|16@1+ (0.00390625,-125) [0|125.996] "km/h" Vector__XXX
 SG_ TransmissionOutputRetarder : 0|2@1+ (1,0) [0|3] "" Vector__XXX
 SG_ RetarderRoadSpeedLimitEnable : 2|2@1+ (1,0) [0|3] "" Vector__XXX
 SG_ RetarderRoadSpeedLimitActive : 4|2@1+ (1,0) [0|3] "" Vector__XXX
 SG_ TrnsmssnRtrdrEnlSwth : 6|2@1+ (1,0) [0|3] "" Vector__XXX
 SG_ RetarderRoadSpeedLimitSetSpeed : 24|16@1+ (0.00390625,0) [0|250.99609375] "km/h" Vector__XXX
 SG_ RetarderRoadSpeedLimitReadiness : 40|2@1+ (1,0) [0|3] "" Vector__XXX

BO_ 2633942014 ETC5: 8 Vector__XXX
 SG_ TransmissionLowRangeSenseSwitch : 2|2@1+ (1,0) [0|3] "" Vector__XXX
 SG_ TransmissionNeutralSwitch : 10|2@1+ (1,0) [0|3] "" Vector__XXX
 SG_ TrnsmssnFrwrdDrtnSwth : 12|2@1+ (1,0) [0|3] "" Vector__XXX
 SG_ TrnsmssnHghRngSnsSwth : 0|2@1+ (1,0) [0|3] "" Vector__XXX
 SG_ TrnsmssnRvrsDrtnSwth : 8|2@1+ (1,0) [0|3] "" Vector__XXX
 SG_ TransmissionSplitterPosition : 4|2@1+ (1,0) [0|3] "" Vector__XXX

BO_ 2633942526 ETC4: 8 Vector__XXX
 SG_ TrnsmssnSnhrnzrBrkVl : 8|8@1+ (0.4,0) [0|100] "%" Vector__XXX
 SG_ TrnsmssnSnhrnzrClthVl : 0|8@1+ (0.4,0) [0|100] "%" Vector__XXX

BO_ 2633943038 ETC3: 8 Vector__XXX
 SG_ TransmissionClutchActuator : 40|2@1+ (1,0) [0|3] "" Vector__XXX
 SG_ TransmissionDefuelActuator : 44|2@1+ (1,0) [0|3] "" Vector__XXX
 SG_ TransmissionRangeHighActuator : 32|2@1+ (1,0) [0|3] "" Vector__XXX
 SG_ TransmissionRangeLowActuator : 34|2@1+ (1,0) [0|3] "" Vector__XXX
 SG_ TrnsmssnInrtBrkAttr : 46|2@1+ (1,0) [0|3] "" Vector__XXX
 SG_ TrnsmssnShftFngrCntrRlIndtr : 20|2@1+ (1,0) [0|3] "" Vector__XXX
 SG_ TrnsmssnShftFngrEnggmntIndtr : 18|2@1+ (1,0) [0|3] "" Vector__XXX
 SG_ TrnsmssnShftFngrGrAttr1 : 26|2@1+ (1,0) [0|3] "" Vector__XXX
 SG_ TrnsmssnShftFngrGrAttr2 : 30|2@1+ (1,0) [0|3] "" Vector__XXX
 SG_ TrnsmssnShftFngrGrPstn : 0|8@1+ (0.4,0) [0|100] "%" Vector__XXX
 SG_ TrnsmssnShftFngrNtrlIndtr : 16|2@1+ (1,0) [0|3] "" Vector__XXX
 SG_ TrnsmssnShftFngrRlAttr1 : 24|2@1+ (1,0) [0|3] "" Vector__XXX
 SG_ TrnsmssnShftFngrRlAttr2 : 28|2@1+ (1,0) [0|3] "" Vector__XXX
 SG_ TrnsmssnShftFngrRlPstn : 8|8@1+ (0.4,0) [0|100] "%" Vector__XXX
 SG_ TrnsmssnSplttrDrtAttr : 36|2@1+ (1,0) [0|3] "" Vector__XXX
 SG_ TrnsmssnSplttrIndrtAttr : 38|2@1+ (1,0) [0|3] "" Vector__XXX
 SG_ TrnsmssnTrqCnvrtrLkpClthAttr : 42|2@1+ (1,0) [0|3] "" Vector__XXX

BO_ 2565865726 ERC1: 8 Vector__XXX
 SG_ ActualRetarderPercentTorque : 8|8@1+ (1,-125) [-125|0] "%" Vector__XXX
 SG_ AtlMxmmAvllRtrdrPrntTrq : 56|8@1+ (1,-125) [-125|0] "%" Vector__XXX
 SG_ DrvrsDmndRtrdrPrntTrq : 40|8@1+ (1,-125) [-125|0] "%" Vector__XXX
 SG_ EngineCoolantLoadIncrease : 24|2@1+ (1,0) [0|3] "" Vector__XXX
 SG_ IntendedRetarderPercentTorque : 16|8@1+ (1,-125) [-125|0] "%" Vector__XXX
 SG_ RetarderEnableBrakeAssistSwitch : 4|2@1+ (1,0) [0|3] "" Vector__XXX
 SG_ RetarderEnableShiftAssistSwitch : 6|2@1+ (1,0) [0|3] "" Vector__XXX
 SG_ RetarderRequestingBrakeLight : 26|2@1+ (1,0) [0|3] "" Vector__XXX
 SG_ RetarderRoadSpeedExceededStatus : 30|2@1+ (1,0) [0|3] "" Vector__XXX
 SG_ RetarderRoadSpeedLimitSwitch : 28|2@1+ (1,0) [0|3] "" Vector__XXX
 SG_ RetarderSelectionNonEngine : 48|8@1+ (0.4,0) [0|100] "%" Vector__XXX
 SG_ RetarderTorqueMode : 0|4@1+ (1,0) [0|15] "" Vector__XXX
 SG_ SAddssOCtDvFRtdCt : 32|8@1+ (1,0) [0|253] "sourceadr" Vector__XXX

BO_ 2499608830 EFLP10: 8 Vector__XXX
 SG_ EngineCoolantPressure2 : 56|8@1+ (2,0) [0|500] "kPa" Vector__XXX
 SG_ EngnExhstGsRrltn2DffrntlPrssr : 0|16@1+ (0.0078125,-250) [-250|251.9921875] "kPa" Vector__XXX
 SG_ EngnExhstGsRrltn2IntkAsltPrssr : 40|16@1+ (0.1,0) [0|6425.5] "kPa" Vector__XXX
 SG_ EngnExhstGsRrltn2IntkPrssr : 16|8@1+ (2,0) [0|500] "kPa" Vector__XXX
 SG_ EngnExhstGsRrltn2OtltAsltPrssr : 24|16@1+ (0.1,0) [0|6425.5] "kPa" Vector__XXX

BO_ 2365456638 GPBAC: 8 Vector__XXX
 SG_ GeneratorPhaseBAcFrequency : 32|16@1+ (0.0078125,0) [0|501.9921875] "Hz" Vector__XXX
 SG_ GeneratorPhaseBAcRmsCurrent : 48|16@1+ (1,0) [0|64255] "A" Vector__XXX
 SG_ GnrtrPhsBLnLnARmsVltg : 0|16@1+ (1,0) [0|64255] "V" Vector__XXX
 SG_ GnrtrPhsBLnNtrlARmsVltg : 16|16@1+ (1,0) [0|64255] "V" Vector__XXX

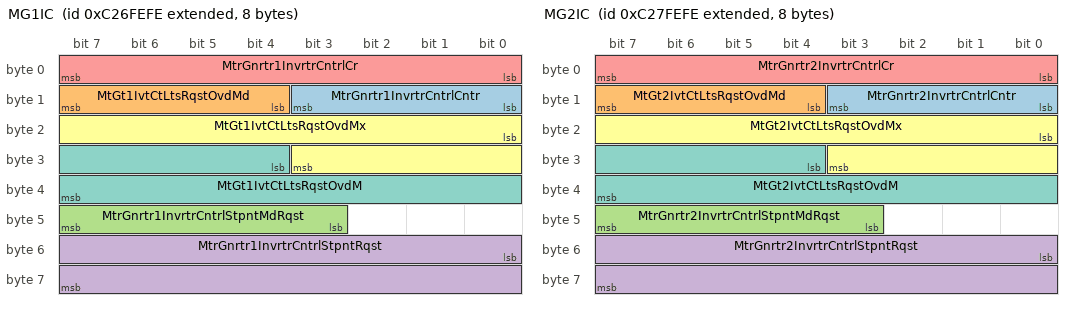
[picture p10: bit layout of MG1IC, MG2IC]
BO_ 2351365886 MG1IC: 8 Vector__XXX
 SG_ MtrGnrtr1InvrtrCntrlCntr : 8|4@1+ (1,0) [0|15] "" Vector__XXX
 SG_ MtGt1IvtCtLtsRqstOvdMd : 12|4@1+ (1,0) [0|15] "" Vector__XXX
 SG_ MtrGnrtr1InvrtrCntrlStpntMdRqst : 43|5@1+ (1,0) [0|31] "" Vector__XXX
 SG_ MtrGnrtr1InvrtrCntrlStpntRqst : 48|16@1+ (0.00390625,-125) [-125|125.99609375] "%" Vector__XXX
 SG_ MtrGnrtr1InvrtrCntrlCr : 0|8@1+ (1,0) [0|250] "count" Vector__XXX
 SG_ MtGt1IvtCtLtsRqstOvdMx : 16|12@1+ (0.0625,-125) [-125|125.9375] "%" Vector__XXX
 SG_ MtGt1IvtCtLtsRqstOvdM : 28|12@1+ (0.0625,-125) [-125|125.9375] "%" Vector__XXX

BO_ 2351431422 MG2IC: 8 Vector__XXX
 SG_ MtrGnrtr2InvrtrCntrlCntr : 8|4@1+ (1,0) [0|15] "" Vector__XXX
 SG_ MtGt2IvtCtLtsRqstOvdMd : 12|4@1+ (1,0) [0|15] "" Vector__XXX
 SG_ MtrGnrtr2InvrtrCntrlStpntMdRqst : 43|5@1+ (1,0) [0|31] "" Vector__XXX
 SG_ MtrGnrtr2InvrtrCntrlStpntRqst : 48|16@1+ (0.00390625,-125) [-125|125.99609375] "%" Vector__XXX
 SG_ MtrGnrtr2InvrtrCntrlCr : 0|8@1+ (1,0) [0|250] "count" Vector__XXX
 SG_ MtGt2IvtCtLtsRqstOvdMx : 16|12@1+ (0.0625,-125) [-125|125.9375] "%" Vector__XXX
 SG_ MtGt2IvtCtLtsRqstOvdM : 28|12@1+ (0.0625,-125) [-125|125.9375] "%" Vector__XXX

BO_ 2556165886 MG2IRP: 8 Vector__XXX
 SG_ MtrGnrtr2InvrtrLmtsRqstPwrCntr : 8|4@1+ (1,0) [0|15] "" Vector__XXX
 SG_ MtrGnrtr2InvrtrLmtsRqstPwrCr : 0|8@1+ (1,0) [0|250] "count" Vector__XXX
 SG_ MtGt2IvtLtsRqstMPwMx : 12|12@1+ (0.0625,-125) [-125|125.9375] "%" Vector__XXX
 SG_ MtGt2IvtLtsRqstMPwM : 24|12@1+ (0.0625,-125) [-125|125.9375] "%" Vector__XXX
 SG_ MtGt2IvtLtsRqstDSdPwMx : 36|12@1+ (0.0625,-125) [-125|125.9375] "%" Vector__XXX
 SG_ MtGt2IvtLtsRqstDSdPwM : 48|12@1+ (0.0625,-125) [-125|125.9375] "%" Vector__XXX

BO_ 2556231422 MG2ILRM: 8 Vector__XXX
 SG_ MtrGnrtr2InvrtrLmtsRqstMhnlCntr : 8|4@1+ (1,0) [0|15] "" Vector__XXX
 SG_ MtrGnrtr2InvrtrLmtsRqstMhnlCr : 0|8@1+ (1,0) [0|250] "count" Vector__XXX
 SG_ MtrGnrtr2InvrtrLmtsRqstTrqMxmm : 12|12@1+ (0.0625,-125) [-125|125.9375] "%" Vector__XXX
 SG_ MtrGnrtr2InvrtrLmtsRqstTrqMnmm : 24|12@1+ (0.0625,-125) [-125|125.9375] "%" Vector__XXX
 SG_ MtrGnrtr2InvrtrLmtsRqstSpdMxmm : 36|12@1+ (0.0625,-125) [-125|125.9375] "%" Vector__XXX
 SG_ MtrGnrtr2InvrtrLmtsRqstSpdMnmm : 48|12@1+ (0.0625,-125) [-125|125.9375] "%" Vector__XXX

BO_ 2556296958 MG2ILRDC: 8 Vector__XXX
 SG_ MtrGnrtr2InvrtrLmtsRqstDSdCr : 0|8@1+ (1,0) [0|250] "count" Vector__XXX
 SG_ MtrGnrtr2InvrtrLmtsRqstDSdCntr : 8|4@1+ (1,0) [0|15] "" Vector__XXX
 SG_ MtGt2IvtLtsRqstDSdVtMx : 12|12@1+ (0.0625,-125) [-125|125.9375] "%" Vector__XXX
 SG_ MtGt2IvtLtsRqstDSdVtM : 24|12@1+ (0.0625,-125) [-125|125.9375] "%" Vector__XXX
 SG_ MtGt2IvtLtsRqstDSdCtMx : 36|12@1+ (0.0625,-125) [-125|125.9375] "%" Vector__XXX
 SG_ MtGt2IvtLtsRqstDSdCtM : 48|12@1+ (0.0625,-125) [-125|125.9375] "%" Vector__XXX

BO_ 2556362494 MG1ILRDC: 8 Vector__XXX
 SG_ MtrGnrtr1InvrtrLmtsRqstDSdCr : 0|8@1+ (1,0) [0|250] "count" Vector__XXX
 SG_ MtrGnrtr1InvrtrLmtsRqstDSdCntr : 8|4@1+ (1,0) [0|15] "" Vector__XXX
 SG_ MtGt1IvtLtsRqstDSdVtMx : 12|12@1+ (0.0625,-125) [-125|125.9375] "%" Vector__XXX
 SG_ MtGt1IvtLtsRqstDSdVtM : 24|12@1+ (0.0625,-125) [-125|125.9375] "%" Vector__XXX
 SG_ MtGt1IvtLtsRqstDSdCtMx : 36|12@1+ (0.0625,-125) [-125|125.9375] "%" Vector__XXX
 SG_ MtGt1IvtLtsRqstDSdCtM : 48|12@1+ (0.0625,-125) [-125|125.9375] "%" Vector__XXX

BO_ 2556428030 MG1ILRM: 8 Vector__XXX
 SG_ MtrGnrtr1InvrtrLmtsRqstMhnlCntr : 8|4@1+ (1,0) [0|15] "" Vector__XXX
 SG_ MtrGnrtr1InvrtrLmtsRqstMhnlCr : 0|8@1+ (1,0) [0|250] "count" Vector__XXX
 SG_ MtrGnrtr1InvrtrLmtsRqstTrqMxmm : 12|12@1+ (0.0625,-125) [-125|125.9375] "%" Vector__XXX
 SG_ MtrGnrtr1InvrtrLmtsRqstTrqMnmm : 24|12@1+ (0.0625,-125) [-125|125.9375] "%" Vector__XXX
 SG_ MtrGnrtr1InvrtrLmtsRqstSpdMxmm : 36|12@1+ (0.0625,-125) [-125|125.9375] "%" Vector__XXX
 SG_ MtrGnrtr1InvrtrLmtsRqstSpdMnmm : 48|12@1+ (0.0625,-125) [-125|125.9375] "%" Vector__XXX

BO_ 2556493566 MG1IRP: 8 Vector__XXX
 SG_ MtrGnrtr1InvrtrLmtsRqstPwrCntr : 8|4@1+ (1,0) [0|15] "" Vector__XXX
 SG_ MtrGnrtr1InvrtrLmtsRqstPwrCr : 0|8@1+ (1,0) [0|250] "count" Vector__XXX
 SG_ MtGt1IvtLtsRqstMPwMx : 12|12@1+ (0.0625,-125) [-125|125.9375] "%" Vector__XXX
 SG_ MtGt1IvtLtsRqstMPwM : 24|12@1+ (0.0625,-125) [-125|125.9375] "%" Vector__XXX
 SG_ MtGt1IvtLtsRqstDSdPwMx : 36|12@1+ (0.0625,-125) [-125|125.9375] "%" Vector__XXX
 SG_ MtGt1IvtLtsRqstDSdPwM : 48|12@1+ (0.0625,-125) [-125|125.9375] "%" Vector__XXX

BO_ 2556559102 PDI: 8 Vector__XXX
 SG_ PrsnnlDttAlrmRvStts : 0|3@1+ (1,0) [0|7] "" Vector__XXX
 SG_ PrsnnlDttSqnCntrEh : 8|8@1+ (1,0) [0|250] "count" Vector__XXX

BO_ 2556624638 ECCCF: 8 Vector__XXX
 SG_ CnfgrdEngnClndrMssFrtnBrndLtn1 : 0|8@1+ (0.4,0) [0|100] "%" Vector__XXX
 SG_ CnfgrdEngnClndrMssFrtnBrndLtn2 : 8|8@1+ (0.4,0) [0|100] "%" Vector__XXX

BO_ 2556690174 ECCC: 8 Vector__XXX
 SG_ EngnClndrMssFrtnBrndLtn1 : 0|8@1+ (0.4,0) [0|100] "%" Vector__XXX
 SG_ EngnClndrMssFrtnBrndLtn2 : 8|8@1+ (0.4,0) [0|100] "%" Vector__XXX

BO_ 2556755710 ECPTF: 8 Vector__XXX
 SG_ CnfgrdEngnClndrPrssrTmng1 : 0|16@1+ (0.0125,-360) [-360|360] "deg" Vector__XXX
 SG_ CnfgrdEngnClndrPrssrTmng2 : 16|16@1+ (0.0125,-360) [-360|360] "deg" Vector__XXX
 SG_ CnfgrdEngnClndrPrssrTmng3 : 32|16@1+ (0.0125,-360) [-360|360] "deg" Vector__XXX
 SG_ CnfgrdEngnClndrPrssrTmng4 : 48|16@1+ (0.0125,-360) [-360|360] "deg" Vector__XXX

BO_ 2556821246 ECPTC: 8 Vector__XXX
 SG_ EngineCylinderPressureTiming1 : 0|16@1+ (0.0125,-360) [-360|360] "deg" Vector__XXX
 SG_ EngineCylinderPressureTiming2 : 16|16@1+ (0.0125,-360) [-360|360] "deg" Vector__XXX
 SG_ EngineCylinderPressureTiming3 : 32|16@1+ (0.0125,-360) [-360|360] "deg" Vector__XXX
 SG_ EngineCylinderPressureTiming4 : 48|16@1+ (0.0125,-360) [-360|360] "deg" Vector__XXX

BO_ 2556886782 EAGCPC: 8 Vector__XXX
 SG_ GnrtrClntPmpEnlCmmnd : 0|2@1+ (1,0) [0|3] "" Vector__XXX
 SG_ GeneratorCoolantPumpPowerHold : 2|2@1+ (1,0) [0|3] "" Vector__XXX
 SG_ GnrtrClntPmpSpdCmmnd : 8|16@1+ (0.5,0) [0|32127.5] "rpm" Vector__XXX
 SG_ GnrtrClntPmpPrntSpdCmmnd : 24|8@1+ (0.5,0) [0|100] "%" Vector__XXX
 SG_ EtdAssGtCtPpCdEdddIttSppt : 50|2@1+ (1,0) [0|3] "" Vector__XXX
 SG_ EltrfdAssrGnrtrClntPmpCmmndCntr : 52|4@1+ (1,0) [0|15] "count" Vector__XXX
 SG_ EltrfdAssrGnrtrClntPmpCmmndCr : 56|8@1+ (1,0) [0|250] "count" Vector__XXX

BO_ 2556952318 EAGCFC: 8 Vector__XXX
 SG_ GnrtrClntFnEnlCmmnd : 0|2@1+ (1,0) [0|3] "" Vector__XXX
 SG_ GeneratorCoolantFanPowerHold : 2|2@1+ (1,0) [0|3] "" Vector__XXX
 SG_ GeneratorCoolantFanSpeedCommand : 8|16@1+ (0.5,0) [0|32127.5] "rpm" Vector__XXX
 SG_ GnrtrClntFnPrntSpdCmmnd : 24|8@1+ (0.5,0) [0|100] "%" Vector__XXX
 SG_ EtdAssGtCtFCdEdddIttSppt : 50|2@1+ (1,0) [0|3] "" Vector__XXX
 SG_ EltrfdAssrGnrtrClntFnCmmndCntr : 52|4@1+ (1,0) [0|15] "count" Vector__XXX
 SG_ EltrfdAssrGnrtrClntFnCmmndCr : 56|8@1+ (1,0) [0|250] "count" Vector__XXX

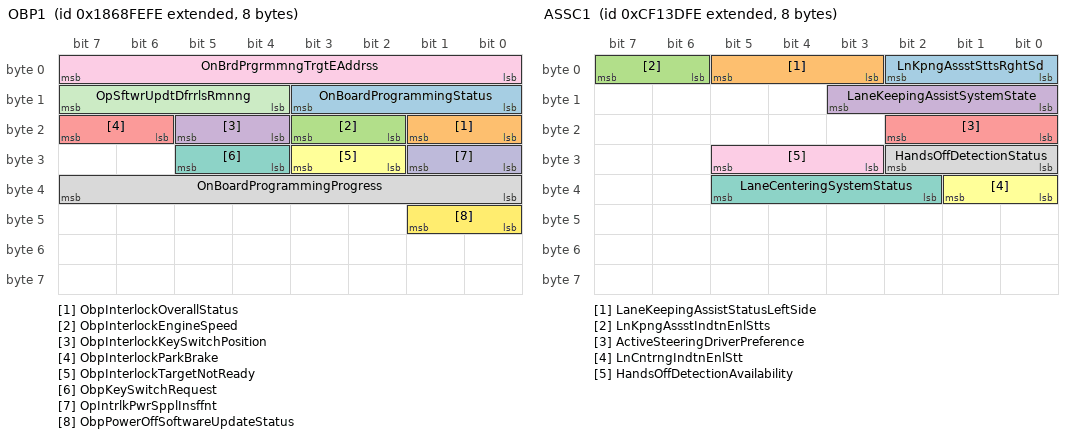
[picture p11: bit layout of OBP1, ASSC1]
BO_ 2557017854 OBP1: 8 Vector__XXX
 SG_ OnBoardProgrammingStatus : 8|4@1+ (1,0) [0|15] "" Vector__XXX
 SG_ ObpInterlockOverallStatus : 16|2@1+ (1,0) [0|3] "" Vector__XXX
 SG_ ObpInterlockEngineSpeed : 18|2@1+ (1,0) [0|3] "" Vector__XXX
 SG_ ObpInterlockKeySwitchPosition : 20|2@1+ (1,0) [0|3] "" Vector__XXX
 SG_ ObpInterlockParkBrake : 22|2@1+ (1,0) [0|3] "" Vector__XXX
 SG_ ObpInterlockTargetNotReady : 26|2@1+ (1,0) [0|3] "" Vector__XXX
 SG_ ObpKeySwitchRequest : 28|2@1+ (1,0) [0|3] "" Vector__XXX
 SG_ OnBoardProgrammingProgress : 32|8@1+ (0.5,0) [0|100] "%" Vector__XXX
 SG_ OnBrdPrgrmmngTrgtEAddrss : 0|8@1+ (1,0) [0|250] "sourceadr" Vector__XXX
 SG_ OpIntrlkPwrSpplInsffnt : 24|2@1+ (1,0) [0|3] "" Vector__XXX
 SG_ OpSftwrUpdtDfrrlsRmnng : 12|4@1+ (1,0) [0|15] "count" Vector__XXX
 SG_ ObpPowerOffSoftwareUpdateStatus : 40|2@1+ (1,0) [0|3] "" Vector__XXX

BO_ 2557083390 MCIC1: 8 Vector__XXX
 SG_ OperatorStationLocationSetting : 0|8@1+ (1,0) [0|250] "ID" Vector__XXX
 SG_ TrollingModeSettingCommand : 8|8@1+ (1,0) [0|250] "" Vector__XXX
 SG_ EngnThrttlSnhrnztnMdCmmnd : 16|4@1+ (1,0) [0|15] "" Vector__XXX
 SG_ EngineTrollingModeSetSpeed : 32|16@1+ (0.125,0) [0|8031.875] "rpm" Vector__XXX

BO_ 2557148926 MCI2: 8 Vector__XXX
 SG_ OprtrSttnInCntrlLtn : 0|8@1+ (1,0) [0|250] "ID" Vector__XXX
 SG_ OperatorStationLockout : 8|2@1+ (1,0) [0|3] "" Vector__XXX
 SG_ EngnThrttlSnhrnztnMdCrrntSttng : 10|4@1+ (1,0) [0|15] "" Vector__XXX
 SG_ TrollingModeExtendedRange : 16|8@1+ (1,0) [0|250] "" Vector__XXX
 SG_ TrollingModeCurrentSetting : 24|8@1+ (1,0) [0|250] "" Vector__XXX
 SG_ VesselEngineSetSpeed : 32|16@1+ (0.125,0) [0|8031.875] "rpm" Vector__XXX
 SG_ VesselSpeedControlMode : 48|8@1+ (1,0) [0|250] "" Vector__XXX

BO_ 2364617726 EPCVDC1: 8 Vector__XXX
 SG_ EngnPrChmrFlVlv1Drtn : 0|16@1+ (2,0) [0|128510] "micro s" Vector__XXX
 SG_ EngnPrChmrFlVlv2Drtn : 16|16@1+ (2,0) [0|128510] "micro s" Vector__XXX
 SG_ EngnPrChmrFlVlv3Drtn : 32|16@1+ (2,0) [0|128510] "micro s" Vector__XXX
 SG_ EngnPrChmrFlVlv4Drtn : 48|16@1+ (2,0) [0|128510] "micro s" Vector__XXX

BO_ 2364617982 EPCVDC2: 8 Vector__XXX
 SG_ EngnPrChmrFlVlv5Drtn : 0|16@1+ (2,0) [0|128510] "micro s" Vector__XXX
 SG_ EngnPrChmrFlVlv6Drtn : 16|16@1+ (2,0) [0|128510] "micro s" Vector__XXX
 SG_ EngnPrChmrFlVlv7Drtn : 32|16@1+ (2,0) [0|128510] "micro s" Vector__XXX
 SG_ EngnPrChmrFlVlv8Drtn : 48|16@1+ (2,0) [0|128510] "micro s" Vector__XXX

BO_ 2364618238 EPCVDC3: 8 Vector__XXX
 SG_ EngnPrChmrFlVlv9Drtn : 0|16@1+ (2,0) [0|128510] "micro s" Vector__XXX
 SG_ EngnPrChmrFlVlv10Drtn : 16|16@1+ (2,0) [0|128510] "micro s" Vector__XXX
 SG_ EngnPrChmrFlVlv11Drtn : 32|16@1+ (2,0) [0|128510] "micro s" Vector__XXX
 SG_ EngnPrChmrFlVlv12Drtn : 48|16@1+ (2,0) [0|128510] "micro s" Vector__XXX

BO_ 2364618494 EPCVDC4: 8 Vector__XXX
 SG_ EngnPrChmrFlVlv13Drtn : 0|16@1+ (2,0) [0|128510] "micro s" Vector__XXX
 SG_ EngnPrChmrFlVlv14Drtn : 16|16@1+ (2,0) [0|128510] "micro s" Vector__XXX
 SG_ EngnPrChmrFlVlv15Drtn : 32|16@1+ (2,0) [0|128510] "micro s" Vector__XXX
 SG_ EngnPrChmrFlVlv16Drtn : 48|16@1+ (2,0) [0|128510] "micro s" Vector__XXX

BO_ 2364618750 EPCVDC5: 8 Vector__XXX
 SG_ EngnPrChmrFlVlv17Drtn : 0|16@1+ (2,0) [0|128510] "micro s" Vector__XXX
 SG_ EngnPrChmrFlVlv18Drtn : 16|16@1+ (2,0) [0|128510] "micro s" Vector__XXX
 SG_ EngnPrChmrFlVlv19Drtn : 32|16@1+ (2,0) [0|128510] "micro s" Vector__XXX
 SG_ EngnPrChmrFlVlv20Drtn : 48|16@1+ (2,0) [0|128510] "micro s" Vector__XXX

BO_ 2364619006 EPCSOAC1: 8 Vector__XXX
 SG_ EngnPrChmrFlVlv1StrtOfAttnCmmnd : 0|16@1+ (0.0078125,-400) [-400|101.9921875] "deg" Vector__XXX
 SG_ EngnPrChmrFlVlv2StrtOfAttnCmmnd : 16|16@1+ (0.0078125,-400) [-400|101.9921875] "deg" Vector__XXX
 SG_ EngnPrChmrFlVlv3StrtOfAttnCmmnd : 32|16@1+ (0.0078125,-400) [-400|101.9921875] "deg" Vector__XXX
 SG_ EngnPrChmrFlVlv4StrtOfAttnCmmnd : 48|16@1+ (0.0078125,-400) [-400|101.9921875] "deg" Vector__XXX

BO_ 2364619262 EPCSOAC2: 8 Vector__XXX
 SG_ EngnPrChmrFlVlv5StrtOfAttnCmmnd : 0|16@1+ (0.0078125,-400) [-400|101.9921875] "deg" Vector__XXX
 SG_ EngnPrChmrFlVlv6StrtOfAttnCmmnd : 16|16@1+ (0.0078125,-400) [-400|101.9921875] "deg" Vector__XXX
 SG_ EngnPrChmrFlVlv7StrtOfAttnCmmnd : 32|16@1+ (0.0078125,-400) [-400|101.9921875] "deg" Vector__XXX
 SG_ EngnPrChmrFlVlv8StrtOfAttnCmmnd : 48|16@1+ (0.0078125,-400) [-400|101.9921875] "deg" Vector__XXX

BO_ 2364619518 EPCSOAC3: 8 Vector__XXX
 SG_ EngnPrChmrFlVlv9StrtOfAttnCmmnd : 0|16@1+ (0.0078125,-400) [-400|101.9921875] "deg" Vector__XXX
 SG_ EPCFVv10SttOAttCd : 16|16@1+ (0.0078125,-400) [-400|101.9921875] "deg" Vector__XXX
 SG_ EPCFVv11SttOAttCd : 32|16@1+ (0.0078125,-400) [-400|101.9921875] "deg" Vector__XXX
 SG_ EPCFVv12SttOAttCd : 48|16@1+ (0.0078125,-400) [-400|101.9921875] "deg" Vector__XXX

BO_ 2364619774 EPCSOAC4: 8 Vector__XXX
 SG_ EPCFVv13SttOAttCd : 0|16@1+ (0.0078125,-400) [-400|101.9921875] "deg" Vector__XXX
 SG_ EPCFVv14SttOAttCd : 16|16@1+ (0.0078125,-400) [-400|101.9921875] "deg" Vector__XXX
 SG_ EPCFVv15SttOAttCd : 32|16@1+ (0.0078125,-400) [-400|101.9921875] "deg" Vector__XXX
 SG_ EPCFVv16SttOAttCd : 48|16@1+ (0.0078125,-400) [-400|101.9921875] "deg" Vector__XXX

BO_ 2364620030 EPCSOAC5: 8 Vector__XXX
 SG_ EPCFVv17SttOAttCd : 0|16@1+ (0.0078125,-400) [-400|101.9921875] "deg" Vector__XXX
 SG_ EPCFVv18SttOAttCd : 16|16@1+ (0.0078125,-400) [-400|101.9921875] "deg" Vector__XXX
 SG_ EPCFVv19SttOAttCd : 32|16@1+ (0.0078125,-400) [-400|101.9921875] "deg" Vector__XXX
 SG_ EPCFVv20SttOAttCd : 48|16@1+ (0.0078125,-400) [-400|101.9921875] "deg" Vector__XXX

BO_ 2364620286 ASSC1: 8 Vector__XXX
 SG_ LnKpngAssstSttsRghtSd : 0|3@1+ (1,0) [0|7] "" Vector__XXX
 SG_ LaneKeepingAssistStatusLeftSide : 3|3@1+ (1,0) [0|7] "" Vector__XXX
 SG_ LnKpngAssstIndtnEnlStts : 6|2@1+ (1,0) [0|3] "" Vector__XXX
 SG_ LaneKeepingAssistSystemState : 8|4@1+ (1,0) [0|15] "" Vector__XXX
 SG_ ActiveSteeringDriverPreference : 16|3@1+ (1,0) [0|7] "" Vector__XXX
 SG_ LnCntrngIndtnEnlStt : 32|2@1+ (1,0) [0|3] "" Vector__XXX
 SG_ LaneCenteringSystemStatus : 34|4@1+ (1,0) [0|15] "" Vector__XXX
 SG_ HandsOffDetectionStatus : 24|3@1+ (1,0) [0|7] "" Vector__XXX
 SG_ HandsOffDetectionAvailability : 27|3@1+ (1,0) [0|7] "" Vector__XXX

BO_ 2364621054 SIAAC: 8 Vector__XXX
 SG_ SttnrInvrtrAvrgARmsVltg : 0|16@1+ (1,0) [0|64255] "V" Vector__XXX
 SG_ SttnrInvrtrAvrgLnNtrlARmsVltg : 16|16@1+ (1,0) [0|64255] "V" Vector__XXX
 SG_ SttnrInvrtrAvrgAFrqn : 32|16@1+ (0.0078125,0) [0|501.9921875] "Hz" Vector__XXX
 SG_ SttnrInvrtrAvrgARmsCrrnt : 48|16@1+ (1,0) [0|64255] "A" Vector__XXX

BO_ 2364621310 SITACR: 8 Vector__XXX
 SG_ SttnrInvrtrTtlRtvPwr : 0|32@1+ (1,-2000000000) [-2000000000|2211081215] "VAr" Vector__XXX
 SG_ SttnrInvrtrOvrllPwrFtr : 32|16@1+ (0.00006103515625,-1) [-1|2.92181396484375] "" Vector__XXX
 SG_ SttnrInvrtrOvrllPwrFtrLggng : 48|2@1+ (1,0) [0|3] "" Vector__XXX

BO_ 2364621566 SITACP: 8 Vector__XXX
 SG_ SttnrInvrtrTtlRlPwr : 0|32@1+ (1,-2000000000) [-2000000000|2211081215] "W" Vector__XXX
 SG_ SttnrInvrtrTtlApprntPwr : 32|32@1+ (1,-2000000000) [-2000000000|2211081215] "VA" Vector__XXX

BO_ 2364621822 SIC: 8 Vector__XXX
 SG_ SttnrInvrtrNtRdTAtmtllPrlllStt : 0|2@1+ (1,0) [0|3] "" Vector__XXX
 SG_ SttnrInvrtrAxlrShtdwnSwth : 2|2@1+ (1,0) [0|3] "" Vector__XXX

BO_ 2364622078 SIBSC: 8 Vector__XXX
 SG_ StationaryInverterToBusDeadBus : 0|2@1+ (1,0) [0|3] "" Vector__XXX
 SG_ SttnrInvrtrTBsPhsMth : 2|2@1+ (1,0) [0|3] "" Vector__XXX
 SG_ SttnrInvrtrTBsFrqnMth : 4|2@1+ (1,0) [0|3] "" Vector__XXX
 SG_ SttnrInvrtrTBsVltgMth : 6|2@1+ (1,0) [0|3] "" Vector__XXX
 SG_ StationaryInverterToBusInSync : 8|2@1+ (1,0) [0|3] "" Vector__XXX
 SG_ SttnrInvrtrTBsAPhsDffrn : 16|16@1+ (0.0078125,-200) [-200|301.9921875] "deg" Vector__XXX

BO_ 2364622334 ECCP1: 8 Vector__XXX
 SG_ EngineCylinder1Timing1Pressure : 0|16@1+ (0.0009765625,0) [0|62.7490234375] "MPa" Vector__XXX
 SG_ EngineCylinder1Timing2Pressure : 16|16@1+ (0.0009765625,0) [0|62.7490234375] "MPa" Vector__XXX
 SG_ EngineCylinder1Timing3Pressure : 32|16@1+ (0.0009765625,0) [0|62.7490234375] "MPa" Vector__XXX
 SG_ EngineCylinder1Timing4Pressure : 48|16@1+ (0.0009765625,0) [0|62.7490234375] "MPa" Vector__XXX

BO_ 2364622590 ECCP2: 8 Vector__XXX
 SG_ EngineCylinder2Timing1Pressure : 0|16@1+ (0.0009765625,0) [0|62.7490234375] "MPa" Vector__XXX
 SG_ EngineCylinder2Timing2Pressure : 16|16@1+ (0.0009765625,0) [0|62.7490234375] "MPa" Vector__XXX
 SG_ EngineCylinder2Timing3Pressure : 32|16@1+ (0.0009765625,0) [0|62.7490234375] "MPa" Vector__XXX
 SG_ EngineCylinder2Timing4Pressure : 48|16@1+ (0.0009765625,0) [0|62.7490234375] "MPa" Vector__XXX

BO_ 2364622846 ECCP3: 8 Vector__XXX
 SG_ EngineCylinder3Timing1Pressure : 0|16@1+ (0.0009765625,0) [0|62.7490234375] "MPa" Vector__XXX
 SG_ EngineCylinder3Timing2Pressure : 16|16@1+ (0.0009765625,0) [0|62.7490234375] "MPa" Vector__XXX
 SG_ EngineCylinder3Timing3Pressure : 32|16@1+ (0.0009765625,0) [0|62.7490234375] "MPa" Vector__XXX
 SG_ EngineCylinder3Timing4Pressure : 48|16@1+ (0.0009765625,0) [0|62.7490234375] "MPa" Vector__XXX

BO_ 2364623102 ECCP4: 8 Vector__XXX
 SG_ EngineCylinder4Timing1Pressure : 0|16@1+ (0.0009765625,0) [0|62.7490234375] "MPa" Vector__XXX
 SG_ EngineCylinder4Timing2Pressure : 16|16@1+ (0.0009765625,0) [0|62.7490234375] "MPa" Vector__XXX
 SG_ EngineCylinder4Timing3Pressure : 32|16@1+ (0.0009765625,0) [0|62.7490234375] "MPa" Vector__XXX
 SG_ EngineCylinder4Timing4Pressure : 48|16@1+ (0.0009765625,0) [0|62.7490234375] "MPa" Vector__XXX

BO_ 2364623358 ECCP5: 8 Vector__XXX
 SG_ EngineCylinder5Timing1Pressure : 0|16@1+ (0.0009765625,0) [0|62.7490234375] "MPa" Vector__XXX
 SG_ EngineCylinder5Timing2Pressure : 16|16@1+ (0.0009765625,0) [0|62.7490234375] "MPa" Vector__XXX
 SG_ EngineCylinder5Timing3Pressure : 32|16@1+ (0.0009765625,0) [0|62.7490234375] "MPa" Vector__XXX
 SG_ EngineCylinder5Timing4Pressure : 48|16@1+ (0.0009765625,0) [0|62.7490234375] "MPa" Vector__XXX

BO_ 2364623614 ECCP6: 8 Vector__XXX
 SG_ EngineCylinder6Timing1Pressure : 0|16@1+ (0.0009765625,0) [0|62.7490234375] "MPa" Vector__XXX
 SG_ EngineCylinder6Timing2Pressure : 16|16@1+ (0.0009765625,0) [0|62.7490234375] "MPa" Vector__XXX
 SG_ EngineCylinder6Timing3Pressure : 32|16@1+ (0.0009765625,0) [0|62.7490234375] "MPa" Vector__XXX
 SG_ EngineCylinder6Timing4Pressure : 48|16@1+ (0.0009765625,0) [0|62.7490234375] "MPa" Vector__XXX

BO_ 2364623870 ECCP7: 8 Vector__XXX
 SG_ EngineCylinder7Timing1Pressure : 0|16@1+ (0.0009765625,0) [0|62.7490234375] "MPa" Vector__XXX
 SG_ EngineCylinder7Timing2Pressure : 16|16@1+ (0.0009765625,0) [0|62.7490234375] "MPa" Vector__XXX
 SG_ EngineCylinder7Timing3Pressure : 32|16@1+ (0.0009765625,0) [0|62.7490234375] "MPa" Vector__XXX
 SG_ EngineCylinder7Timing4Pressure : 48|16@1+ (0.0009765625,0) [0|62.7490234375] "MPa" Vector__XXX

BO_ 2364624126 ECCP8: 8 Vector__XXX
 SG_ EngineCylinder8Timing1Pressure : 0|16@1+ (0.0009765625,0) [0|62.7490234375] "MPa" Vector__XXX
 SG_ EngineCylinder8Timing2Pressure : 16|16@1+ (0.0009765625,0) [0|62.7490234375] "MPa" Vector__XXX
 SG_ EngineCylinder8Timing3Pressure : 32|16@1+ (0.0009765625,0) [0|62.7490234375] "MPa" Vector__XXX
 SG_ EngineCylinder8Timing4Pressure : 48|16@1+ (0.0009765625,0) [0|62.7490234375] "MPa" Vector__XXX

BO_ 2364624382 ECCP9: 8 Vector__XXX
 SG_ EngineCylinder9Timing1Pressure : 0|16@1+ (0.0009765625,0) [0|62.7490234375] "MPa" Vector__XXX
 SG_ EngineCylinder9Timing2Pressure : 16|16@1+ (0.0009765625,0) [0|62.7490234375] "MPa" Vector__XXX
 SG_ EngineCylinder9Timing3Pressure : 32|16@1+ (0.0009765625,0) [0|62.7490234375] "MPa" Vector__XXX
 SG_ EngineCylinder9Timing4Pressure : 48|16@1+ (0.0009765625,0) [0|62.7490234375] "MPa" Vector__XXX

BO_ 2364624638 ECCP10: 8 Vector__XXX
 SG_ EngineCylinder10Timing1Pressure : 0|16@1+ (0.0009765625,0) [0|62.7490234375] "MPa" Vector__XXX
 SG_ EngineCylinder10Timing2Pressure : 16|16@1+ (0.0009765625,0) [0|62.7490234375] "MPa" Vector__XXX
 SG_ EngineCylinder10Timing3Pressure : 32|16@1+ (0.0009765625,0) [0|62.7490234375] "MPa" Vector__XXX
 SG_ EngineCylinder10Timing4Pressure : 48|16@1+ (0.0009765625,0) [0|62.7490234375] "MPa" Vector__XXX

BO_ 2364624894 ECCP11: 8 Vector__XXX
 SG_ EngineCylinder11Timing1Pressure : 0|16@1+ (0.0009765625,0) [0|62.7490234375] "MPa" Vector__XXX
 SG_ EngineCylinder11Timing2Pressure : 16|16@1+ (0.0009765625,0) [0|62.7490234375] "MPa" Vector__XXX
 SG_ EngineCylinder11Timing3Pressure : 32|16@1+ (0.0009765625,0) [0|62.7490234375] "MPa" Vector__XXX
 SG_ EngineCylinder11Timing4Pressure : 48|16@1+ (0.0009765625,0) [0|62.7490234375] "MPa" Vector__XXX

BO_ 2364625150 ECCP12: 8 Vector__XXX
 SG_ EngineCylinder12Timing1Pressure : 0|16@1+ (0.0009765625,0) [0|62.7490234375] "MPa" Vector__XXX
 SG_ EngineCylinder12Timing2Pressure : 16|16@1+ (0.0009765625,0) [0|62.7490234375] "MPa" Vector__XXX
 SG_ EngineCylinder12Timing3Pressure : 32|16@1+ (0.0009765625,0) [0|62.7490234375] "MPa" Vector__XXX
 SG_ EngineCylinder12Timing4Pressure : 48|16@1+ (0.0009765625,0) [0|62.7490234375] "MPa" Vector__XXX

BO_ 2364625406 ECCP13: 8 Vector__XXX
 SG_ EngineCylinder13Timing1Pressure : 0|16@1+ (0.0009765625,0) [0|62.7490234375] "MPa" Vector__XXX
 SG_ EngineCylinder13Timing2Pressure : 16|16@1+ (0.0009765625,0) [0|62.7490234375] "MPa" Vector__XXX
 SG_ EngineCylinder13Timing3Pressure : 32|16@1+ (0.0009765625,0) [0|62.7490234375] "MPa" Vector__XXX
 SG_ EngineCylinder13Timing4Pressure : 48|16@1+ (0.0009765625,0) [0|62.7490234375] "MPa" Vector__XXX

BO_ 2364625662 ECCP14: 8 Vector__XXX
 SG_ EngineCylinder14Timing1Pressure : 0|16@1+ (0.0009765625,0) [0|62.7490234375] "MPa" Vector__XXX
 SG_ EngineCylinder14Timing2Pressure : 16|16@1+ (0.0009765625,0) [0|62.7490234375] "MPa" Vector__XXX
 SG_ EngineCylinder14Timing3Pressure : 32|16@1+ (0.0009765625,0) [0|62.7490234375] "MPa" Vector__XXX
 SG_ EngineCylinder14Timing4Pressure : 48|16@1+ (0.0009765625,0) [0|62.7490234375] "MPa" Vector__XXX

BO_ 2364625918 ECCP15: 8 Vector__XXX
 SG_ EngineCylinder15Timing1Pressure : 0|16@1+ (0.0009765625,0) [0|62.7490234375] "MPa" Vector__XXX
 SG_ EngineCylinder15Timing2Pressure : 16|16@1+ (0.0009765625,0) [0|62.7490234375] "MPa" Vector__XXX
 SG_ EngineCylinder15Timing3Pressure : 32|16@1+ (0.0009765625,0) [0|62.7490234375] "MPa" Vector__XXX
 SG_ EngineCylinder15Timing4Pressure : 48|16@1+ (0.0009765625,0) [0|62.7490234375] "MPa" Vector__XXX

BO_ 2364626174 ECCP16: 8 Vector__XXX
 SG_ EngineCylinder16Timing1Pressure : 0|16@1+ (0.0009765625,0) [0|62.7490234375] "MPa" Vector__XXX
 SG_ EngineCylinder16Timing2Pressure : 16|16@1+ (0.0009765625,0) [0|62.7490234375] "MPa" Vector__XXX
 SG_ EngineCylinder16Timing3Pressure : 32|16@1+ (0.0009765625,0) [0|62.7490234375] "MPa" Vector__XXX
 SG_ EngineCylinder16Timing4Pressure : 48|16@1+ (0.0009765625,0) [0|62.7490234375] "MPa" Vector__XXX

BO_ 2364626430 ECCP17: 8 Vector__XXX
 SG_ EngineCylinder17Timing1Pressure : 0|16@1+ (0.0009765625,0) [0|62.7490234375] "MPa" Vector__XXX
 SG_ EngineCylinder17Timing2Pressure : 16|16@1+ (0.0009765625,0) [0|62.7490234375] "MPa" Vector__XXX
 SG_ EngineCylinder17Timing3Pressure : 32|16@1+ (0.0009765625,0) [0|62.7490234375] "MPa" Vector__XXX
 SG_ EngineCylinder17Timing4Pressure : 48|16@1+ (0.0009765625,0) [0|62.7490234375] "MPa" Vector__XXX

BO_ 2364626686 ECCP18: 8 Vector__XXX
 SG_ EngineCylinder18Timing1Pressure : 0|16@1+ (0.0009765625,0) [0|62.7490234375] "MPa" Vector__XXX
 SG_ EngineCylinder18Timing2Pressure : 16|16@1+ (0.0009765625,0) [0|62.7490234375] "MPa" Vector__XXX
 SG_ EngineCylinder18Timing3Pressure : 32|16@1+ (0.0009765625,0) [0|62.7490234375] "MPa" Vector__XXX
 SG_ EngineCylinder18Timing4Pressure : 48|16@1+ (0.0009765625,0) [0|62.7490234375] "MPa" Vector__XXX

BO_ 2364626942 ECCP19: 8 Vector__XXX
 SG_ EngineCylinder19Timing1Pressure : 0|16@1+ (0.0009765625,0) [0|62.7490234375] "MPa" Vector__XXX
 SG_ EngineCylinder19Timing2Pressure : 16|16@1+ (0.0009765625,0) [0|62.7490234375] "MPa" Vector__XXX
 SG_ EngineCylinder19Timing3Pressure : 32|16@1+ (0.0009765625,0) [0|62.7490234375] "MPa" Vector__XXX
 SG_ EngineCylinder19Timing4Pressure : 48|16@1+ (0.0009765625,0) [0|62.7490234375] "MPa" Vector__XXX

BO_ 2364627198 ECCP20: 8 Vector__XXX
 SG_ EngineCylinder20Timing1Pressure : 0|16@1+ (0.0009765625,0) [0|62.7490234375] "MPa" Vector__XXX
 SG_ EngineCylinder20Timing2Pressure : 16|16@1+ (0.0009765625,0) [0|62.7490234375] "MPa" Vector__XXX
 SG_ EngineCylinder20Timing3Pressure : 32|16@1+ (0.0009765625,0) [0|62.7490234375] "MPa" Vector__XXX
 SG_ EngineCylinder20Timing4Pressure : 48|16@1+ (0.0009765625,0) [0|62.7490234375] "MPa" Vector__XXX

BO_ 2364627454 ECCT1: 8 Vector__XXX
 SG_ EngnClndr1InstntnsCmstnTmngPnt1 : 32|16@1+ (0.00390625,-125) [-125|125.99609375] "deg" Vector__XXX
 SG_ EngnClndr1InstntnsCmstnTmngPnt2 : 48|16@1+ (0.00390625,-125) [-125|125.99609375] "deg" Vector__XXX
 SG_ ECd1IsttsSttOCstT : 0|16@1+ (0.00390625,-125) [-125|125.99609375] "deg" Vector__XXX
 SG_ ECd1IsttsCtOCstT : 16|16@1+ (0.00390625,-125) [-125|125.99609375] "deg" Vector__XXX

BO_ 2364627710 ECCT2: 8 Vector__XXX
 SG_ EngnClndr2InstntnsCmstnTmngPnt1 : 32|16@1+ (0.00390625,-125) [-125|125.99609375] "deg" Vector__XXX
 SG_ EngnClndr2InstntnsCmstnTmngPnt2 : 48|16@1+ (0.00390625,-125) [-125|125.99609375] "deg" Vector__XXX
 SG_ ECd2IsttsSttOCstT : 0|16@1+ (0.00390625,-125) [-125|125.99609375] "deg" Vector__XXX
 SG_ ECd2IsttsCtOCstT : 16|16@1+ (0.00390625,-125) [-125|125.99609375] "deg" Vector__XXX

BO_ 2364627966 ECCT3: 8 Vector__XXX
 SG_ EngnClndr3InstntnsCmstnTmngPnt1 : 32|16@1+ (0.00390625,-125) [-125|125.99609375] "deg" Vector__XXX
 SG_ EngnClndr3InstntnsCmstnTmngPnt2 : 48|16@1+ (0.00390625,-125) [-125|125.99609375] "deg" Vector__XXX
 SG_ ECd3IsttsSttOCstT : 0|16@1+ (0.00390625,-125) [-125|125.99609375] "deg" Vector__XXX
 SG_ ECd3IsttsCtOCstT : 16|16@1+ (0.00390625,-125) [-125|125.99609375] "deg" Vector__XXX

BO_ 2364628222 ECCT4: 8 Vector__XXX
 SG_ EngnClndr4InstntnsCmstnTmngPnt1 : 32|16@1+ (0.00390625,-125) [-125|125.99609375] "deg" Vector__XXX
 SG_ EngnClndr4InstntnsCmstnTmngPnt2 : 48|16@1+ (0.00390625,-125) [-125|125.99609375] "deg" Vector__XXX
 SG_ ECd4IsttsSttOCstT : 0|16@1+ (0.00390625,-125) [-125|125.99609375] "deg" Vector__XXX
 SG_ ECd4IsttsCtOCstT : 16|16@1+ (0.00390625,-125) [-125|125.99609375] "deg" Vector__XXX

BO_ 2364628478 ECCT5: 8 Vector__XXX
 SG_ EngnClndr5InstntnsCmstnTmngPnt1 : 32|16@1+ (0.00390625,-125) [-125|125.99609375] "deg" Vector__XXX
 SG_ EngnClndr5InstntnsCmstnTmngPnt2 : 48|16@1+ (0.00390625,-125) [-125|125.99609375] "deg" Vector__XXX
 SG_ ECd5IsttsSttOCstT : 0|16@1+ (0.00390625,-125) [-125|125.99609375] "deg" Vector__XXX
 SG_ ECd5IsttsCtOCstT : 16|16@1+ (0.00390625,-125) [-125|125.99609375] "deg" Vector__XXX

BO_ 2364628734 ECCT6: 8 Vector__XXX
 SG_ EngnClndr6InstntnsCmstnTmngPnt1 : 32|16@1+ (0.00390625,-125) [-125|125.99609375] "deg" Vector__XXX
 SG_ EngnClndr6InstntnsCmstnTmngPnt2 : 48|16@1+ (0.00390625,-125) [-125|125.99609375] "deg" Vector__XXX
 SG_ ECd6IsttsSttOCstT : 0|16@1+ (0.00390625,-125) [-125|125.99609375] "deg" Vector__XXX
 SG_ ECd6IsttsCtOCstT : 16|16@1+ (0.00390625,-125) [-125|125.99609375] "deg" Vector__XXX

BO_ 2364628990 ECCT7: 8 Vector__XXX
 SG_ EngnClndr7InstntnsCmstnTmngPnt1 : 32|16@1+ (0.00390625,-125) [-125|125.99609375] "deg" Vector__XXX
 SG_ EngnClndr7InstntnsCmstnTmngPnt2 : 48|16@1+ (0.00390625,-125) [-125|125.99609375] "deg" Vector__XXX
 SG_ ECd7IsttsSttOCstT : 0|16@1+ (0.00390625,-125) [-125|125.99609375] "deg" Vector__XXX
 SG_ ECd7IsttsCtOCstT : 16|16@1+ (0.00390625,-125) [-125|125.99609375] "deg" Vector__XXX

BO_ 2364629246 ECCT8: 8 Vector__XXX
 SG_ EngnClndr8InstntnsCmstnTmngPnt1 : 32|16@1+ (0.00390625,-125) [-125|125.99609375] "deg" Vector__XXX
 SG_ EngnClndr8InstntnsCmstnTmngPnt2 : 48|16@1+ (0.00390625,-125) [-125|125.99609375] "deg" Vector__XXX
 SG_ ECd8IsttsSttOCstT : 0|16@1+ (0.00390625,-125) [-125|125.99609375] "deg" Vector__XXX
 SG_ ECd8IsttsCtOCstT : 16|16@1+ (0.00390625,-125) [-125|125.99609375] "deg" Vector__XXX

BO_ 2364629502 ECCT9: 8 Vector__XXX
 SG_ EngnClndr9InstntnsCmstnTmngPnt1 : 32|16@1+ (0.00390625,-125) [-125|125.99609375] "deg" Vector__XXX
 SG_ EngnClndr9InstntnsCmstnTmngPnt2 : 48|16@1+ (0.00390625,-125) [-125|125.99609375] "deg" Vector__XXX
 SG_ ECd9IsttsSttOCstT : 0|16@1+ (0.00390625,-125) [-125|125.99609375] "deg" Vector__XXX
 SG_ ECd9IsttsCtOCstT : 16|16@1+ (0.00390625,-125) [-125|125.99609375] "deg" Vector__XXX

BO_ 2364629758 ECCT10: 8 Vector__XXX
 SG_ ECd10IsttsCstTPt1 : 32|16@1+ (0.00390625,-125) [-125|125.99609375] "deg" Vector__XXX
 SG_ ECd10IsttsCstTPt2 : 48|16@1+ (0.00390625,-125) [-125|125.99609375] "deg" Vector__XXX
 SG_ ECd10IsttsSttOCstT : 0|16@1+ (0.00390625,-125) [-125|125.99609375] "deg" Vector__XXX
 SG_ ECd10IsttsCtOCstT : 16|16@1+ (0.00390625,-125) [-125|125.99609375] "deg" Vector__XXX

BO_ 2364630014 ECCT11: 8 Vector__XXX
 SG_ ECd11IsttsCstTPt1 : 32|16@1+ (0.00390625,-125) [-125|125.99609375] "deg" Vector__XXX
 SG_ ECd11IsttsCstTPt2 : 48|16@1+ (0.00390625,-125) [-125|125.99609375] "deg" Vector__XXX
 SG_ ECd11IsttsSttOCstT : 0|16@1+ (0.00390625,-125) [-125|125.99609375] "deg" Vector__XXX
 SG_ ECd11IsttsCtOCstT : 16|16@1+ (0.00390625,-125) [-125|125.99609375] "deg" Vector__XXX

BO_ 2364630270 ECCT12: 8 Vector__XXX
 SG_ ECd12IsttsCstTPt1 : 32|16@1+ (0.00390625,-125) [-125|125.99609375] "deg" Vector__XXX
 SG_ ECd12IsttsCstTPt2 : 48|16@1+ (0.00390625,-125) [-125|125.99609375] "deg" Vector__XXX
 SG_ ECd12IsttsSttOCstT : 0|16@1+ (0.00390625,-125) [-125|125.99609375] "deg" Vector__XXX
 SG_ ECd12IsttsCtOCstT : 16|16@1+ (0.00390625,-125) [-125|125.99609375] "deg" Vector__XXX

BO_ 2364630526 ECCT13: 8 Vector__XXX
 SG_ ECd13IsttsCstTPt1 : 32|16@1+ (0.00390625,-125) [-125|125.99609375] "deg" Vector__XXX
 SG_ ECd13IsttsCstTPt2 : 48|16@1+ (0.00390625,-125) [-125|125.99609375] "deg" Vector__XXX
 SG_ ECd13IsttsSttOCstT : 0|16@1+ (0.00390625,-125) [-125|125.99609375] "deg" Vector__XXX
 SG_ ECd13IsttsCtOCstT : 16|16@1+ (0.00390625,-125) [-125|125.99609375] "deg" Vector__XXX

BO_ 2364630782 ECCT14: 8 Vector__XXX
 SG_ ECd14IsttsCstTPt1 : 32|16@1+ (0.00390625,-125) [-125|125.99609375] "deg" Vector__XXX
 SG_ ECd14IsttsCstTPt2 : 48|16@1+ (0.00390625,-125) [-125|125.99609375] "deg" Vector__XXX
 SG_ ECd14IsttsSttOCstT : 0|16@1+ (0.00390625,-125) [-125|125.99609375] "deg" Vector__XXX
 SG_ ECd14IsttsCtOCstT : 16|16@1+ (0.00390625,-125) [-125|125.99609375] "deg" Vector__XXX

BO_ 2364631038 ECCT15: 8 Vector__XXX
 SG_ ECd15IsttsCstTPt1 : 32|16@1+ (0.00390625,-125) [-125|125.99609375] "deg" Vector__XXX
 SG_ ECd15IsttsCstTPt2 : 48|16@1+ (0.00390625,-125) [-125|125.99609375] "deg" Vector__XXX
 SG_ ECd15IsttsSttOCstT : 0|16@1+ (0.00390625,-125) [-125|125.99609375] "deg" Vector__XXX
 SG_ ECd15IsttsCtOCstT : 16|16@1+ (0.00390625,-125) [-125|125.99609375] "deg" Vector__XXX

BO_ 2364631294 ECCT16: 8 Vector__XXX
 SG_ ECd16IsttsCstTPt1 : 32|16@1+ (0.00390625,-125) [-125|125.99609375] "deg" Vector__XXX
 SG_ ECd16IsttsCstTPt2 : 48|16@1+ (0.00390625,-125) [-125|125.99609375] "deg" Vector__XXX
 SG_ ECd16IsttsSttOCstT : 0|16@1+ (0.00390625,-125) [-125|125.99609375] "deg" Vector__XXX
 SG_ ECd16IsttsCtOCstT : 16|16@1+ (0.00390625,-125) [-125|125.99609375] "deg" Vector__XXX

BO_ 2364631550 ECCT17: 8 Vector__XXX
 SG_ ECd17IsttsCstTPt1 : 32|16@1+ (0.00390625,-125) [-125|125.99609375] "deg" Vector__XXX
 SG_ ECd17IsttsCstTPt2 : 48|16@1+ (0.00390625,-125) [-125|125.99609375] "deg" Vector__XXX
 SG_ ECd17IsttsSttOCstT : 0|16@1+ (0.00390625,-125) [-125|125.99609375] "deg" Vector__XXX
 SG_ ECd17IsttsCtOCstT : 16|16@1+ (0.00390625,-125) [-125|125.99609375] "deg" Vector__XXX

BO_ 2364631806 ECCT18: 8 Vector__XXX
 SG_ ECd18IsttsCstTPt1 : 32|16@1+ (0.00390625,-125) [-125|125.99609375] "deg" Vector__XXX
 SG_ ECd18IsttsCstTPt2 : 48|16@1+ (0.00390625,-125) [-125|125.99609375] "deg" Vector__XXX
 SG_ ECd18IsttsSttOCstT : 0|16@1+ (0.00390625,-125) [-125|125.99609375] "deg" Vector__XXX
 SG_ ECd18IsttsCtOCstT : 16|16@1+ (0.00390625,-125) [-125|125.99609375] "deg" Vector__XXX

BO_ 2364632062 ECCT19: 8 Vector__XXX
 SG_ ECd19IsttsCstTPt1 : 32|16@1+ (0.00390625,-125) [-125|125.99609375] "deg" Vector__XXX
 SG_ ECd19IsttsCstTPt2 : 48|16@1+ (0.00390625,-125) [-125|125.99609375] "deg" Vector__XXX
 SG_ ECd19IsttsSttOCstT : 0|16@1+ (0.00390625,-125) [-125|125.99609375] "deg" Vector__XXX
 SG_ ECd19IsttsCtOCstT : 16|16@1+ (0.00390625,-125) [-125|125.99609375] "deg" Vector__XXX

BO_ 2364632318 ECCT20: 8 Vector__XXX
 SG_ ECd20IsttsCstTPt1 : 32|16@1+ (0.00390625,-125) [-125|125.99609375] "deg" Vector__XXX
 SG_ ECd20IsttsCstTPt2 : 48|16@1+ (0.00390625,-125) [-125|125.99609375] "deg" Vector__XXX
 SG_ ECd20IsttsSttOCstT : 0|16@1+ (0.00390625,-125) [-125|125.99609375] "deg" Vector__XXX
 SG_ ECd20IsttsCtOCstT : 16|16@1+ (0.00390625,-125) [-125|125.99609375] "deg" Vector__XXX

BO_ 2364632574 EECM1: 8 Vector__XXX
 SG_ ECd1IsttsPCstPssT : 0|16@1+ (0.00390625,-125) [-125|125.99609375] "deg" Vector__XXX
 SG_ ECd1IsttsIdtdMEtvPss : 16|16@1+ (0.0001220703125,-1) [-1|6.8436279296875] "MPa" Vector__XXX
 SG_ EngineCylinder1MisfireRate : 40|8@1+ (0.4,0) [0|100] "%" Vector__XXX
 SG_ EngineCylinder1Temperature : 48|16@1+ (0.03125,-273) [-273|1734.96875] "degC" Vector__XXX
 SG_ ECd1IdtdMEtvPssCtOV : 32|8@1+ (0.04,0) [0|10] "%" Vector__XXX

BO_ 2364632830 EECM2: 8 Vector__XXX
 SG_ ECd2IsttsPCstPssT : 0|16@1+ (0.00390625,-125) [-125|125.99609375] "deg" Vector__XXX
 SG_ ECd2IsttsIdtdMEtvPss : 16|16@1+ (0.0001220703125,-1) [-1|6.8436279296875] "MPa" Vector__XXX
 SG_ EngineCylinder2MisfireRate : 40|8@1+ (0.4,0) [0|100] "%" Vector__XXX
 SG_ EngineCylinder2Temperature : 48|16@1+ (0.03125,-273) [-273|1734.96875] "degC" Vector__XXX
 SG_ ECd2IdtdMEtvPssCtOV : 32|8@1+ (0.04,0) [0|10] "%" Vector__XXX

BO_ 2364633086 EECM3: 8 Vector__XXX
 SG_ ECd3IsttsPCstPssT : 0|16@1+ (0.00390625,-125) [-125|125.99609375] "deg" Vector__XXX
 SG_ ECd3IsttsIdtdMEtvPss : 16|16@1+ (0.0001220703125,-1) [-1|6.8436279296875] "MPa" Vector__XXX
 SG_ EngineCylinder3MisfireRate : 40|8@1+ (0.4,0) [0|100] "%" Vector__XXX
 SG_ EngineCylinder3Temperature : 48|16@1+ (0.03125,-273) [-273|1734.96875] "degC" Vector__XXX
 SG_ ECd3IdtdMEtvPssCtOV : 32|8@1+ (0.04,0) [0|10] "%" Vector__XXX

BO_ 2364633342 EECM4: 8 Vector__XXX
 SG_ ECd4IsttsPCstPssT : 0|16@1+ (0.00390625,-125) [-125|125.99609375] "deg" Vector__XXX
 SG_ ECd4IsttsIdtdMEtvPss : 16|16@1+ (0.0001220703125,-1) [-1|6.8436279296875] "MPa" Vector__XXX
 SG_ EngineCylinder4MisfireRate : 40|8@1+ (0.4,0) [0|100] "%" Vector__XXX
 SG_ EngineCylinder4Temperature : 48|16@1+ (0.03125,-273) [-273|1734.96875] "degC" Vector__XXX
 SG_ ECd4IdtdMEtvPssCtOV : 32|8@1+ (0.04,0) [0|10] "%" Vector__XXX

BO_ 2364633598 EECM5: 8 Vector__XXX
 SG_ ECd5IsttsPCstPssT : 0|16@1+ (0.00390625,-125) [-125|125.99609375] "deg" Vector__XXX
 SG_ ECd5IsttsIdtdMEtvPss : 16|16@1+ (0.0001220703125,-1) [-1|6.8436279296875] "MPa" Vector__XXX
 SG_ EngineCylinder5MisfireRate : 40|8@1+ (0.4,0) [0|100] "%" Vector__XXX
 SG_ EngineCylinder5Temperature : 48|16@1+ (0.03125,-273) [-273|1734.96875] "degC" Vector__XXX
 SG_ ECd5IdtdMEtvPssCtOV : 32|8@1+ (0.04,0) [0|10] "%" Vector__XXX

BO_ 2364633854 EECM6: 8 Vector__XXX
 SG_ ECd6IsttsPCstPssT : 0|16@1+ (0.00390625,-125) [-125|125.99609375] "deg" Vector__XXX
 SG_ ECd6IsttsIdtdMEtvPss : 16|16@1+ (0.0001220703125,-1) [-1|6.8436279296875] "MPa" Vector__XXX
 SG_ EngineCylinder6MisfireRate : 40|8@1+ (0.4,0) [0|100] "%" Vector__XXX
 SG_ EngineCylinder6Temperature : 48|16@1+ (0.03125,-273) [-273|1734.96875] "degC" Vector__XXX
 SG_ ECd6IdtdMEtvPssCtOV : 32|8@1+ (0.04,0) [0|10] "%" Vector__XXX

BO_ 2364634110 EECM7: 8 Vector__XXX
 SG_ ECd7IsttsPCstPssT : 0|16@1+ (0.00390625,-125) [-125|125.99609375] "deg" Vector__XXX
 SG_ ECd7IsttsIdtdMEtvPss : 16|16@1+ (0.0001220703125,-1) [-1|6.8436279296875] "MPa" Vector__XXX
 SG_ EngineCylinder7MisfireRate : 40|8@1+ (0.4,0) [0|100] "%" Vector__XXX
 SG_ EngineCylinder7Temperature : 48|16@1+ (0.03125,-273) [-273|1734.96875] "degC" Vector__XXX
 SG_ ECd7IdtdMEtvPssCtOV : 32|8@1+ (0.04,0) [0|10] "%" Vector__XXX

BO_ 2364634366 EECM8: 8 Vector__XXX
 SG_ ECd8IsttsPCstPssT : 0|16@1+ (0.00390625,-125) [-125|125.99609375] "deg" Vector__XXX
 SG_ ECd8IsttsIdtdMEtvPss : 16|16@1+ (0.0001220703125,-1) [-1|6.8436279296875] "MPa" Vector__XXX
 SG_ EngineCylinder8MisfireRate : 40|8@1+ (0.4,0) [0|100] "%" Vector__XXX
 SG_ EngineCylinder8Temperature : 48|16@1+ (0.03125,-273) [-273|1734.96875] "degC" Vector__XXX
 SG_ ECd8IdtdMEtvPssCtOV : 32|8@1+ (0.04,0) [0|10] "%" Vector__XXX

BO_ 2364634622 EECM9: 8 Vector__XXX
 SG_ ECd9IsttsPCstPssT : 0|16@1+ (0.00390625,-125) [-125|125.99609375] "deg" Vector__XXX
 SG_ ECd9IsttsIdtdMEtvPss : 16|16@1+ (0.0001220703125,-1) [-1|6.8436279296875] "MPa" Vector__XXX
 SG_ EngineCylinder9MisfireRate : 40|8@1+ (0.4,0) [0|100] "%" Vector__XXX
 SG_ EngineCylinder9Temperature : 48|16@1+ (0.03125,-273) [-273|1734.96875] "degC" Vector__XXX
 SG_ ECd9IdtdMEtvPssCtOV : 32|8@1+ (0.04,0) [0|10] "%" Vector__XXX

BO_ 2364634878 EECM10: 8 Vector__XXX
 SG_ ECd10IsttsPCstPssT : 0|16@1+ (0.00390625,-125) [-125|125.99609375] "deg" Vector__XXX
 SG_ ECd10IsttsIdtdMEtvPss : 16|16@1+ (0.0001220703125,-1) [-1|6.8436279296875] "MPa" Vector__XXX
 SG_ EngineCylinder10MisfireRate : 40|8@1+ (0.4,0) [0|100] "%" Vector__XXX
 SG_ EngineCylinder10Temperature : 48|16@1+ (0.03125,-273) [-273|1734.96875] "degC" Vector__XXX
 SG_ ECd10IdtdMEtvPssCtOV : 32|8@1+ (0.04,0) [0|10] "%" Vector__XXX

BO_ 2364635134 EECM11: 8 Vector__XXX
 SG_ ECd11IsttsPCstPssT : 0|16@1+ (0.00390625,-125) [-125|125.99609375] "deg" Vector__XXX
 SG_ ECd11IsttsIdtdMEtvPss : 16|16@1+ (0.0001220703125,-1) [-1|6.8436279296875] "MPa" Vector__XXX
 SG_ EngineCylinder11MisfireRate : 40|8@1+ (0.4,0) [0|100] "%" Vector__XXX
 SG_ EngineCylinder11Temperature : 48|16@1+ (0.03125,-273) [-273|1734.96875] "degC" Vector__XXX
 SG_ ECd11IdtdMEtvPssCtOV : 32|8@1+ (0.04,0) [0|10] "%" Vector__XXX

BO_ 2364635390 EECM12: 8 Vector__XXX
 SG_ ECd12IsttsPCstPssT : 0|16@1+ (0.00390625,-125) [-125|125.99609375] "deg" Vector__XXX
 SG_ ECd12IsttsIdtdMEtvPss : 16|16@1+ (0.0001220703125,-1) [-1|6.8436279296875] "MPa" Vector__XXX
 SG_ EngineCylinder12MisfireRate : 40|8@1+ (0.4,0) [0|100] "%" Vector__XXX
 SG_ EngineCylinder12Temperature : 48|16@1+ (0.03125,-273) [-273|1734.96875] "degC" Vector__XXX
 SG_ ECd12IdtdMEtvPssCtOV : 32|8@1+ (0.04,0) [0|10] "%" Vector__XXX

BO_ 2364635646 EECM13: 8 Vector__XXX
 SG_ ECd13IsttsPCstPssT : 0|16@1+ (0.00390625,-125) [-125|125.99609375] "deg" Vector__XXX
 SG_ ECd13IsttsIdtdMEtvPss : 16|16@1+ (0.0001220703125,-1) [-1|6.8436279296875] "MPa" Vector__XXX
 SG_ EngineCylinder13MisfireRate : 40|8@1+ (0.4,0) [0|100] "%" Vector__XXX
 SG_ EngineCylinder13Temperature : 48|16@1+ (0.03125,-273) [-273|1734.96875] "degC" Vector__XXX
 SG_ ECd13IdtdMEtvPssCtOV : 32|8@1+ (0.04,0) [0|10] "%" Vector__XXX

BO_ 2364635902 EECM14: 8 Vector__XXX
 SG_ ECd14IsttsPCstPssT : 0|16@1+ (0.00390625,-125) [-125|125.99609375] "deg" Vector__XXX
 SG_ ECd14IsttsIdtdMEtvPss : 16|16@1+ (0.0001220703125,-1) [-1|6.8436279296875] "MPa" Vector__XXX
 SG_ EngineCylinder14MisfireRate : 40|8@1+ (0.4,0) [0|100] "%" Vector__XXX
 SG_ EngineCylinder14Temperature : 48|16@1+ (0.03125,-273) [-273|1734.96875] "degC" Vector__XXX
 SG_ ECd14IdtdMEtvPssCtOV : 32|8@1+ (0.04,0) [0|10] "%" Vector__XXX

BO_ 2364636158 EECM15: 8 Vector__XXX
 SG_ ECd15IsttsPCstPssT : 0|16@1+ (0.00390625,-125) [-125|125.99609375] "deg" Vector__XXX
 SG_ ECd15IsttsIdtdMEtvPss : 16|16@1+ (0.0001220703125,-1) [-1|6.8436279296875] "MPa" Vector__XXX
 SG_ EngineCylinder15MisfireRate : 40|8@1+ (0.4,0) [0|100] "%" Vector__XXX
 SG_ EngineCylinder15Temperature : 48|16@1+ (0.03125,-273) [-273|1734.96875] "degC" Vector__XXX
 SG_ ECd15IdtdMEtvPssCtOV : 32|8@1+ (0.04,0) [0|10] "%" Vector__XXX

BO_ 2364636414 EECM16: 8 Vector__XXX
 SG_ ECd16IsttsPCstPssT : 0|16@1+ (0.00390625,-125) [-125|125.99609375] "deg" Vector__XXX
 SG_ ECd16IsttsIdtdMEtvPss : 16|16@1+ (0.0001220703125,-1) [-1|6.8436279296875] "MPa" Vector__XXX
 SG_ EngineCylinder16MisfireRate : 40|8@1+ (0.4,0) [0|100] "%" Vector__XXX
 SG_ EngineCylinder16Temperature : 48|16@1+ (0.03125,-273) [-273|1734.96875] "degC" Vector__XXX
 SG_ ECd16IdtdMEtvPssCtOV : 32|8@1+ (0.04,0) [0|10] "%" Vector__XXX

BO_ 2364636670 EECM17: 8 Vector__XXX
 SG_ ECd17IsttsPCstPssT : 0|16@1+ (0.00390625,-125) [-125|125.99609375] "deg" Vector__XXX
 SG_ ECd17IsttsIdtdMEtvPss : 16|16@1+ (0.0001220703125,-1) [-1|6.8436279296875] "MPa" Vector__XXX
 SG_ EngineCylinder17MisfireRate : 40|8@1+ (0.4,0) [0|100] "%" Vector__XXX
 SG_ EngineCylinder17Temperature : 48|16@1+ (0.03125,-273) [-273|1734.96875] "degC" Vector__XXX
 SG_ ECd17IdtdMEtvPssCtOV : 32|8@1+ (0.04,0) [0|10] "%" Vector__XXX

BO_ 2364636926 EECM18: 8 Vector__XXX
 SG_ ECd18IsttsPCstPssT : 0|16@1+ (0.00390625,-125) [-125|125.99609375] "deg" Vector__XXX
 SG_ ECd18IsttsIdtdMEtvPss : 16|16@1+ (0.0001220703125,-1) [-1|6.8436279296875] "MPa" Vector__XXX
 SG_ EngineCylinder18MisfireRate : 40|8@1+ (0.4,0) [0|100] "%" Vector__XXX
 SG_ EngineCylinder18Temperature : 48|16@1+ (0.03125,-273) [-273|1734.96875] "degC" Vector__XXX
 SG_ ECd18IdtdMEtvPssCtOV : 32|8@1+ (0.04,0) [0|10] "%" Vector__XXX

BO_ 2364637182 EECM19: 8 Vector__XXX
 SG_ ECd19IsttsPCstPssT : 0|16@1+ (0.00390625,-125) [-125|125.99609375] "deg" Vector__XXX
 SG_ ECd19IsttsIdtdMEtvPss : 16|16@1+ (0.0001220703125,-1) [-1|6.8436279296875] "MPa" Vector__XXX
 SG_ EngineCylinder19MisfireRate : 40|8@1+ (0.4,0) [0|100] "%" Vector__XXX
 SG_ EngineCylinder19Temperature : 48|16@1+ (0.03125,-273) [-273|1734.96875] "degC" Vector__XXX
 SG_ ECd19IdtdMEtvPssCtOV : 32|8@1+ (0.04,0) [0|10] "%" Vector__XXX

BO_ 2364637438 EECM20: 8 Vector__XXX
 SG_ ECd20IsttsPCstPssT : 0|16@1+ (0.00390625,-125) [-125|125.99609375] "deg" Vector__XXX
 SG_ ECd20IsttsIdtdMEtvPss : 16|16@1+ (0.0001220703125,-1) [-1|6.8436279296875] "MPa" Vector__XXX
 SG_ EngineCylinder20MisfireRate : 40|8@1+ (0.4,0) [0|100] "%" Vector__XXX
 SG_ EngineCylinder20Temperature : 48|16@1+ (0.03125,-273) [-273|1734.96875] "degC" Vector__XXX
 SG_ ECd20IdtdMEtvPssCtOV : 32|8@1+ (0.04,0) [0|10] "%" Vector__XXX

BO_ 2364637694 MG1IMF1: 8 Vector__XXX
 SG_ MtrGnrtr1InvrtrMdFdk1Cntr : 8|4@1+ (1,0) [0|15] "" Vector__XXX
 SG_ MtrGnrtr1InvrtrCntrlLmtsOvrrdMd : 12|4@1+ (1,0) [0|15] "" Vector__XXX
 SG_ MtrGnrtr1InvrtrCntrlStpntMd : 16|5@1+ (1,0) [0|31] "" Vector__XXX
 SG_ MtrGnrtr1InvrtrMdFdk1Cr : 0|8@1+ (1,0) [0|250] "count" Vector__XXX
 SG_ MtrGnrtr1InvrtrHvlStts : 21|2@1+ (1,0) [0|3] "" Vector__XXX

BO_ 2565964542 MG1ILAP: 8 Vector__XXX
 SG_ MtrGnrtr1InvrtrLmtsAtvPwrCntr : 8|4@1+ (1,0) [0|15] "" Vector__XXX
 SG_ MtrGnrtr1InvrtrLmtsAtvPwrCr : 0|8@1+ (1,0) [0|250] "count" Vector__XXX
 SG_ MtGt1IvtLtsAtvMPwMx : 12|12@1+ (0.0625,-125) [-125|125.9375] "%" Vector__XXX
 SG_ MtGt1IvtLtsAtvMPwM : 24|12@1+ (0.0625,-125) [-125|125.9375] "%" Vector__XXX
 SG_ MtGt1IvtLtsAtvDSdPwMx : 36|12@1+ (0.0625,-125) [-125|125.9375] "%" Vector__XXX
 SG_ MtGt1IvtLtsAtvDSdPwM : 48|12@1+ (0.0625,-125) [-125|125.9375] "%" Vector__XXX

BO_ 2565964798 MG1ILAM: 8 Vector__XXX
 SG_ MtrGnrtr1InvrtrLmtsAtvMhnlCntr : 8|4@1+ (1,0) [0|15] "" Vector__XXX
 SG_ MtrGnrtr1InvrtrLmtsAtvMhnlCr : 0|8@1+ (1,0) [0|250] "count" Vector__XXX
 SG_ MtrGnrtr1InvrtrLmtsAtvTrqMxmm : 12|12@1+ (0.0625,-125) [-125|125.9375] "%" Vector__XXX
 SG_ MtrGnrtr1InvrtrLmtsAtvTrqMnmm : 24|12@1+ (0.0625,-125) [-125|125.9375] "%" Vector__XXX
 SG_ MtrGnrtr1InvrtrLmtsAtvSpdMxmm : 36|12@1+ (0.0625,-125) [-125|125.9375] "%" Vector__XXX
 SG_ MtrGnrtr1InvrtrLmtsAtvSpdMnmm : 48|12@1+ (0.0625,-125) [-125|125.9375] "%" Vector__XXX

BO_ 2565965054 MG1ILADC: 8 Vector__XXX
 SG_ MtrGnrtr1InvrtrLmtsAtvDSdCr : 0|8@1+ (1,0) [0|250] "count" Vector__XXX
 SG_ MtrGnrtr1InvrtrLmtsAtvDSdCntr : 8|4@1+ (1,0) [0|15] "" Vector__XXX
 SG_ MtGt1IvtLtsAtvDSdVtMx : 12|12@1+ (0.0625,-125) [-125|125.9375] "%" Vector__XXX
 SG_ MtGt1IvtLtsAtvDSdVtM : 24|12@1+ (0.0625,-125) [-125|125.9375] "%" Vector__XXX
 SG_ MtGt1IvtLtsAtvDSdCtMx : 36|12@1+ (0.0625,-125) [-125|125.9375] "%" Vector__XXX
 SG_ MtGt1IvtLtsAtvDSdCtM : 48|12@1+ (0.0625,-125) [-125|125.9375] "%" Vector__XXX

BO_ 2565965310 MG1ILV: 8 Vector__XXX
 SG_ MtrGnrtr1InvrtrSwthdIgntnVltg : 0|16@1+ (0.05,0) [0|3212.75] "V" Vector__XXX
 SG_ MtrGnrtr1InvrtrUnswthdSlVltg : 16|16@1+ (0.05,0) [0|3212.75] "V" Vector__XXX

BO_ 2364638974 MG2IMF1: 8 Vector__XXX
 SG_ MtrGnrtr2InvrtrMdFdk1Cntr : 8|4@1+ (1,0) [0|15] "" Vector__XXX
 SG_ MtrGnrtr2InvrtrCntrlLmtsOvrrdMd : 12|4@1+ (1,0) [0|15] "" Vector__XXX
 SG_ MtrGnrtr2InvrtrCntrlStpntMd : 16|5@1+ (1,0) [0|31] "" Vector__XXX
 SG_ MtrGnrtr2InvrtrMdFdk1Cr : 0|8@1+ (1,0) [0|250] "count" Vector__XXX
 SG_ MtrGnrtr2InvrtrHvlStts : 21|2@1+ (1,0) [0|3] "" Vector__XXX

BO_ 2565965822 MG2ILAP: 8 Vector__XXX
 SG_ MtrGnrtr2InvrtrLmtsAtvPwrCntr : 8|4@1+ (1,0) [0|15] "" Vector__XXX
 SG_ MtrGnrtr2InvrtrLmtsAtvPwrCr : 0|8@1+ (1,0) [0|250] "count" Vector__XXX
 SG_ MtGt2IvtLtsAtvMPwMx : 12|12@1+ (0.0625,-125) [-125|125.9375] "%" Vector__XXX
 SG_ MtGt2IvtLtsAtvMPwM : 24|12@1+ (0.0625,-125) [-125|125.9375] "%" Vector__XXX
 SG_ MtGt2IvtLtsAtvDSdPwMx : 36|12@1+ (0.0625,-125) [-125|125.9375] "%" Vector__XXX
 SG_ MtGt2IvtLtsAtvDSdPwM : 48|12@1+ (0.0625,-125) [-125|125.9375] "%" Vector__XXX

BO_ 2565966078 MG2ILAM: 8 Vector__XXX
 SG_ MtrGnrtr2InvrtrLmtsAtvMhnlCntr : 8|4@1+ (1,0) [0|15] "" Vector__XXX
 SG_ MtrGnrtr2InvrtrLmtsAtvMhnlCr : 0|8@1+ (1,0) [0|250] "count" Vector__XXX
 SG_ MtrGnrtr2InvrtrLmtsAtvTrqMxmm : 12|12@1+ (0.0625,-125) [-125|125.9375] "%" Vector__XXX
 SG_ MtrGnrtr2InvrtrLmtsAtvTrqMnmm : 24|12@1+ (0.0625,-125) [-125|125.9375] "%" Vector__XXX
 SG_ MtrGnrtr2InvrtrLmtsAtvSpdMxmm : 36|12@1+ (0.0625,-125) [-125|125.9375] "%" Vector__XXX
 SG_ MtrGnrtr2InvrtrLmtsAtvSpdMnmm : 48|12@1+ (0.0625,-125) [-125|125.9375] "%" Vector__XXX

BO_ 2565966334 MG2ILADC: 8 Vector__XXX
 SG_ MtrGnrtr2InvrtrLmtsAtvDSdCr : 0|8@1+ (1,0) [0|250] "count" Vector__XXX
 SG_ MtrGnrtr2InvrtrLmtsAtvDSdCntr : 8|4@1+ (1,0) [0|15] "" Vector__XXX
 SG_ MtGt2IvtLtsAtvDSdVtMx : 12|12@1+ (0.0625,-125) [-125|125.9375] "%" Vector__XXX
 SG_ MtGt2IvtLtsAtvDSdVtM : 24|12@1+ (0.0625,-125) [-125|125.9375] "%" Vector__XXX
 SG_ MtGt2IvtLtsAtvDSdCtMx : 36|12@1+ (0.0625,-125) [-125|125.9375] "%" Vector__XXX
 SG_ MtGt2IvtLtsAtvDSdCtM : 48|12@1+ (0.0625,-125) [-125|125.9375] "%" Vector__XXX

BO_ 2565966590 MG2ILV: 8 Vector__XXX
 SG_ MtrGnrtr2InvrtrSwthdIgntnVltg : 0|16@1+ (0.05,0) [0|3212.75] "V" Vector__XXX
 SG_ MtrGnrtr2InvrtrUnswthdSlVltg : 16|16@1+ (0.05,0) [0|3212.75] "V" Vector__XXX

BO_ 2365287678 MG2IR1: 8 Vector__XXX
 SG_ MtrGnrtr2InvrtrRfrn1Cntr : 8|4@1+ (1,0) [0|15] "" Vector__XXX
 SG_ MtrGnrtr2InvrtrRfrnTrq : 16|16@1+ (0.5,0) [0|32127.5] "Nm" Vector__XXX
 SG_ MtrGnrtr2InvrtrRfrnSpd : 32|16@1+ (4,0) [0|257020] "rpm" Vector__XXX
 SG_ MtrGnrtr2InvrtrRfrnPwr : 48|16@1+ (0.0625,0) [0|4015.9375] "kW" Vector__XXX
 SG_ MtrGnrtr2InvrtrRfrn1Cr : 0|8@1+ (1,0) [0|250] "count" Vector__XXX

BO_ 2365287934 MG2IS1: 8 Vector__XXX
 SG_ MtrGnrtr2InvrtrStts1Cntr : 8|4@1+ (1,0) [0|15] "" Vector__XXX
 SG_ MotorGenerator2Speed : 24|16@1+ (0.00390625,-125) [-125|125.99609375] "%" Vector__XXX
 SG_ MtrGnrtr2InvrtrStts1Cr : 0|8@1+ (1,0) [0|250] "count" Vector__XXX
 SG_ MotorGenerator2Torque : 12|12@1+ (0.0625,-125) [-125|125.9375] "%" Vector__XXX
 SG_ MtrGnrtr2InvrtrDSdCrrnt : 40|12@1+ (0.0625,-125) [-125|125.9375] "%" Vector__XXX
 SG_ MtrGnrtr2InvrtrDSdVltg : 52|12@1+ (0.0625,-125) [-125|125.9375] "%" Vector__XXX

BO_ 2365288190 MG2IR2: 8 Vector__XXX
 SG_ MtrGnrtr2InvrtrRfrn2Cntr : 8|4@1+ (1,0) [0|15] "" Vector__XXX
 SG_ MtrGnrtr2InvrtrRfrnCrrnt : 32|16@1+ (0.125,0) [0|8031.875] "A" Vector__XXX
 SG_ MtrGnrtr2InvrtrRfrnVltg : 48|16@1+ (0.125,0) [0|8031.875] "V" Vector__XXX
 SG_ MtrGnrtr2InvrtrRfrn2Cr : 0|8@1+ (1,0) [0|250] "count" Vector__XXX

BO_ 2566615038 MG2IT: 8 Vector__XXX
 SG_ MtrGnrtr2InvrtrTmprtr1 : 0|8@1+ (1,-40) [-40|210] "degC" Vector__XXX
 SG_ MtrGnrtr2InvrtrTmprtr2 : 8|8@1+ (1,-40) [-40|210] "degC" Vector__XXX
 SG_ MtrGnrtr2InvrtrTmprtr3 : 16|8@1+ (1,-40) [-40|210] "degC" Vector__XXX
 SG_ MtrGnrtr2InvrtrTmprtr4 : 24|8@1+ (1,-40) [-40|210] "degC" Vector__XXX
 SG_ MtrGnrtr2InvrtrTmprtr5 : 32|8@1+ (1,-40) [-40|210] "degC" Vector__XXX

BO_ 2566615294 MG2IMT: 8 Vector__XXX
 SG_ MotorGenerator2Temperature1 : 0|8@1+ (1,-40) [-40|210] "degC" Vector__XXX
 SG_ MotorGenerator2Temperature2 : 8|8@1+ (1,-40) [-40|210] "degC" Vector__XXX
 SG_ MotorGenerator2Temperature3 : 16|8@1+ (1,-40) [-40|210] "degC" Vector__XXX
 SG_ MotorGenerator2Temperature4 : 24|8@1+ (1,-40) [-40|210] "degC" Vector__XXX

BO_ 2566615550 MG1IMT: 8 Vector__XXX
 SG_ MotorGenerator1Temperature1 : 0|8@1+ (1,-40) [-40|210] "degC" Vector__XXX
 SG_ MotorGenerator1Temperature2 : 8|8@1+ (1,-40) [-40|210] "degC" Vector__XXX
 SG_ MotorGenerator1Temperature3 : 16|8@1+ (1,-40) [-40|210] "degC" Vector__XXX
 SG_ MotorGenerator1Temperature4 : 24|8@1+ (1,-40) [-40|210] "degC" Vector__XXX

BO_ 2566615806 MG1IT: 8 Vector__XXX
 SG_ MtrGnrtr1InvrtrTmprtr1 : 0|8@1+ (1,-40) [-40|210] "degC" Vector__XXX
 SG_ MtrGnrtr1InvrtrTmprtr2 : 8|8@1+ (1,-40) [-40|210] "degC" Vector__XXX
 SG_ MtrGnrtr1InvrtrTmprtr3 : 16|8@1+ (1,-40) [-40|210] "degC" Vector__XXX
 SG_ MtrGnrtr1InvrtrTmprtr4 : 24|8@1+ (1,-40) [-40|210] "degC" Vector__XXX
 SG_ MtrGnrtr1InvrtrTmprtr5 : 32|8@1+ (1,-40) [-40|210] "degC" Vector__XXX

BO_ 2365289470 MG1IR2: 8 Vector__XXX
 SG_ MtrGnrtr1InvrtrRfrn2Cntr : 8|4@1+ (1,0) [0|15] "" Vector__XXX
 SG_ MtrGnrtr1InvrtrRfrnCrrnt : 32|16@1+ (0.125,0) [0|8031.875] "A" Vector__XXX
 SG_ MtrGnrtr1InvrtrRfrnVltg : 48|16@1+ (0.125,0) [0|8031.875] "V" Vector__XXX
 SG_ MtrGnrtr1InvrtrRfrn2Cr : 0|8@1+ (1,0) [0|250] "count" Vector__XXX

BO_ 2365289726 MG1IS1: 8 Vector__XXX
 SG_ MtrGnrtr1InvrtrStts1Cntr : 8|4@1+ (1,0) [0|15] "" Vector__XXX
 SG_ MotorGenerator1Torque : 12|12@1+ (0.0625,-125) [-125|125.9375] "%" Vector__XXX
 SG_ MotorGenerator1Speed : 24|16@1+ (0.00390625,-125) [-125|125.99609375] "%" Vector__XXX
 SG_ MtrGnrtr1InvrtrStts1Cr : 0|8@1+ (1,0) [0|250] "count" Vector__XXX
 SG_ MtrGnrtr1InvrtrDSdCrrnt : 40|12@1+ (0.0625,-125) [-125|125.9375] "%" Vector__XXX
 SG_ MtrGnrtr1InvrtrDSdVltg : 52|12@1+ (0.0625,-125) [-125|125.9375] "%" Vector__XXX

BO_ 2365289982 MG1IR1: 8 Vector__XXX
 SG_ MtrGnrtr1InvrtrRfrn1Cntr : 8|4@1+ (1,0) [0|15] "" Vector__XXX
 SG_ MtrGnrtr1InvrtrRfrnTrq : 16|16@1+ (0.5,0) [0|32127.5] "Nm" Vector__XXX
 SG_ MtrGnrtr1InvrtrRfrnSpd : 32|16@1+ (4,0) [0|257020] "rpm" Vector__XXX
 SG_ MtrGnrtr1InvrtrRfrnPwr : 48|16@1+ (0.0625,0) [0|4015.9375] "kW" Vector__XXX
 SG_ MtrGnrtr1InvrtrRfrn1Cr : 0|8@1+ (1,0) [0|250] "count" Vector__XXX

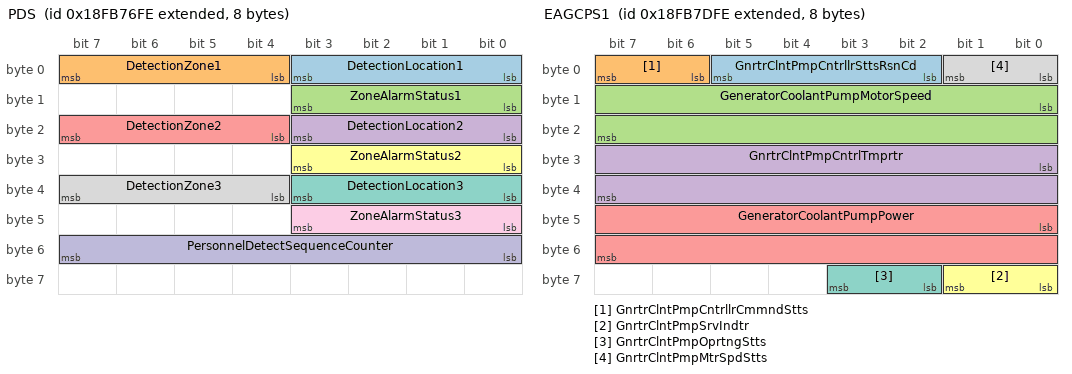
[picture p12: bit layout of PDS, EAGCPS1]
BO_ 2566616830 PDS: 8 Vector__XXX
 SG_ DetectionLocation1 : 0|4@1+ (1,0) [0|13] "count" Vector__XXX
 SG_ DetectionZone1 : 4|4@1+ (1,0) [0|13] "count" Vector__XXX
 SG_ ZoneAlarmStatus1 : 8|4@1+ (1,0) [0|15] "" Vector__XXX
 SG_ DetectionLocation2 : 16|4@1+ (1,0) [0|13] "count" Vector__XXX
 SG_ DetectionZone2 : 20|4@1+ (1,0) [0|13] "count" Vector__XXX
 SG_ ZoneAlarmStatus2 : 24|4@1+ (1,0) [0|15] "" Vector__XXX
 SG_ DetectionLocation3 : 32|4@1+ (1,0) [0|13] "count" Vector__XXX
 SG_ DetectionZone3 : 36|4@1+ (1,0) [0|13] "count" Vector__XXX
 SG_ ZoneAlarmStatus3 : 40|4@1+ (1,0) [0|15] "" Vector__XXX
 SG_ PersonnelDetectSequenceCounter : 48|8@1+ (1,0) [0|250] "count" Vector__XXX

BO_ 2566617086 ECPG1: 8 Vector__XXX
 SG_ EngnClndr1CmprssnGmmRt : 0|8@1+ (0.004,1) [1|2] "" Vector__XXX
 SG_ EngnClndr1ExpnsnGmmRt : 8|8@1+ (0.004,1) [1|2] "" Vector__XXX
 SG_ EngnClndr2CmprssnGmmRt : 16|8@1+ (0.004,1) [1|2] "" Vector__XXX
 SG_ EngnClndr2ExpnsnGmmRt : 24|8@1+ (0.004,1) [1|2] "" Vector__XXX
 SG_ EngnClndr3CmprssnGmmRt : 32|8@1+ (0.004,1) [1|2] "" Vector__XXX
 SG_ EngnClndr3ExpnsnGmmRt : 40|8@1+ (0.004,1) [1|2] "" Vector__XXX
 SG_ EngnClndr4CmprssnGmmRt : 48|8@1+ (0.004,1) [1|2] "" Vector__XXX
 SG_ EngnClndr4ExpnsnGmmRt : 56|8@1+ (0.004,1) [1|2] "" Vector__XXX

BO_ 2566617342 ECPG2: 8 Vector__XXX
 SG_ EngnClndr5CmprssnGmmRt : 0|8@1+ (0.004,1) [1|2] "" Vector__XXX
 SG_ EngnClndr5ExpnsnGmmRt : 8|8@1+ (0.004,1) [1|2] "" Vector__XXX
 SG_ EngnClndr6CmprssnGmmRt : 16|8@1+ (0.004,1) [1|2] "" Vector__XXX
 SG_ EngnClndr6ExpnsnGmmRt : 24|8@1+ (0.004,1) [1|2] "" Vector__XXX
 SG_ EngnClndr7CmprssnGmmRt : 32|8@1+ (0.004,1) [1|2] "" Vector__XXX
 SG_ EngnClndr7ExpnsnGmmRt : 40|8@1+ (0.004,1) [1|2] "" Vector__XXX
 SG_ EngnClndr8CmprssnGmmRt : 48|8@1+ (0.004,1) [1|2] "" Vector__XXX
 SG_ EngnClndr8ExpnsnGmmRt : 56|8@1+ (0.004,1) [1|2] "" Vector__XXX

BO_ 2566617598 ECPG3: 8 Vector__XXX
 SG_ EngnClndr9CmprssnGmmRt : 0|8@1+ (0.004,1) [1|2] "" Vector__XXX
 SG_ EngnClndr9ExpnsnGmmRt : 8|8@1+ (0.004,1) [1|2] "" Vector__XXX
 SG_ EngnClndr10CmprssnGmmRt : 16|8@1+ (0.004,1) [1|2] "" Vector__XXX
 SG_ EngnClndr10ExpnsnGmmRt : 24|8@1+ (0.004,1) [1|2] "" Vector__XXX
 SG_ EngnClndr11CmprssnGmmRt : 32|8@1+ (0.004,1) [1|2] "" Vector__XXX
 SG_ EngnClndr11ExpnsnGmmRt : 40|8@1+ (0.004,1) [1|2] "" Vector__XXX
 SG_ EngnClndr12CmprssnGmmRt : 48|8@1+ (0.004,1) [1|2] "" Vector__XXX
 SG_ EngnClndr12ExpnsnGmmRt : 56|8@1+ (0.004,1) [1|2] "" Vector__XXX

BO_ 2566617854 ECPG4: 8 Vector__XXX
 SG_ EngnClndr13CmprssnGmmRt : 0|8@1+ (0.004,1) [1|2] "" Vector__XXX
 SG_ EngnClndr13ExpnsnGmmRt : 8|8@1+ (0.004,1) [1|2] "" Vector__XXX
 SG_ EngnClndr14CmprssnGmmRt : 16|8@1+ (0.004,1) [1|2] "" Vector__XXX
 SG_ EngnClndr14ExpnsnGmmRt : 24|8@1+ (0.004,1) [1|2] "" Vector__XXX
 SG_ EngnClndr15CmprssnGmmRt : 32|8@1+ (0.004,1) [1|2] "" Vector__XXX
 SG_ EngnClndr15ExpnsnGmmRt : 40|8@1+ (0.004,1) [1|2] "" Vector__XXX
 SG_ EngnClndr16CmprssnGmmRt : 48|8@1+ (0.004,1) [1|2] "" Vector__XXX
 SG_ EngnClndr16ExpnsnGmmRt : 56|8@1+ (0.004,1) [1|2] "" Vector__XXX

BO_ 2566618110 ECPG5: 8 Vector__XXX
 SG_ EngnClndr17CmprssnGmmRt : 0|8@1+ (0.004,1) [1|2] "" Vector__XXX
 SG_ EngnClndr17ExpnsnGmmRt : 8|8@1+ (0.004,1) [1|2] "" Vector__XXX
 SG_ EngnClndr18CmprssnGmmRt : 16|8@1+ (0.004,1) [1|2] "" Vector__XXX
 SG_ EngnClndr18ExpnsnGmmRt : 24|8@1+ (0.004,1) [1|2] "" Vector__XXX
 SG_ EngnClndr19CmprssnGmmRt : 32|8@1+ (0.004,1) [1|2] "" Vector__XXX
 SG_ EngnClndr19ExpnsnGmmRt : 40|8@1+ (0.004,1) [1|2] "" Vector__XXX
 SG_ EngnClndr20CmprssnGmmRt : 48|8@1+ (0.004,1) [1|2] "" Vector__XXX
 SG_ EngnClndr20ExpnsnGmmRt : 56|8@1+ (0.004,1) [1|2] "" Vector__XXX

BO_ 2566618622 EAGCPS1: 8 Vector__XXX
 SG_ GnrtrClntPmpCntrllrSttsRsnCd : 2|4@1+ (1,0) [0|15] "" Vector__XXX
 SG_ GnrtrClntPmpCntrllrCmmndStts : 6|2@1+ (1,0) [0|3] "" Vector__XXX
 SG_ GeneratorCoolantPumpMotorSpeed : 8|16@1+ (0.5,0) [0|32127.5] "rpm" Vector__XXX
 SG_ GnrtrClntPmpCntrlTmprtr : 24|16@1+ (0.03125,-273) [-273|1734.96875] "degC" Vector__XXX
 SG_ GeneratorCoolantPumpPower : 40|16@1+ (0.5,0) [0|32127.5] "W" Vector__XXX
 SG_ GnrtrClntPmpSrvIndtr : 56|2@1+ (1,0) [0|3] "" Vector__XXX
 SG_ GnrtrClntPmpOprtngStts : 58|2@1+ (1,0) [0|3] "" Vector__XXX
 SG_ GnrtrClntPmpMtrSpdStts : 0|2@1+ (1,0) [0|3] "" Vector__XXX

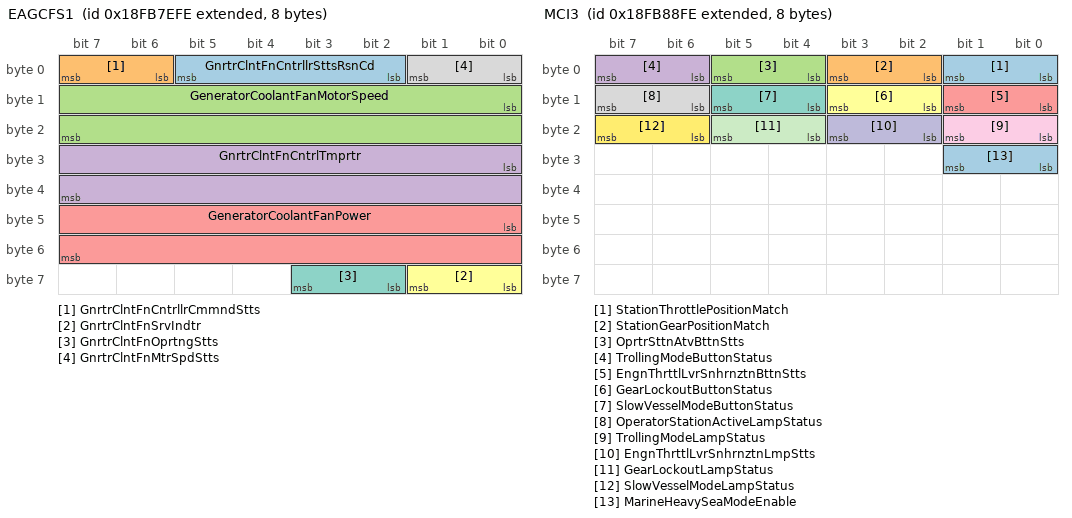
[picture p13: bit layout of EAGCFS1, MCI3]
BO_ 2566618878 EAGCFS1: 8 Vector__XXX
 SG_ GnrtrClntFnCntrllrSttsRsnCd : 2|4@1+ (1,0) [0|15] "" Vector__XXX
 SG_ GnrtrClntFnCntrllrCmmndStts : 6|2@1+ (1,0) [0|3] "" Vector__XXX
 SG_ GeneratorCoolantFanMotorSpeed : 8|16@1+ (0.5,0) [0|32127.5] "rpm" Vector__XXX
 SG_ GnrtrClntFnCntrlTmprtr : 24|16@1+ (0.03125,-273) [-273|1734.96875] "degC" Vector__XXX
 SG_ GeneratorCoolantFanPower : 40|16@1+ (0.5,0) [0|32127.5] "W" Vector__XXX
 SG_ GnrtrClntFnSrvIndtr : 56|2@1+ (1,0) [0|3] "" Vector__XXX
 SG_ GnrtrClntFnOprtngStts : 58|2@1+ (1,0) [0|3] "" Vector__XXX
 SG_ GnrtrClntFnMtrSpdStts : 0|2@1+ (1,0) [0|3] "" Vector__XXX

BO_ 2566619134 WSPF: 8 Vector__XXX
 SG_ WllStmltnPmpOlFltrDffrntlPrssr : 0|8@1+ (4,0) [0|1000] "kPa" Vector__XXX
 SG_ WllStmltnPmpOlFltrBpssSwthStts : 24|2@1+ (1,0) [0|3] "" Vector__XXX
 SG_ WllStmltnPmpGrBxOtltOlPrssr : 8|16@1+ (0.1,0) [0|6425.5] "kPa" Vector__XXX

BO_ 2566619390 PTOGC: 22 Vector__XXX
 SG_ MinimumPtoGovernorSetSpeed : 128|16@1+ (0.125,0) [0|8031.875] "rpm" Vector__XXX
 SG_ MaximumPtoGovernorSetSpeed : 144|16@1+ (0.125,0) [0|8031.875] "rpm" Vector__XXX
 SG_ PrprgrmmdPtGvrnrStSpd1 : 0|16@1+ (0.125,0) [0|8031.875] "rpm" Vector__XXX
 SG_ PrprgrmmdPtGvrnrStSpd2 : 16|16@1+ (0.125,0) [0|8031.875] "rpm" Vector__XXX
 SG_ PrprgrmmdPtGvrnrStSpd3 : 32|16@1+ (0.125,0) [0|8031.875] "rpm" Vector__XXX
 SG_ PrprgrmmdPtGvrnrStSpd4 : 48|16@1+ (0.125,0) [0|8031.875] "rpm" Vector__XXX
 SG_ PrprgrmmdPtGvrnrStSpd5 : 64|16@1+ (0.125,0) [0|8031.875] "rpm" Vector__XXX
 SG_ PrprgrmmdPtGvrnrStSpd6 : 80|16@1+ (0.125,0) [0|8031.875] "rpm" Vector__XXX
 SG_ PrprgrmmdPtGvrnrStSpd7 : 96|16@1+ (0.125,0) [0|8031.875] "rpm" Vector__XXX
 SG_ PrprgrmmdPtGvrnrStSpd8 : 112|16@1+ (0.125,0) [0|8031.875] "rpm" Vector__XXX
 SG_ PtGvrnrAlrtrOvrrdMxmmSpd : 160|16@1+ (0.125,0) [0|8031.875] "rpm" Vector__XXX

BO_ 2566619646 OBP2: 8 Vector__XXX
 SG_ OnBrdPrgrmmngInttRqst : 8|2@1+ (1,0) [0|3] "" Vector__XXX
 SG_ OnBrdPrgrmmngInttInht : 10|2@1+ (1,0) [0|3] "" Vector__XXX
 SG_ OnBrdPrgrmmngInttEAddrss : 0|8@1+ (1,0) [0|250] "sourceadr" Vector__XXX

BO_ 2566620670 EIMI: 8 Vector__XXX
 SG_ EngineIdleManagementStatus : 0|4@1+ (1,0) [0|15] "" Vector__XXX
 SG_ IdlMngmntPndngEvntTmRmnng : 16|16@1+ (1,0) [0|64255] "s" Vector__XXX
 SG_ EngnIdlMngmntEngnRstrtRsn : 4|4@1+ (1,0) [0|15] "" Vector__XXX
 SG_ EngnIdlMngmntEngnShtdwnRsn : 8|4@1+ (1,0) [0|15] "" Vector__XXX

BO_ 2566621438 MCI3: 8 Vector__XXX
 SG_ StationThrottlePositionMatch : 0|2@1+ (1,0) [0|3] "" Vector__XXX
 SG_ StationGearPositionMatch : 2|2@1+ (1,0) [0|3] "" Vector__XXX
 SG_ OprtrSttnAtvBttnStts : 4|2@1+ (1,0) [0|3] "" Vector__XXX
 SG_ TrollingModeButtonStatus : 6|2@1+ (1,0) [0|3] "" Vector__XXX
 SG_ EngnThrttlLvrSnhrnztnBttnStts : 8|2@1+ (1,0) [0|3] "" Vector__XXX
 SG_ GearLockoutButtonStatus : 10|2@1+ (1,0) [0|3] "" Vector__XXX
 SG_ SlowVesselModeButtonStatus : 12|2@1+ (1,0) [0|3] "" Vector__XXX
 SG_ OperatorStationActiveLampStatus : 14|2@1+ (1,0) [0|3] "" Vector__XXX
 SG_ TrollingModeLampStatus : 16|2@1+ (1,0) [0|3] "" Vector__XXX
 SG_ EngnThrttlLvrSnhrnztnLmpStts : 18|2@1+ (1,0) [0|3] "" Vector__XXX
 SG_ GearLockoutLampStatus : 20|2@1+ (1,0) [0|3] "" Vector__XXX
 SG_ SlowVesselModeLampStatus : 22|2@1+ (1,0) [0|3] "" Vector__XXX
 SG_ MarineHeavySeaModeEnable : 24|2@1+ (1,0) [0|3] "" Vector__XXX

BO_ 2566621694 EFLP13: 8 Vector__XXX
 SG_ EngineOilPressure2 : 0|8@1+ (4,0) [0|1000] "kPa" Vector__XXX
 SG_ EngnChrgArClr2OtltPrssr : 8|8@1+ (2,0) [0|500] "kPa" Vector__XXX
 SG_ EngnChrgArClr1DffrntlPrssr : 16|8@1+ (0.5,0) [0|125] "kPa" Vector__XXX
 SG_ EngnChrgArClr2DffrntlPrssr : 24|8@1+ (0.5,0) [0|125] "kPa" Vector__XXX
 SG_ EngnCrnksBrthrOlSprtrOtltPrssr : 32|16@1+ (0.0078125,-250) [-250|251.9921875] "kPa" Vector__XXX
 SG_ EngineOilLevel1State : 48|2@1+ (1,0) [0|3] "" Vector__XXX
 SG_ EngineOilLevel2State : 50|2@1+ (1,0) [0|3] "" Vector__XXX

BO_ 2365295358 HVESSD11: 8 Vector__XXX
 SG_ HvessActualChargeRate : 32|16@1+ (0.05,0) [0|3212.75] "kW" Vector__XXX
 SG_ HvssBsVltgNgtvTChsssGrndVltg : 0|16@1+ (0.05,0) [0|3212.75] "V" Vector__XXX
 SG_ HvssVltgLvlNgtvTChsssGrndVltg : 16|16@1+ (0.05,0) [0|3212.75] "V" Vector__XXX
 SG_ HvssTtlStrdEnrgSrLvl : 48|8@1+ (0.4,0) [0|100] "%" Vector__XXX
 SG_ HvssPwrMdlEltrnsTmprtr : 56|8@1+ (1,-40) [-40|210] "degC" Vector__XXX

BO_ 2566622206 EMIH: 8 Vector__XXX
 SG_ EconomyModeTotalHoursInactive : 0|32@1+ (0.05,0) [0|210554060.75] "h" Vector__XXX
 SG_ EconomyModeTripHoursInactive : 32|32@1+ (0.05,0) [0|210554060.75] "h" Vector__XXX

BO_ 2566622462 EMEIFSR: 8 Vector__XXX
 SG_ EnmMdEstmtdInstntnsFlSvngsRt : 0|16@1+ (0.05,0) [0|3212.75] "l/h" Vector__XXX
 SG_ EMdEsttdIsttsFSvsRtPt : 16|16@1+ (0.0025,0) [0|160.6375] "%" Vector__XXX

BO_ 2566622718 EMAH: 8 Vector__XXX
 SG_ EconomyModeTotalHoursActive : 0|32@1+ (0.05,0) [0|210554060.75] "h" Vector__XXX
 SG_ EconomyModeTripHoursActive : 32|32@1+ (0.05,0) [0|210554060.75] "h" Vector__XXX

BO_ 2566622974 EMFU: 8 Vector__XXX
 SG_ EconomyModeTotalFuelUsed : 0|32@1+ (0.5,0) [0|2105540607.5] "l" Vector__XXX
 SG_ EconomyModeTripFuelUsed : 32|32@1+ (0.5,0) [0|2105540607.5] "l" Vector__XXX

BO_ 2566623230 EMEFS: 8 Vector__XXX
 SG_ EnmMdTtlEstmtdFlSvd : 0|32@1+ (0.5,0) [0|2105540607.5] "l" Vector__XXX
 SG_ EnmMdTrpEstmtdFlSvd : 32|32@1+ (0.5,0) [0|2105540607.5] "l" Vector__XXX

BO_ 2552823550 MG1IRLR1: 8 Vector__XXX
 SG_ MtrGnrtr1InvrtrRtLmtsRqst1Cntr : 8|4@1+ (1,0) [0|15] "" Vector__XXX
 SG_ MtGt1IvtRtLtsRqstAstSpdRtLt : 12|12@1+ (0.25,0) [0|1003.75] "%/s" Vector__XXX
 SG_ MtGt1IvtRtLtsRqstAstTqRtLt : 24|12@1+ (2,0) [0|8030] "%/s" Vector__XXX
 SG_ MtrGnrtr1InvrtrRtLmtsRqst1Cr : 0|8@1+ (1,0) [0|250] "count" Vector__XXX

BO_ 2552889086 MG2IRLR1: 8 Vector__XXX
 SG_ MtrGnrtr2InvrtrRtLmtsRqst1Cntr : 8|4@1+ (1,0) [0|15] "" Vector__XXX
 SG_ MtGt2IvtRtLtsRqstAstSpdRtLt : 12|12@1+ (0.25,0) [0|1003.75] "%/s" Vector__XXX
 SG_ MtGt2IvtRtLtsRqstAstTqRtLt : 24|12@1+ (2,0) [0|8030] "%/s" Vector__XXX
 SG_ MtrGnrtr2InvrtrRtLmtsRqst1Cr : 0|8@1+ (1,0) [0|250] "count" Vector__XXX

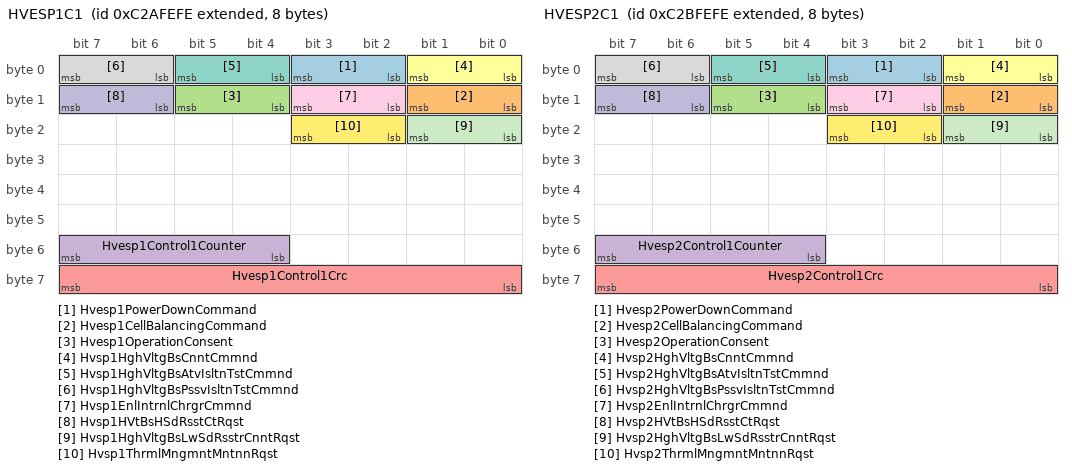
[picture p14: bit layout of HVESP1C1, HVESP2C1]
BO_ 2351628030 HVESP1C1: 8 Vector__XXX
 SG_ Hvesp1PowerDownCommand : 2|2@1+ (1,0) [0|3] "" Vector__XXX
 SG_ Hvesp1CellBalancingCommand : 8|2@1+ (1,0) [0|3] "" Vector__XXX
 SG_ Hvesp1OperationConsent : 12|2@1+ (1,0) [0|3] "" Vector__XXX
 SG_ Hvesp1Control1Counter : 52|4@1+ (1,0) [0|15] "" Vector__XXX
 SG_ Hvesp1Control1Crc : 56|8@1+ (1,0) [0|250] "count" Vector__XXX
 SG_ Hvsp1HghVltgBsCnntCmmnd : 0|2@1+ (1,0) [0|3] "" Vector__XXX
 SG_ Hvsp1HghVltgBsAtvIsltnTstCmmnd : 4|2@1+ (1,0) [0|3] "" Vector__XXX
 SG_ Hvsp1HghVltgBsPssvIsltnTstCmmnd : 6|2@1+ (1,0) [0|3] "" Vector__XXX
 SG_ Hvsp1EnlIntrnlChrgrCmmnd : 10|2@1+ (1,0) [0|3] "" Vector__XXX
 SG_ Hvsp1HVtBsHSdRsstCtRqst : 14|2@1+ (1,0) [0|3] "" Vector__XXX
 SG_ Hvsp1HghVltgBsLwSdRsstrCnntRqst : 16|2@1+ (1,0) [0|3] "" Vector__XXX
 SG_ Hvsp1ThrmlMngmntMntnnRqst : 18|2@1+ (1,0) [0|3] "" Vector__XXX

BO_ 2351693566 HVESP2C1: 8 Vector__XXX
 SG_ Hvesp2PowerDownCommand : 2|2@1+ (1,0) [0|3] "" Vector__XXX
 SG_ Hvesp2CellBalancingCommand : 8|2@1+ (1,0) [0|3] "" Vector__XXX
 SG_ Hvesp2OperationConsent : 12|2@1+ (1,0) [0|3] "" Vector__XXX
 SG_ Hvesp2Control1Counter : 52|4@1+ (1,0) [0|15] "" Vector__XXX
 SG_ Hvesp2Control1Crc : 56|8@1+ (1,0) [0|250] "count" Vector__XXX
 SG_ Hvsp2HghVltgBsCnntCmmnd : 0|2@1+ (1,0) [0|3] "" Vector__XXX
 SG_ Hvsp2HghVltgBsAtvIsltnTstCmmnd : 4|2@1+ (1,0) [0|3] "" Vector__XXX
 SG_ Hvsp2HghVltgBsPssvIsltnTstCmmnd : 6|2@1+ (1,0) [0|3] "" Vector__XXX
 SG_ Hvsp2EnlIntrnlChrgrCmmnd : 10|2@1+ (1,0) [0|3] "" Vector__XXX
 SG_ Hvsp2HVtBsHSdRsstCtRqst : 14|2@1+ (1,0) [0|3] "" Vector__XXX
 SG_ Hvsp2HghVltgBsLwSdRsstrCnntRqst : 16|2@1+ (1,0) [0|3] "" Vector__XXX
 SG_ Hvsp2ThrmlMngmntMntnnRqst : 18|2@1+ (1,0) [0|3] "" Vector__XXX

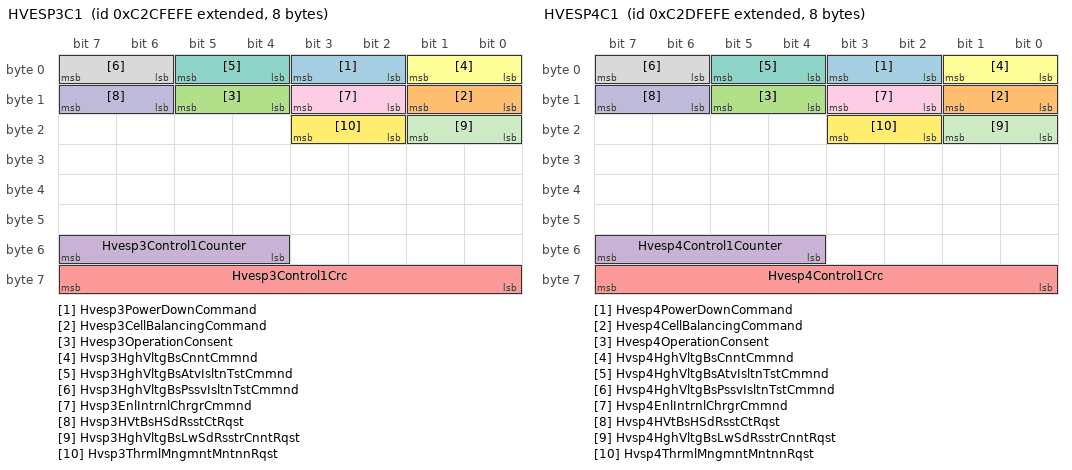
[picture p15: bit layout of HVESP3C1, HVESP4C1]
BO_ 2351759102 HVESP3C1: 8 Vector__XXX
 SG_ Hvesp3PowerDownCommand : 2|2@1+ (1,0) [0|3] "" Vector__XXX
 SG_ Hvesp3CellBalancingCommand : 8|2@1+ (1,0) [0|3] "" Vector__XXX
 SG_ Hvesp3OperationConsent : 12|2@1+ (1,0) [0|3] "" Vector__XXX
 SG_ Hvesp3Control1Counter : 52|4@1+ (1,0) [0|15] "" Vector__XXX
 SG_ Hvesp3Control1Crc : 56|8@1+ (1,0) [0|250] "count" Vector__XXX
 SG_ Hvsp3HghVltgBsCnntCmmnd : 0|2@1+ (1,0) [0|3] "" Vector__XXX
 SG_ Hvsp3HghVltgBsAtvIsltnTstCmmnd : 4|2@1+ (1,0) [0|3] "" Vector__XXX
 SG_ Hvsp3HghVltgBsPssvIsltnTstCmmnd : 6|2@1+ (1,0) [0|3] "" Vector__XXX
 SG_ Hvsp3EnlIntrnlChrgrCmmnd : 10|2@1+ (1,0) [0|3] "" Vector__XXX
 SG_ Hvsp3HVtBsHSdRsstCtRqst : 14|2@1+ (1,0) [0|3] "" Vector__XXX
 SG_ Hvsp3HghVltgBsLwSdRsstrCnntRqst : 16|2@1+ (1,0) [0|3] "" Vector__XXX
 SG_ Hvsp3ThrmlMngmntMntnnRqst : 18|2@1+ (1,0) [0|3] "" Vector__XXX

BO_ 2351824638 HVESP4C1: 8 Vector__XXX
 SG_ Hvesp4PowerDownCommand : 2|2@1+ (1,0) [0|3] "" Vector__XXX
 SG_ Hvesp4CellBalancingCommand : 8|2@1+ (1,0) [0|3] "" Vector__XXX
 SG_ Hvesp4OperationConsent : 12|2@1+ (1,0) [0|3] "" Vector__XXX
 SG_ Hvesp4Control1Counter : 52|4@1+ (1,0) [0|15] "" Vector__XXX
 SG_ Hvesp4Control1Crc : 56|8@1+ (1,0) [0|250] "count" Vector__XXX
 SG_ Hvsp4HghVltgBsCnntCmmnd : 0|2@1+ (1,0) [0|3] "" Vector__XXX
 SG_ Hvsp4HghVltgBsAtvIsltnTstCmmnd : 4|2@1+ (1,0) [0|3] "" Vector__XXX
 SG_ Hvsp4HghVltgBsPssvIsltnTstCmmnd : 6|2@1+ (1,0) [0|3] "" Vector__XXX
 SG_ Hvsp4EnlIntrnlChrgrCmmnd : 10|2@1+ (1,0) [0|3] "" Vector__XXX
 SG_ Hvsp4HVtBsHSdRsstCtRqst : 14|2@1+ (1,0) [0|3] "" Vector__XXX
 SG_ Hvsp4HghVltgBsLwSdRsstrCnntRqst : 16|2@1+ (1,0) [0|3] "" Vector__XXX
 SG_ Hvsp4ThrmlMngmntMntnnRqst : 18|2@1+ (1,0) [0|3] "" Vector__XXX

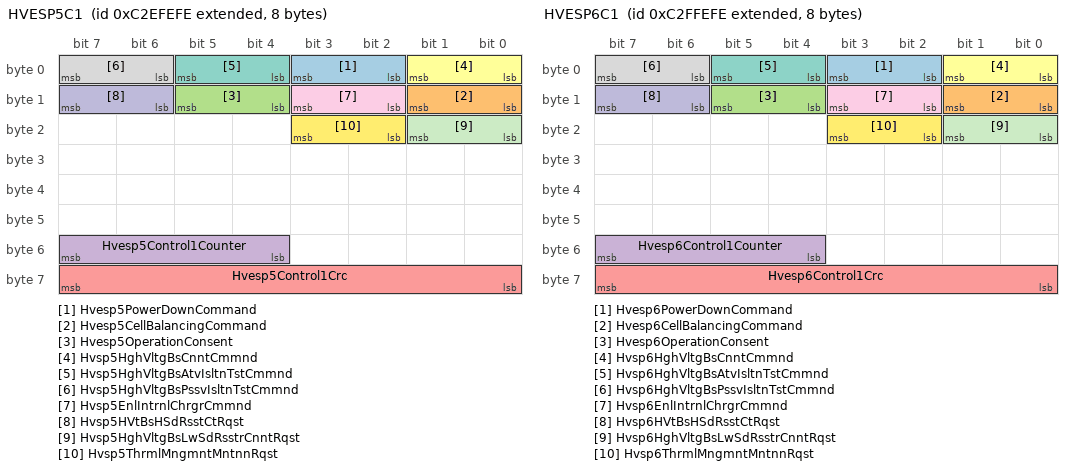
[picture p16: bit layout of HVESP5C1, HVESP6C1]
BO_ 2351890174 HVESP5C1: 8 Vector__XXX
 SG_ Hvesp5PowerDownCommand : 2|2@1+ (1,0) [0|3] "" Vector__XXX
 SG_ Hvesp5CellBalancingCommand : 8|2@1+ (1,0) [0|3] "" Vector__XXX
 SG_ Hvesp5OperationConsent : 12|2@1+ (1,0) [0|3] "" Vector__XXX
 SG_ Hvesp5Control1Counter : 52|4@1+ (1,0) [0|15] "" Vector__XXX
 SG_ Hvesp5Control1Crc : 56|8@1+ (1,0) [0|250] "count" Vector__XXX
 SG_ Hvsp5HghVltgBsCnntCmmnd : 0|2@1+ (1,0) [0|3] "" Vector__XXX
 SG_ Hvsp5HghVltgBsAtvIsltnTstCmmnd : 4|2@1+ (1,0) [0|3] "" Vector__XXX
 SG_ Hvsp5HghVltgBsPssvIsltnTstCmmnd : 6|2@1+ (1,0) [0|3] "" Vector__XXX
 SG_ Hvsp5EnlIntrnlChrgrCmmnd : 10|2@1+ (1,0) [0|3] "" Vector__XXX
 SG_ Hvsp5HVtBsHSdRsstCtRqst : 14|2@1+ (1,0) [0|3] "" Vector__XXX
 SG_ Hvsp5HghVltgBsLwSdRsstrCnntRqst : 16|2@1+ (1,0) [0|3] "" Vector__XXX
 SG_ Hvsp5ThrmlMngmntMntnnRqst : 18|2@1+ (1,0) [0|3] "" Vector__XXX

BO_ 2351955710 HVESP6C1: 8 Vector__XXX
 SG_ Hvesp6PowerDownCommand : 2|2@1+ (1,0) [0|3] "" Vector__XXX
 SG_ Hvesp6CellBalancingCommand : 8|2@1+ (1,0) [0|3] "" Vector__XXX
 SG_ Hvesp6OperationConsent : 12|2@1+ (1,0) [0|3] "" Vector__XXX
 SG_ Hvesp6Control1Counter : 52|4@1+ (1,0) [0|15] "" Vector__XXX
 SG_ Hvesp6Control1Crc : 56|8@1+ (1,0) [0|250] "count" Vector__XXX
 SG_ Hvsp6HghVltgBsCnntCmmnd : 0|2@1+ (1,0) [0|3] "" Vector__XXX
 SG_ Hvsp6HghVltgBsAtvIsltnTstCmmnd : 4|2@1+ (1,0) [0|3] "" Vector__XXX
 SG_ Hvsp6HghVltgBsPssvIsltnTstCmmnd : 6|2@1+ (1,0) [0|3] "" Vector__XXX
 SG_ Hvsp6EnlIntrnlChrgrCmmnd : 10|2@1+ (1,0) [0|3] "" Vector__XXX
 SG_ Hvsp6HVtBsHSdRsstCtRqst : 14|2@1+ (1,0) [0|3] "" Vector__XXX
 SG_ Hvsp6HghVltgBsLwSdRsstrCnntRqst : 16|2@1+ (1,0) [0|3] "" Vector__XXX
 SG_ Hvsp6ThrmlMngmntMntnnRqst : 18|2@1+ (1,0) [0|3] "" Vector__XXX

BO_ 2555641598 EVSEC1: 8 Vector__XXX
 SG_ EvReady : 8|2@1+ (1,0) [0|3] "" Vector__XXX
 SG_ EvseConnectorLockRequest : 0|4@1+ (1,0) [0|15] "" Vector__XXX
 SG_ EvseDcStageRequest : 4|4@1+ (1,0) [0|15] "" Vector__XXX
 SG_ EvseContactorCommand : 10|2@1+ (1,0) [0|3] "" Vector__XXX

BO_ 2555707134 WINCH3: 8 Vector__XXX
 SG_ WinchPositionReset : 0|2@1+ (1,0) [0|3] "" Vector__XXX

BO_ 2354446078 ASC8: 8 Vector__XXX
 SG_ LiftAxle3PositionCommand : 0|2@1+ (1,0) [0|3] "" Vector__XXX

BO_ 2354511614 MG2IC2: 8 Vector__XXX
 SG_ MtrGnrtr2InvrtrCntrl2Cntr : 8|4@1+ (1,0) [0|15] "" Vector__XXX
 SG_ MtrGnrtr2InvrtrCntrl2Cr : 0|8@1+ (1,0) [0|250] "count" Vector__XXX
 SG_ MtrGnrtr2InvrtrPdCntrlAppllMd : 12|4@1+ (1,0) [0|15] "" Vector__XXX
 SG_ MtGt2IvtPdCtNzdDtG : 16|8@1+ (0.03125,0) [0|7.8125] "%/(%/s)" Vector__XXX
 SG_ MtGt2IvtPdCtNzdItG : 24|16@1+ (0.015625,0) [0|1003.984375] "%/(%/s)" Vector__XXX
 SG_ MtGt2IvtPdCtNzdPptG : 40|12@1+ (0.0625,0) [0|250.9375] "%/%" Vector__XXX
 SG_ MtGt2IvtPdCtFdFwdTq : 52|12@1+ (0.0625,-125) [-125|125.9375] "%" Vector__XXX

BO_ 2354577150 MG1IC2: 8 Vector__XXX
 SG_ MtrGnrtr1InvrtrCntrl2Cntr : 8|4@1+ (1,0) [0|15] "" Vector__XXX
 SG_ MtrGnrtr1InvrtrCntrl2Cr : 0|8@1+ (1,0) [0|250] "count" Vector__XXX
 SG_ MtrGnrtr1InvrtrPdCntrlAppllMd : 12|4@1+ (1,0) [0|15] "" Vector__XXX
 SG_ MtGt1IvtPdCtNzdDtG : 16|8@1+ (0.03125,0) [0|7.8125] "%/(%/s)" Vector__XXX
 SG_ MtGt1IvtPdCtNzdItG : 24|16@1+ (0.015625,0) [0|1003.984375] "%/(%/s)" Vector__XXX
 SG_ MtGt1IvtPdCtNzdPptG : 40|12@1+ (0.0625,0) [0|250.9375] "%/%" Vector__XXX
 SG_ MtGt1IvtPdCtFdFwdTq : 52|12@1+ (0.0625,-125) [-125|125.9375] "%" Vector__XXX

BO_ 2488860414 HCI2: 8 Vector__XXX
 SG_ HoistCommand : 0|16@1+ (0.005,-150) [-100|100] "%" Vector__XXX
 SG_ HoistDetentStatus : 16|2@1+ (1,0) [0|3] "" Vector__XXX

BO_ 2556034814 MG2IIR: 8 Vector__XXX
 SG_ MtGt2IvtHVtBsAtvIstTstCd : 0|2@1+ (1,0) [0|3] "" Vector__XXX
 SG_ MtGt2IvtHVtBsPssvIstTstCd : 2|2@1+ (1,0) [0|3] "" Vector__XXX
 SG_ MtGt2IvtHVtBsHSdRsstCtRqst : 4|2@1+ (1,0) [0|3] "" Vector__XXX
 SG_ MtGt2IvtHVtBsLwSdRsstCtRqst : 6|2@1+ (1,0) [0|3] "" Vector__XXX

BO_ 2556100350 MG1IIR: 8 Vector__XXX
 SG_ MtGt1IvtHVtBsAtvIstTstCd : 0|2@1+ (1,0) [0|3] "" Vector__XXX
 SG_ MtGt1IvtHVtBsPssvIstTstCd : 2|2@1+ (1,0) [0|3] "" Vector__XXX
 SG_ MtGt1IvtHVtBsHSdRsstCtRqst : 4|2@1+ (1,0) [0|3] "" Vector__XXX
 SG_ MtGt1IvtHVtBsLwSdRsstCtRqst : 6|2@1+ (1,0) [0|3] "" Vector__XXX

BO_ 2565966846 MG1IS2: 8 Vector__XXX
 SG_ MtrGnrtr1InvrtrStts2Cntr : 8|4@1+ (1,0) [0|15] "" Vector__XXX
 SG_ MtrGnrtr1AvllMxmmTrq : 12|12@1+ (0.0625,-125) [-125|125.9375] "%" Vector__XXX
 SG_ MtrGnrtr1AvllMnmmTrq : 24|12@1+ (0.0625,-125) [-125|125.9375] "%" Vector__XXX
 SG_ MtrGnrtr1InvrtrStts2Cr : 0|8@1+ (1,0) [0|250] "count" Vector__XXX

BO_ 2565967102 MG1IRLA1: 8 Vector__XXX
 SG_ MtrGnrtr1InvrtrRtLmtsAtv1Cntr : 8|4@1+ (1,0) [0|15] "" Vector__XXX
 SG_ MtGt1IvtRtLtsAtvAstSpdRtLt : 12|12@1+ (0.25,0) [0|1003.75] "%/s" Vector__XXX
 SG_ MtGt1IvtRtLtsAtvAstTqRtLt : 24|12@1+ (2,0) [0|8030] "%/s" Vector__XXX
 SG_ MtrGnrtr1InvrtrRtLmtsAtv1Cr : 0|8@1+ (1,0) [0|250] "count" Vector__XXX

BO_ 2565967358 MG2IS2: 8 Vector__XXX
 SG_ MtrGnrtr2InvrtrStts2Cntr : 8|4@1+ (1,0) [0|15] "" Vector__XXX
 SG_ MtrGnrtr2AvllMxmmTrq : 12|12@1+ (0.0625,-125) [-125|125.9375] "%" Vector__XXX
 SG_ MtrGnrtr2AvllMnmmTrq : 24|12@1+ (0.0625,-125) [-125|125.9375] "%" Vector__XXX
 SG_ MtrGnrtr2InvrtrStts2Cr : 0|8@1+ (1,0) [0|250] "count" Vector__XXX

BO_ 2565967614 MG2IRLA1: 8 Vector__XXX
 SG_ MtrGnrtr2InvrtrRtLmtsAtv1Cntr : 8|4@1+ (1,0) [0|15] "" Vector__XXX
 SG_ MtGt2IvtRtLtsAtvAstSpdRtLt : 12|12@1+ (0.25,0) [0|1003.75] "%/s" Vector__XXX
 SG_ MtGt2IvtRtLtsAtvAstTqRtLt : 24|12@1+ (2,0) [0|8030] "%/s" Vector__XXX
 SG_ MtrGnrtr2InvrtrRtLmtsAtv1Cr : 0|8@1+ (1,0) [0|250] "count" Vector__XXX

BO_ 2297532414 IPGA: 8 Vector__XXX
 SG_ ImpostorPgEventDetectionCounter : 0|8@1+ (1,0) [0|250] "count" Vector__XXX
 SG_ ImpostorPgSourceAddress : 8|8@1+ (1,0) [0|250] "sourceadr" Vector__XXX
 SG_ ImpostorPgDestinationAddress : 16|8@1+ (1,0) [0|250] "sourceadr" Vector__XXX
 SG_ ImpostorPgn : 24|24@1+ (1,0) [0|16449535] "" Vector__XXX
 SG_ TimeSinceLastImpostorPgDetected : 48|8@1+ (1,0) [0|250] "min" Vector__XXX

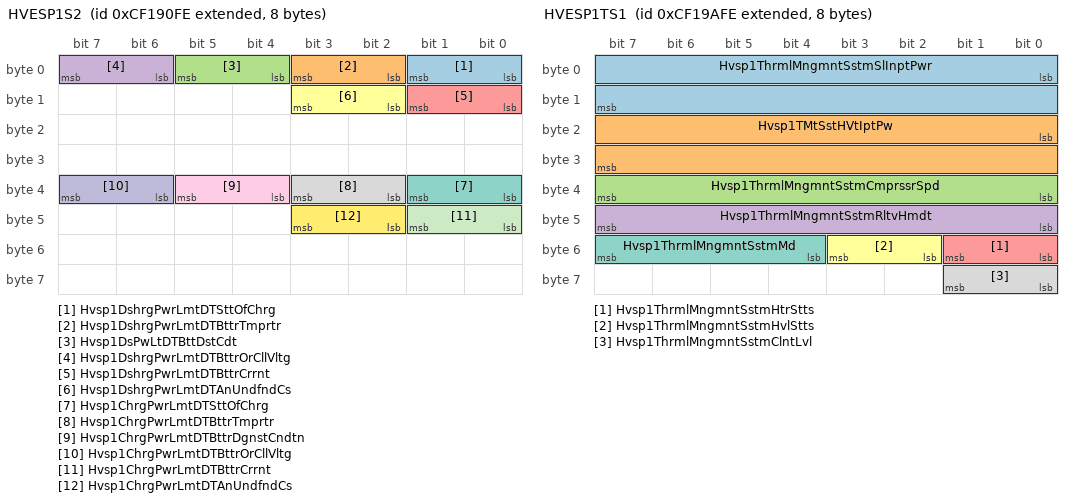
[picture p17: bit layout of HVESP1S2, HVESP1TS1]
BO_ 2364641534 HVESP1S2: 8 Vector__XXX
 SG_ Hvsp1DshrgPwrLmtDTSttOfChrg : 0|2@1+ (1,0) [0|3] "" Vector__XXX
 SG_ Hvsp1DshrgPwrLmtDTBttrTmprtr : 2|2@1+ (1,0) [0|3] "" Vector__XXX
 SG_ Hvsp1DsPwLtDTBttDstCdt : 4|2@1+ (1,0) [0|3] "" Vector__XXX
 SG_ Hvsp1DshrgPwrLmtDTBttrOrCllVltg : 6|2@1+ (1,0) [0|3] "" Vector__XXX
 SG_ Hvsp1DshrgPwrLmtDTBttrCrrnt : 8|2@1+ (1,0) [0|3] "" Vector__XXX
 SG_ Hvsp1DshrgPwrLmtDTAnUndfndCs : 10|2@1+ (1,0) [0|3] "" Vector__XXX
 SG_ Hvsp1ChrgPwrLmtDTSttOfChrg : 32|2@1+ (1,0) [0|3] "" Vector__XXX
 SG_ Hvsp1ChrgPwrLmtDTBttrTmprtr : 34|2@1+ (1,0) [0|3] "" Vector__XXX
 SG_ Hvsp1ChrgPwrLmtDTBttrDgnstCndtn : 36|2@1+ (1,0) [0|3] "" Vector__XXX
 SG_ Hvsp1ChrgPwrLmtDTBttrOrCllVltg : 38|2@1+ (1,0) [0|3] "" Vector__XXX
 SG_ Hvsp1ChrgPwrLmtDTBttrCrrnt : 40|2@1+ (1,0) [0|3] "" Vector__XXX
 SG_ Hvsp1ChrgPwrLmtDTAnUndfndCs : 42|2@1+ (1,0) [0|3] "" Vector__XXX

BO_ 2364641790 HVESP1D1: 8 Vector__XXX
 SG_ Hvesp1AvailableDischargePower : 0|16@1+ (0.05,0) [0|3212.75] "kW" Vector__XXX
 SG_ Hvesp1AvailableChargePower : 16|16@1+ (0.05,0) [0|3212.75] "kW" Vector__XXX
 SG_ Hvesp1VoltageLevel : 32|16@1+ (0.05,0) [0|3212.75] "V" Vector__XXX
 SG_ Hvesp1Current : 48|16@1+ (0.05,-1600) [-1600|1612.75] "A" Vector__XXX

BO_ 2364642046 HVESP1D2: 8 Vector__XXX
 SG_ Hvesp1FastUpdateStateOfCharge : 0|16@1+ (0.0015625,0) [0|100.3984375] "%" Vector__XXX
 SG_ Hvesp1HighestCellVoltage : 16|16@1+ (0.001,0) [0|64.255] "V" Vector__XXX
 SG_ Hvesp1LowestCellVoltage : 32|16@1+ (0.001,0) [0|64.255] "V" Vector__XXX
 SG_ Hvsp1CllVltgDffrntlStts : 48|4@1+ (1,0) [0|15] "" Vector__XXX

BO_ 2364642302 HVESP1D3: 8 Vector__XXX
 SG_ Hvesp1HighestCellTemperature : 0|16@1+ (0.03125,-273) [-273|1734.96875] "degC" Vector__XXX
 SG_ Hvesp1LowestCellTemperature : 16|16@1+ (0.03125,-273) [-273|1734.96875] "degC" Vector__XXX
 SG_ Hvesp1AverageCellTemperature : 32|16@1+ (0.03125,-273) [-273|1734.96875] "degC" Vector__XXX
 SG_ Hvsp1CllTmprtrDffrntlStts : 48|2@1+ (1,0) [0|3] "" Vector__XXX

BO_ 2364642558 HVESP1D4: 8 Vector__XXX
 SG_ Hvesp1DischargeCapacity : 0|16@1+ (0.01,0) [0|642.55] "Ah" Vector__XXX
 SG_ Hvesp1ChargeCapacity : 16|16@1+ (0.01,0) [0|642.55] "Ah" Vector__XXX
 SG_ Hvesp1CellBalancingCount : 32|16@1+ (1,0) [0|64255] "count" Vector__XXX

BO_ 2364642814 HVESP1D5: 8 Vector__XXX
 SG_ Hvesp1LowestCellStateOfCharge : 32|16@1+ (0.0015625,0) [0|100.3984375] "%" Vector__XXX
 SG_ Hvesp1HighestCellStateOfCharge : 48|16@1+ (0.0015625,0) [0|100.3984375] "%" Vector__XXX
 SG_ Hvsp1MxmmInstntnsDshrgCrrntLmt : 0|16@1+ (0.05,-1600) [-1600|0] "A" Vector__XXX
 SG_ Hvsp1MxmmInstntnsChrgCrrntLmt : 16|16@1+ (0.05,-1600) [0|1612.75] "A" Vector__XXX

BO_ 2364643070 HVESP1D6: 8 Vector__XXX
 SG_ Hvesp1BusVoltage : 0|16@1+ (0.05,0) [0|3212.75] "V" Vector__XXX
 SG_ Hvesp1IgnitionVoltage : 16|16@1+ (0.01,0) [0|642.55] "V" Vector__XXX
 SG_ Hvesp1IntakeCoolantTemperature : 32|8@1+ (1,-40) [-40|210] "degC" Vector__XXX
 SG_ Hvesp1OutletCoolantTemperature : 40|8@1+ (1,-40) [-40|210] "degC" Vector__XXX
 SG_ Hvesp1ElectronicsTemperature : 48|8@1+ (1,-40) [-40|210] "degC" Vector__XXX
 SG_ Hvesp1Temperature : 56|8@1+ (1,-40) [-40|210] "degC" Vector__XXX

BO_ 2364643326 HVESP1S1: 8 Vector__XXX
 SG_ Hvesp1HvilStatus : 20|2@1+ (1,0) [0|3] "" Vector__XXX
 SG_ Hvesp1InertiaSwitchStatus : 22|2@1+ (1,0) [0|3] "" Vector__XXX
 SG_ Hvesp1StateOfChargeStatus : 24|4@1+ (1,0) [0|15] "" Vector__XXX
 SG_ Hvesp1CellBalanceStatus : 28|2@1+ (1,0) [0|3] "" Vector__XXX
 SG_ Hvesp1CellBalancingActive : 30|2@1+ (1,0) [0|3] "" Vector__XXX
 SG_ Hvesp1InternalChargerStatus : 32|2@1+ (1,0) [0|3] "" Vector__XXX
 SG_ Hvesp1OperationalStatus : 44|4@1+ (1,0) [0|15] "" Vector__XXX
 SG_ Hvesp1Status1Counter : 52|4@1+ (1,0) [0|15] "" Vector__XXX
 SG_ Hvesp1Status1Crc : 56|8@1+ (1,0) [0|250] "count" Vector__XXX
 SG_ Hvsp1HghVltgBsPstvCnttrStt : 0|2@1+ (1,0) [0|3] "" Vector__XXX
 SG_ Hvsp1HghVltgBsNgtvCnttrStt : 2|2@1+ (1,0) [0|3] "" Vector__XXX
 SG_ Hvsp1HghVltgBsDsnntFrwrnng : 4|4@1+ (1,0) [0|15] "" Vector__XXX
 SG_ Hvsp1HghVltgBsPrChrgRlStt : 8|2@1+ (1,0) [0|3] "" Vector__XXX
 SG_ Hvsp1CntrOfPkCnttrStt : 10|2@1+ (1,0) [0|3] "" Vector__XXX
 SG_ Hvsp1HghVltgBsAtvIsltnTstStts : 12|4@1+ (1,0) [0|15] "" Vector__XXX
 SG_ Hvsp1HghVltgBsPssvIsltnTstStts : 16|4@1+ (1,0) [0|15] "" Vector__XXX
 SG_ Hvsp1HghVltgBsCnntnStts : 40|4@1+ (1,0) [0|15] "" Vector__XXX

BO_ 2364643582 HVESP1D7: 8 Vector__XXX
 SG_ Hvesp1DischargeEnergyCapacity : 0|24@1+ (0.001,0) [0|16449.535] "kWh" Vector__XXX
 SG_ Hvesp1ChargeEnergyCapacity : 24|24@1+ (0.001,0) [0|16449.535] "kWh" Vector__XXX
 SG_ Hvesp1MaximumChargeVoltageLimit : 48|16@1+ (0.05,0) [0|3212.75] "V" Vector__XXX

BO_ 2364643838 HVESP1MS1: 8 Vector__XXX
 SG_ Hvesp1Module1OperationalStatus : 0|2@1+ (1,0) [0|3] "" Vector__XXX
 SG_ Hvesp1Module2OperationalStatus : 2|2@1+ (1,0) [0|3] "" Vector__XXX
 SG_ Hvesp1Module3OperationalStatus : 4|2@1+ (1,0) [0|3] "" Vector__XXX
 SG_ Hvesp1Module4OperationalStatus : 6|2@1+ (1,0) [0|3] "" Vector__XXX
 SG_ Hvesp1Module5OperationalStatus : 8|2@1+ (1,0) [0|3] "" Vector__XXX
 SG_ Hvesp1Module6OperationalStatus : 10|2@1+ (1,0) [0|3] "" Vector__XXX
 SG_ Hvesp1Module7OperationalStatus : 12|2@1+ (1,0) [0|3] "" Vector__XXX
 SG_ Hvesp1Module8OperationalStatus : 14|2@1+ (1,0) [0|3] "" Vector__XXX
 SG_ Hvesp1Module9OperationalStatus : 16|2@1+ (1,0) [0|3] "" Vector__XXX
 SG_ Hvesp1Module10OperationalStatus : 18|2@1+ (1,0) [0|3] "" Vector__XXX
 SG_ Hvesp1Module11OperationalStatus : 20|2@1+ (1,0) [0|3] "" Vector__XXX
 SG_ Hvesp1Module12OperationalStatus : 22|2@1+ (1,0) [0|3] "" Vector__XXX
 SG_ Hvesp1Module13OperationalStatus : 24|2@1+ (1,0) [0|3] "" Vector__XXX
 SG_ Hvesp1Module14OperationalStatus : 26|2@1+ (1,0) [0|3] "" Vector__XXX
 SG_ Hvesp1Module15OperationalStatus : 28|2@1+ (1,0) [0|3] "" Vector__XXX
 SG_ Hvesp1Module16OperationalStatus : 30|2@1+ (1,0) [0|3] "" Vector__XXX
 SG_ Hvesp1Module17OperationalStatus : 32|2@1+ (1,0) [0|3] "" Vector__XXX
 SG_ Hvesp1Module18OperationalStatus : 34|2@1+ (1,0) [0|3] "" Vector__XXX
 SG_ Hvesp1Module19OperationalStatus : 36|2@1+ (1,0) [0|3] "" Vector__XXX
 SG_ Hvesp1Module20OperationalStatus : 38|2@1+ (1,0) [0|3] "" Vector__XXX
 SG_ Hvesp1Module21OperationalStatus : 40|2@1+ (1,0) [0|3] "" Vector__XXX
 SG_ Hvesp1Module22OperationalStatus : 42|2@1+ (1,0) [0|3] "" Vector__XXX
 SG_ Hvesp1Module23OperationalStatus : 44|2@1+ (1,0) [0|3] "" Vector__XXX
 SG_ Hvesp1Module24OperationalStatus : 46|2@1+ (1,0) [0|3] "" Vector__XXX
 SG_ Hvesp1Module25OperationalStatus : 48|2@1+ (1,0) [0|3] "" Vector__XXX
 SG_ Hvesp1Module26OperationalStatus : 50|2@1+ (1,0) [0|3] "" Vector__XXX
 SG_ Hvesp1Module27OperationalStatus : 52|2@1+ (1,0) [0|3] "" Vector__XXX
 SG_ Hvesp1Module28OperationalStatus : 54|2@1+ (1,0) [0|3] "" Vector__XXX
 SG_ Hvesp1Module29OperationalStatus : 56|2@1+ (1,0) [0|3] "" Vector__XXX
 SG_ Hvesp1Module30OperationalStatus : 58|2@1+ (1,0) [0|3] "" Vector__XXX
 SG_ Hvesp1Module31OperationalStatus : 60|2@1+ (1,0) [0|3] "" Vector__XXX
 SG_ Hvesp1Module32OperationalStatus : 62|2@1+ (1,0) [0|3] "" Vector__XXX

BO_ 2364644094 HVESP1TS1: 8 Vector__XXX
 SG_ Hvsp1ThrmlMngmntSstmSlInptPwr : 0|16@1+ (0.5,0) [0|32127.5] "W" Vector__XXX
 SG_ Hvsp1TMtSstHVtIptPw : 16|16@1+ (0.5,0) [0|32127.5] "W" Vector__XXX
 SG_ Hvsp1ThrmlMngmntSstmCmprssrSpd : 32|8@1+ (32,0) [0|8000] "rpm" Vector__XXX
 SG_ Hvsp1ThrmlMngmntSstmRltvHmdt : 40|8@1+ (0.4,0) [0|100] "%" Vector__XXX
 SG_ Hvsp1ThrmlMngmntSstmHtrStts : 48|2@1+ (1,0) [0|3] "" Vector__XXX
 SG_ Hvsp1ThrmlMngmntSstmHvlStts : 50|2@1+ (1,0) [0|3] "" Vector__XXX
 SG_ Hvsp1ThrmlMngmntSstmMd : 52|4@1+ (1,0) [0|15] "" Vector__XXX
 SG_ Hvsp1ThrmlMngmntSstmClntLvl : 56|2@1+ (1,0) [0|3] "" Vector__XXX

BO_ 2364644350 HVESP1D8: 8 Vector__XXX
 SG_ Hvesp1AverageCellVoltage : 32|16@1+ (0.001,0) [0|64.255] "V" Vector__XXX
 SG_ Hvsp1HghstCllVltgMdlNmr : 0|8@1+ (1,0) [0|250] "count" Vector__XXX
 SG_ Hvsp1HghstCllVltgCllNmr : 8|8@1+ (1,0) [0|250] "count" Vector__XXX
 SG_ Hvsp1LwstCllVltgMdlNmr : 16|8@1+ (1,0) [0|250] "count" Vector__XXX
 SG_ Hvsp1LwstCllVltgCllNmr : 24|8@1+ (1,0) [0|250] "count" Vector__XXX

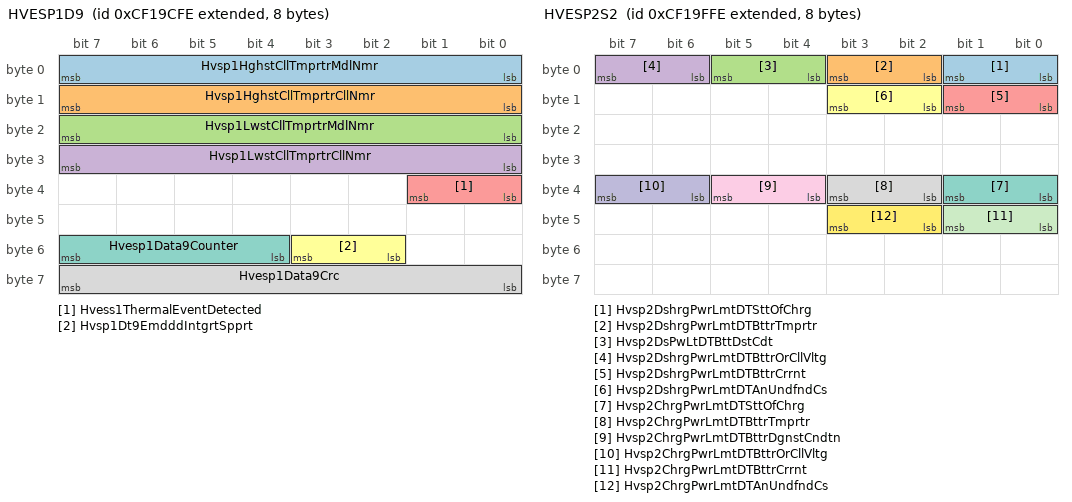
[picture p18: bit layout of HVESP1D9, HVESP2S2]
BO_ 2364644606 HVESP1D9: 8 Vector__XXX
 SG_ Hvsp1HghstCllTmprtrMdlNmr : 0|8@1+ (1,0) [0|250] "count" Vector__XXX
 SG_ Hvsp1HghstCllTmprtrCllNmr : 8|8@1+ (1,0) [0|250] "count" Vector__XXX
 SG_ Hvsp1LwstCllTmprtrMdlNmr : 16|8@1+ (1,0) [0|250] "count" Vector__XXX
 SG_ Hvsp1LwstCllTmprtrCllNmr : 24|8@1+ (1,0) [0|250] "count" Vector__XXX
 SG_ Hvess1ThermalEventDetected : 32|2@1+ (1,0) [0|3] "" Vector__XXX
 SG_ Hvsp1Dt9EmdddIntgrtSpprt : 50|2@1+ (1,0) [0|3] "" Vector__XXX
 SG_ Hvesp1Data9Counter : 52|4@1+ (1,0) [0|15] "" Vector__XXX
 SG_ Hvesp1Data9Crc : 56|8@1+ (1,0) [0|250] "count" Vector__XXX

BO_ 2364644862 HVESP1D10: 8 Vector__XXX
 SG_ Hvsp1HghstCllSttOfChrgMdlNmr : 0|8@1+ (1,0) [0|250] "count" Vector__XXX
 SG_ Hvsp1HghstCllSttOfChrgCllNmr : 8|8@1+ (1,0) [0|250] "count" Vector__XXX
 SG_ Hvsp1LwstCllSttOfChrgMdlNmr : 16|8@1+ (1,0) [0|250] "count" Vector__XXX
 SG_ Hvsp1LwstCllSttOfChrgCllNmr : 24|8@1+ (1,0) [0|250] "count" Vector__XXX
 SG_ Hvsp1HghVltgBsAtvIsltnTstRslts : 32|16@1+ (0.1,0) [0|6425.5] "OhmPerV" Vector__XXX
 SG_ Hvsp1HghVltgBsPssvIsltnTstRslts : 48|16@1+ (0.1,0) [0|6425.5] "OhmPerV" Vector__XXX

BO_ 2364645118 HVESP1D11: 8 Vector__XXX
 SG_ Hvesp1ActualChargeRate : 32|16@1+ (0.05,0) [0|3212.75] "kW" Vector__XXX
 SG_ Hvsp1BsVltgNgtvTChsssGrndVltg : 0|16@1+ (0.05,0) [0|3212.75] "V" Vector__XXX
 SG_ Hvsp1VltgLvlNgtvTChsssGrndVltg : 16|16@1+ (0.05,0) [0|3212.75] "V" Vector__XXX

BO_ 2364645374 HVESP2S2: 8 Vector__XXX
 SG_ Hvsp2DshrgPwrLmtDTSttOfChrg : 0|2@1+ (1,0) [0|3] "" Vector__XXX
 SG_ Hvsp2DshrgPwrLmtDTBttrTmprtr : 2|2@1+ (1,0) [0|3] "" Vector__XXX
 SG_ Hvsp2DsPwLtDTBttDstCdt : 4|2@1+ (1,0) [0|3] "" Vector__XXX
 SG_ Hvsp2DshrgPwrLmtDTBttrOrCllVltg : 6|2@1+ (1,0) [0|3] "" Vector__XXX
 SG_ Hvsp2DshrgPwrLmtDTBttrCrrnt : 8|2@1+ (1,0) [0|3] "" Vector__XXX
 SG_ Hvsp2DshrgPwrLmtDTAnUndfndCs : 10|2@1+ (1,0) [0|3] "" Vector__XXX
 SG_ Hvsp2ChrgPwrLmtDTSttOfChrg : 32|2@1+ (1,0) [0|3] "" Vector__XXX
 SG_ Hvsp2ChrgPwrLmtDTBttrTmprtr : 34|2@1+ (1,0) [0|3] "" Vector__XXX
 SG_ Hvsp2ChrgPwrLmtDTBttrDgnstCndtn : 36|2@1+ (1,0) [0|3] "" Vector__XXX
 SG_ Hvsp2ChrgPwrLmtDTBttrOrCllVltg : 38|2@1+ (1,0) [0|3] "" Vector__XXX
 SG_ Hvsp2ChrgPwrLmtDTBttrCrrnt : 40|2@1+ (1,0) [0|3] "" Vector__XXX
 SG_ Hvsp2ChrgPwrLmtDTAnUndfndCs : 42|2@1+ (1,0) [0|3] "" Vector__XXX

BO_ 2364645630 HVESP2D1: 8 Vector__XXX
 SG_ Hvesp2AvailableDischargePower : 0|16@1+ (0.05,0) [0|3212.75] "kW" Vector__XXX
 SG_ Hvesp2AvailableChargePower : 16|16@1+ (0.05,0) [0|3212.75] "kW" Vector__XXX
 SG_ Hvesp2VoltageLevel : 32|16@1+ (0.05,0) [0|3212.75] "V" Vector__XXX
 SG_ Hvesp2Current : 48|16@1+ (0.05,-1600) [-1600|1612.75] "A" Vector__XXX

BO_ 2364645886 HVESP2D2: 8 Vector__XXX
 SG_ Hvesp2FastUpdateStateOfCharge : 0|16@1+ (0.0015625,0) [0|100.3984375] "%" Vector__XXX
 SG_ Hvesp2HighestCellVoltage : 16|16@1+ (0.001,0) [0|64.255] "V" Vector__XXX
 SG_ Hvesp2LowestCellVoltage : 32|16@1+ (0.001,0) [0|64.255] "V" Vector__XXX
 SG_ Hvsp2CllVltgDffrntlStts : 48|4@1+ (1,0) [0|15] "" Vector__XXX

BO_ 2364646142 HVESP2D3: 8 Vector__XXX
 SG_ Hvesp2HighestCellTemperature : 0|16@1+ (0.03125,-273) [-273|1734.96875] "degC" Vector__XXX
 SG_ Hvesp2LowestCellTemperature : 16|16@1+ (0.03125,-273) [-273|1734.96875] "degC" Vector__XXX
 SG_ Hvesp2AverageCellTemperature : 32|16@1+ (0.03125,-273) [-273|1734.96875] "degC" Vector__XXX
 SG_ Hvsp2CllTmprtrDffrntlStts : 48|2@1+ (1,0) [0|3] "" Vector__XXX

BO_ 2364646398 HVESP2D4: 8 Vector__XXX
 SG_ Hvesp2DischargeCapacity : 0|16@1+ (0.01,0) [0|642.55] "Ah" Vector__XXX
 SG_ Hvesp2ChargeCapacity : 16|16@1+ (0.01,0) [0|642.55] "Ah" Vector__XXX
 SG_ Hvesp2CellBalancingCount : 32|16@1+ (1,0) [0|64255] "count" Vector__XXX

BO_ 2364646654 HVESP2D5: 8 Vector__XXX
 SG_ Hvesp2LowestCellStateOfCharge : 32|16@1+ (0.0015625,0) [0|100.3984375] "%" Vector__XXX
 SG_ Hvesp2HighestCellStateOfCharge : 48|16@1+ (0.0015625,0) [0|100.3984375] "%" Vector__XXX
 SG_ Hvsp2MxmmInstntnsDshrgCrrntLmt : 0|16@1+ (0.05,-1600) [-1600|0] "A" Vector__XXX
 SG_ Hvsp2MxmmInstntnsChrgCrrntLmt : 16|16@1+ (0.05,-1600) [0|1612.75] "A" Vector__XXX

BO_ 2364646910 HVESP2D6: 8 Vector__XXX
 SG_ Hvesp2BusVoltage : 0|16@1+ (0.05,0) [0|3212.75] "V" Vector__XXX
 SG_ Hvesp2IgnitionVoltage : 16|16@1+ (0.01,0) [0|642.55] "V" Vector__XXX
 SG_ Hvesp2IntakeCoolantTemperature : 32|8@1+ (1,-40) [-40|210] "degC" Vector__XXX
 SG_ Hvesp2OutletCoolantTemperature : 40|8@1+ (1,-40) [-40|210] "degC" Vector__XXX
 SG_ Hvesp2ElectronicsTemperature : 48|8@1+ (1,-40) [-40|210] "degC" Vector__XXX
 SG_ Hvesp2Temperature : 56|8@1+ (1,-40) [-40|210] "degC" Vector__XXX

BO_ 2364647166 HVESP2S1: 8 Vector__XXX
 SG_ Hvesp2HvilStatus : 20|2@1+ (1,0) [0|3] "" Vector__XXX
 SG_ Hvesp2InertiaSwitchStatus : 22|2@1+ (1,0) [0|3] "" Vector__XXX
 SG_ Hvesp2StateOfChargeStatus : 24|4@1+ (1,0) [0|15] "" Vector__XXX
 SG_ Hvesp2CellBalanceStatus : 28|2@1+ (1,0) [0|3] "" Vector__XXX
 SG_ Hvesp2CellBalancingActive : 30|2@1+ (1,0) [0|3] "" Vector__XXX
 SG_ Hvesp2InternalChargerStatus : 32|2@1+ (1,0) [0|3] "" Vector__XXX
 SG_ Hvesp2OperationalStatus : 44|4@1+ (1,0) [0|15] "" Vector__XXX
 SG_ Hvesp2Status1Counter : 52|4@1+ (1,0) [0|15] "" Vector__XXX
 SG_ Hvesp2Status1Crc : 56|8@1+ (1,0) [0|250] "count" Vector__XXX
 SG_ Hvsp2HghVltgBsPstvCnttrStt : 0|2@1+ (1,0) [0|3] "" Vector__XXX
 SG_ Hvsp2HghVltgBsNgtvCnttrStt : 2|2@1+ (1,0) [0|3] "" Vector__XXX
 SG_ Hvsp2HghVltgBsDsnntFrwrnng : 4|4@1+ (1,0) [0|15] "" Vector__XXX
 SG_ Hvsp2HghVltgBsPrChrgRlStt : 8|2@1+ (1,0) [0|3] "" Vector__XXX
 SG_ Hvsp2CntrOfPkCnttrStt : 10|2@1+ (1,0) [0|3] "" Vector__XXX
 SG_ Hvsp2HghVltgBsAtvIsltnTstStts : 12|4@1+ (1,0) [0|15] "" Vector__XXX
 SG_ Hvsp2HghVltgBsPssvIsltnTstStts : 16|4@1+ (1,0) [0|15] "" Vector__XXX
 SG_ Hvsp2HghVltgBsCnntnStts : 40|4@1+ (1,0) [0|15] "" Vector__XXX

BO_ 2364647422 HVESP2D7: 8 Vector__XXX
 SG_ Hvesp2DischargeEnergyCapacity : 0|24@1+ (0.001,0) [0|16449.535] "kWh" Vector__XXX
 SG_ Hvesp2ChargeEnergyCapacity : 24|24@1+ (0.001,0) [0|16449.535] "kWh" Vector__XXX
 SG_ Hvesp2MaximumChargeVoltageLimit : 48|16@1+ (0.05,0) [0|3212.75] "V" Vector__XXX

BO_ 2364647678 HVESP2MS1: 8 Vector__XXX
 SG_ Hvesp2Module1OperationalStatus : 0|2@1+ (1,0) [0|3] "" Vector__XXX
 SG_ Hvesp2Module2OperationalStatus : 2|2@1+ (1,0) [0|3] "" Vector__XXX
 SG_ Hvesp2Module3OperationalStatus : 4|2@1+ (1,0) [0|3] "" Vector__XXX
 SG_ Hvesp2Module4OperationalStatus : 6|2@1+ (1,0) [0|3] "" Vector__XXX
 SG_ Hvesp2Module5OperationalStatus : 8|2@1+ (1,0) [0|3] "" Vector__XXX
 SG_ Hvesp2Module6OperationalStatus : 10|2@1+ (1,0) [0|3] "" Vector__XXX
 SG_ Hvesp2Module7OperationalStatus : 12|2@1+ (1,0) [0|3] "" Vector__XXX
 SG_ Hvesp2Module8OperationalStatus : 14|2@1+ (1,0) [0|3] "" Vector__XXX
 SG_ Hvesp2Module9OperationalStatus : 16|2@1+ (1,0) [0|3] "" Vector__XXX
 SG_ Hvesp2Module10OperationalStatus : 18|2@1+ (1,0) [0|3] "" Vector__XXX
 SG_ Hvesp2Module11OperationalStatus : 20|2@1+ (1,0) [0|3] "" Vector__XXX
 SG_ Hvesp2Module12OperationalStatus : 22|2@1+ (1,0) [0|3] "" Vector__XXX
 SG_ Hvesp2Module13OperationalStatus : 24|2@1+ (1,0) [0|3] "" Vector__XXX
 SG_ Hvesp2Module14OperationalStatus : 26|2@1+ (1,0) [0|3] "" Vector__XXX
 SG_ Hvesp2Module15OperationalStatus : 28|2@1+ (1,0) [0|3] "" Vector__XXX
 SG_ Hvesp2Module16OperationalStatus : 30|2@1+ (1,0) [0|3] "" Vector__XXX
 SG_ Hvesp2Module17OperationalStatus : 32|2@1+ (1,0) [0|3] "" Vector__XXX
 SG_ Hvesp2Module18OperationalStatus : 34|2@1+ (1,0) [0|3] "" Vector__XXX
 SG_ Hvesp2Module19OperationalStatus : 36|2@1+ (1,0) [0|3] "" Vector__XXX
 SG_ Hvesp2Module20OperationalStatus : 38|2@1+ (1,0) [0|3] "" Vector__XXX
 SG_ Hvesp2Module21OperationalStatus : 40|2@1+ (1,0) [0|3] "" Vector__XXX
 SG_ Hvesp2Module22OperationalStatus : 42|2@1+ (1,0) [0|3] "" Vector__XXX
 SG_ Hvesp2Module23OperationalStatus : 44|2@1+ (1,0) [0|3] "" Vector__XXX
 SG_ Hvesp2Module24OperationalStatus : 46|2@1+ (1,0) [0|3] "" Vector__XXX
 SG_ Hvesp2Module25OperationalStatus : 48|2@1+ (1,0) [0|3] "" Vector__XXX
 SG_ Hvesp2Module26OperationalStatus : 50|2@1+ (1,0) [0|3] "" Vector__XXX
 SG_ Hvesp2Module27OperationalStatus : 52|2@1+ (1,0) [0|3] "" Vector__XXX
 SG_ Hvesp2Module28OperationalStatus : 54|2@1+ (1,0) [0|3] "" Vector__XXX
 SG_ Hvesp2Module29OperationalStatus : 56|2@1+ (1,0) [0|3] "" Vector__XXX
 SG_ Hvesp2Module30OperationalStatus : 58|2@1+ (1,0) [0|3] "" Vector__XXX
 SG_ Hvesp2Module31OperationalStatus : 60|2@1+ (1,0) [0|3] "" Vector__XXX
 SG_ Hvesp2Module32OperationalStatus : 62|2@1+ (1,0) [0|3] "" Vector__XXX

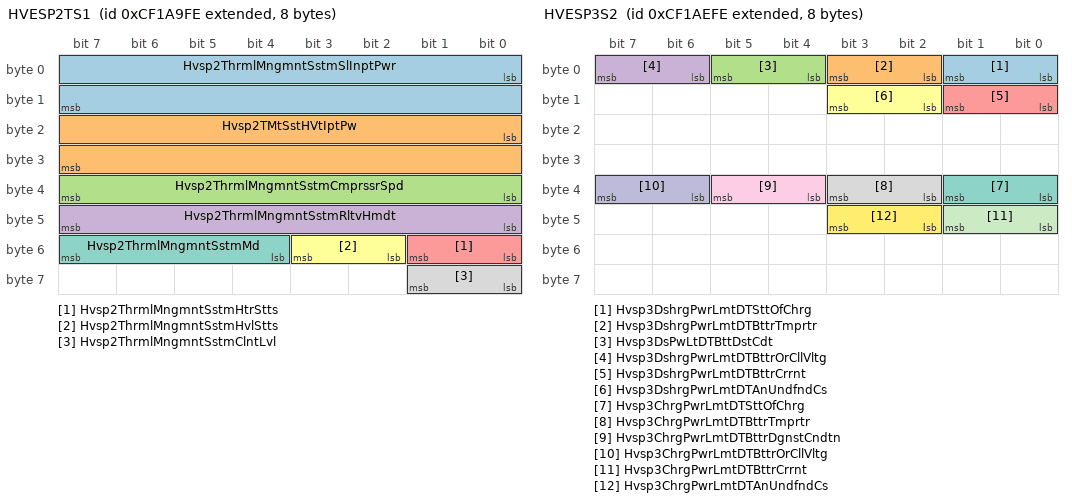
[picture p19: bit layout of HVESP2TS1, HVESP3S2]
BO_ 2364647934 HVESP2TS1: 8 Vector__XXX
 SG_ Hvsp2ThrmlMngmntSstmSlInptPwr : 0|16@1+ (0.5,0) [0|32127.5] "W" Vector__XXX
 SG_ Hvsp2TMtSstHVtIptPw : 16|16@1+ (0.5,0) [0|32127.5] "W" Vector__XXX
 SG_ Hvsp2ThrmlMngmntSstmCmprssrSpd : 32|8@1+ (32,0) [0|8000] "rpm" Vector__XXX
 SG_ Hvsp2ThrmlMngmntSstmRltvHmdt : 40|8@1+ (0.4,0) [0|100] "%" Vector__XXX
 SG_ Hvsp2ThrmlMngmntSstmHtrStts : 48|2@1+ (1,0) [0|3] "" Vector__XXX
 SG_ Hvsp2ThrmlMngmntSstmHvlStts : 50|2@1+ (1,0) [0|3] "" Vector__XXX
 SG_ Hvsp2ThrmlMngmntSstmMd : 52|4@1+ (1,0) [0|15] "" Vector__XXX
 SG_ Hvsp2ThrmlMngmntSstmClntLvl : 56|2@1+ (1,0) [0|3] "" Vector__XXX

BO_ 2364648190 HVESP2D8: 8 Vector__XXX
 SG_ Hvesp2AverageCellVoltage : 32|16@1+ (0.001,0) [0|64.255] "V" Vector__XXX
 SG_ Hvsp2HghstCllVltgMdlNmr : 0|8@1+ (1,0) [0|250] "count" Vector__XXX
 SG_ Hvsp2HghstCllVltgCllNmr : 8|8@1+ (1,0) [0|250] "count" Vector__XXX
 SG_ Hvsp2LwstCllVltgMdlNmr : 16|8@1+ (1,0) [0|250] "count" Vector__XXX
 SG_ Hvsp2LwstCllVltgCllNmr : 24|8@1+ (1,0) [0|250] "count" Vector__XXX

BO_ 2364648446 HVESP2D9: 8 Vector__XXX
 SG_ Hvsp2HghstCllTmprtrMdlNmr : 0|8@1+ (1,0) [0|250] "count" Vector__XXX
 SG_ Hvsp2HghstCllTmprtrCllNmr : 8|8@1+ (1,0) [0|250] "count" Vector__XXX
 SG_ Hvsp2LwstCllTmprtrMdlNmr : 16|8@1+ (1,0) [0|250] "count" Vector__XXX
 SG_ Hvsp2LwstCllTmprtrCllNmr : 24|8@1+ (1,0) [0|250] "count" Vector__XXX
 SG_ Hvess2ThermalEventDetected : 32|2@1+ (1,0) [0|3] "" Vector__XXX
 SG_ Hvsp2Dt9EmdddIntgrtSpprt : 50|2@1+ (1,0) [0|3] "" Vector__XXX
 SG_ Hvesp2Data9Counter : 52|4@1+ (1,0) [0|15] "" Vector__XXX
 SG_ Hvesp2Data9Crc : 56|8@1+ (1,0) [0|250] "count" Vector__XXX

BO_ 2364648702 HVESP2D10: 8 Vector__XXX
 SG_ Hvsp2HghstCllSttOfChrgMdlNmr : 0|8@1+ (1,0) [0|250] "count" Vector__XXX
 SG_ Hvsp2HghstCllSttOfChrgCllNmr : 8|8@1+ (1,0) [0|250] "count" Vector__XXX
 SG_ Hvsp2LwstCllSttOfChrgMdlNmr : 16|8@1+ (1,0) [0|250] "count" Vector__XXX
 SG_ Hvsp2LwstCllSttOfChrgCllNmr : 24|8@1+ (1,0) [0|250] "count" Vector__XXX
 SG_ Hvsp2HghVltgBsAtvIsltnTstRslts : 32|16@1+ (0.1,0) [0|6425.5] "OhmPerV" Vector__XXX
 SG_ Hvsp2HghVltgBsPssvIsltnTstRslts : 48|16@1+ (0.1,0) [0|6425.5] "OhmPerV" Vector__XXX

BO_ 2364648958 HVESP2D11: 8 Vector__XXX
 SG_ Hvesp2ActualChargeRate : 32|16@1+ (0.05,0) [0|3212.75] "kW" Vector__XXX
 SG_ Hvsp2BsVltgNgtvTChsssGrndVltg : 0|16@1+ (0.05,0) [0|3212.75] "V" Vector__XXX
 SG_ Hvsp2VltgLvlNgtvTChsssGrndVltg : 16|16@1+ (0.05,0) [0|3212.75] "V" Vector__XXX

BO_ 2364649214 HVESP3S2: 8 Vector__XXX
 SG_ Hvsp3DshrgPwrLmtDTSttOfChrg : 0|2@1+ (1,0) [0|3] "" Vector__XXX
 SG_ Hvsp3DshrgPwrLmtDTBttrTmprtr : 2|2@1+ (1,0) [0|3] "" Vector__XXX
 SG_ Hvsp3DsPwLtDTBttDstCdt : 4|2@1+ (1,0) [0|3] "" Vector__XXX
 SG_ Hvsp3DshrgPwrLmtDTBttrOrCllVltg : 6|2@1+ (1,0) [0|3] "" Vector__XXX
 SG_ Hvsp3DshrgPwrLmtDTBttrCrrnt : 8|2@1+ (1,0) [0|3] "" Vector__XXX
 SG_ Hvsp3DshrgPwrLmtDTAnUndfndCs : 10|2@1+ (1,0) [0|3] "" Vector__XXX
 SG_ Hvsp3ChrgPwrLmtDTSttOfChrg : 32|2@1+ (1,0) [0|3] "" Vector__XXX
 SG_ Hvsp3ChrgPwrLmtDTBttrTmprtr : 34|2@1+ (1,0) [0|3] "" Vector__XXX
 SG_ Hvsp3ChrgPwrLmtDTBttrDgnstCndtn : 36|2@1+ (1,0) [0|3] "" Vector__XXX
 SG_ Hvsp3ChrgPwrLmtDTBttrOrCllVltg : 38|2@1+ (1,0) [0|3] "" Vector__XXX
 SG_ Hvsp3ChrgPwrLmtDTBttrCrrnt : 40|2@1+ (1,0) [0|3] "" Vector__XXX
 SG_ Hvsp3ChrgPwrLmtDTAnUndfndCs : 42|2@1+ (1,0) [0|3] "" Vector__XXX

BO_ 2364649470 HVESP3D1: 8 Vector__XXX
 SG_ Hvesp3AvailableDischargePower : 0|16@1+ (0.05,0) [0|3212.75] "kW" Vector__XXX
 SG_ Hvesp3AvailableChargePower : 16|16@1+ (0.05,0) [0|3212.75] "kW" Vector__XXX
 SG_ Hvesp3VoltageLevel : 32|16@1+ (0.05,0) [0|3212.75] "V" Vector__XXX
 SG_ Hvesp3Current : 48|16@1+ (0.05,-1600) [-1600|1612.75] "A" Vector__XXX

BO_ 2364649726 HVESP3D2: 8 Vector__XXX
 SG_ Hvesp3FastUpdateStateOfCharge : 0|16@1+ (0.0015625,0) [0|100.3984375] "%" Vector__XXX
 SG_ Hvesp3HighestCellVoltage : 16|16@1+ (0.001,0) [0|64.255] "V" Vector__XXX
 SG_ Hvesp3LowestCellVoltage : 32|16@1+ (0.001,0) [0|64.255] "V" Vector__XXX
 SG_ Hvsp3CllVltgDffrntlStts : 48|4@1+ (1,0) [0|15] "" Vector__XXX

BO_ 2364649982 HVESP3D3: 8 Vector__XXX
 SG_ Hvesp3HighestCellTemperature : 0|16@1+ (0.03125,-273) [-273|1734.96875] "degC" Vector__XXX
 SG_ Hvesp3LowestCellTemperature : 16|16@1+ (0.03125,-273) [-273|1734.96875] "degC" Vector__XXX
 SG_ Hvesp3AverageCellTemperature : 32|16@1+ (0.03125,-273) [-273|1734.96875] "degC" Vector__XXX
 SG_ Hvsp3CllTmprtrDffrntlStts : 48|2@1+ (1,0) [0|3] "" Vector__XXX

BO_ 2364650238 HVESP3D4: 8 Vector__XXX
 SG_ Hvesp3DischargeCapacity : 0|16@1+ (0.01,0) [0|642.55] "Ah" Vector__XXX
 SG_ Hvesp3ChargeCapacity : 16|16@1+ (0.01,0) [0|642.55] "Ah" Vector__XXX
 SG_ Hvesp3CellBalancingCount : 32|16@1+ (1,0) [0|64255] "count" Vector__XXX

BO_ 2364650494 HVESP3D5: 8 Vector__XXX
 SG_ Hvesp3LowestCellStateOfCharge : 32|16@1+ (0.0015625,0) [0|100.3984375] "%" Vector__XXX
 SG_ Hvesp3HighestCellStateOfCharge : 48|16@1+ (0.0015625,0) [0|100.3984375] "%" Vector__XXX
 SG_ Hvsp3MxmmInstntnsDshrgCrrntLmt : 0|16@1+ (0.05,-1600) [-1600|0] "A" Vector__XXX
 SG_ Hvsp3MxmmInstntnsChrgCrrntLmt : 16|16@1+ (0.05,-1600) [0|1612.75] "A" Vector__XXX

BO_ 2364650750 HVESP3D6: 8 Vector__XXX
 SG_ Hvesp3BusVoltage : 0|16@1+ (0.05,0) [0|3212.75] "V" Vector__XXX
 SG_ Hvesp3IgnitionVoltage : 16|16@1+ (0.01,0) [0|642.55] "V" Vector__XXX
 SG_ Hvesp3IntakeCoolantTemperature : 32|8@1+ (1,-40) [-40|210] "degC" Vector__XXX
 SG_ Hvesp3OutletCoolantTemperature : 40|8@1+ (1,-40) [-40|210] "degC" Vector__XXX
 SG_ Hvesp3ElectronicsTemperature : 48|8@1+ (1,-40) [-40|210] "degC" Vector__XXX
 SG_ Hvesp3Temperature : 56|8@1+ (1,-40) [-40|210] "degC" Vector__XXX

BO_ 2364651006 HVESP3S1: 8 Vector__XXX
 SG_ Hvesp3HvilStatus : 20|2@1+ (1,0) [0|3] "" Vector__XXX
 SG_ Hvesp3InertiaSwitchStatus : 22|2@1+ (1,0) [0|3] "" Vector__XXX
 SG_ Hvesp3StateOfChargeStatus : 24|4@1+ (1,0) [0|15] "" Vector__XXX
 SG_ Hvesp3CellBalanceStatus : 28|2@1+ (1,0) [0|3] "" Vector__XXX
 SG_ Hvesp3CellBalancingActive : 30|2@1+ (1,0) [0|3] "" Vector__XXX
 SG_ Hvesp3InternalChargerStatus : 32|2@1+ (1,0) [0|3] "" Vector__XXX
 SG_ Hvesp3OperationalStatus : 44|4@1+ (1,0) [0|15] "" Vector__XXX
 SG_ Hvesp3Status1Counter : 52|4@1+ (1,0) [0|15] "" Vector__XXX
 SG_ Hvesp3Status1Crc : 56|8@1+ (1,0) [0|250] "count" Vector__XXX
 SG_ Hvsp3HghVltgBsPstvCnttrStt : 0|2@1+ (1,0) [0|3] "" Vector__XXX
 SG_ Hvsp3HghVltgBsNgtvCnttrStt : 2|2@1+ (1,0) [0|3] "" Vector__XXX
 SG_ Hvsp3HghVltgBsDsnntFrwrnng : 4|4@1+ (1,0) [0|15] "" Vector__XXX
 SG_ Hvsp3HghVltgBsPrChrgRlStt : 8|2@1+ (1,0) [0|3] "" Vector__XXX
 SG_ Hvsp3CntrOfPkCnttrStt : 10|2@1+ (1,0) [0|3] "" Vector__XXX
 SG_ Hvsp3HghVltgBsAtvIsltnTstStts : 12|4@1+ (1,0) [0|15] "" Vector__XXX
 SG_ Hvsp3HghVltgBsPssvIsltnTstStts : 16|4@1+ (1,0) [0|15] "" Vector__XXX
 SG_ Hvsp3HghVltgBsCnntnStts : 40|4@1+ (1,0) [0|15] "" Vector__XXX

BO_ 2364651262 HVESP3D7: 8 Vector__XXX
 SG_ Hvesp3DischargeEnergyCapacity : 0|24@1+ (0.001,0) [0|16449.535] "kWh" Vector__XXX
 SG_ Hvesp3ChargeEnergyCapacity : 24|24@1+ (0.001,0) [0|16449.535] "kWh" Vector__XXX
 SG_ Hvesp3MaximumChargeVoltageLimit : 48|16@1+ (0.05,0) [0|3212.75] "V" Vector__XXX

BA_DEF_ BO_  "VFrameFormat" ENUM  "StandardCAN","ExtendedCAN","reserved","J1939PG";
BA_DEF_DEF_  "VFrameFormat" "J1939PG";
